VERSION ""

NS_ :

BS_:

BU_: Tester RTM MP5 PEPS BCM IC ACM1 GW

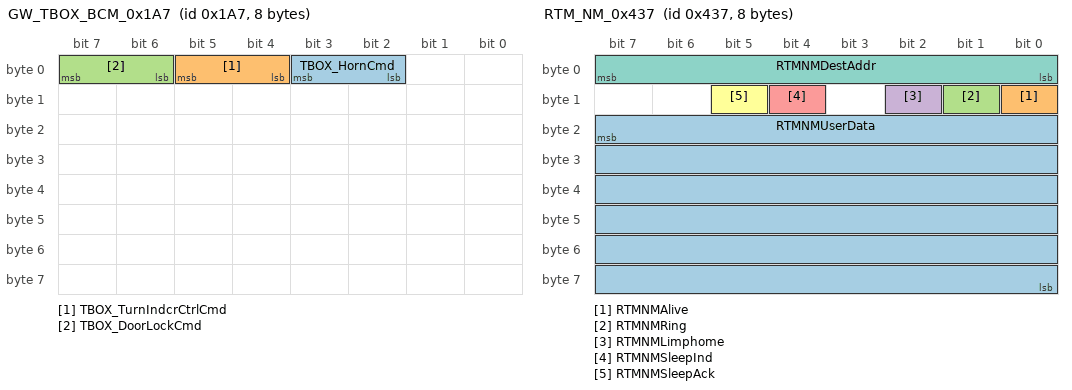
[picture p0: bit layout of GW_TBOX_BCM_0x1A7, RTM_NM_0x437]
BO_ 423 GW_TBOX_BCM_0x1A7: 8 GW
 SG_ TBOX_HornCmd : 3|2@0+ (1,0) [0|3] ""  BCM
 SG_ TBOX_TurnIndcrCtrlCmd : 5|2@0+ (1,0) [0|3] ""  BCM
 SG_ TBOX_DoorLockCmd : 7|2@0+ (1,0) [0|3] ""  BCM

BO_ 1899 GW_TBOXDiagResp: 8 GW
 SG_ DiagRespFromTBOX : 7|64@0+ (1,0) [0|1.844674407371E+019] ""  Tester

BO_ 1891 Tester_DiagReqToTBOX: 8 Tester
 SG_ DiagPhysReqToTBOX : 7|64@0+ (1,0) [0|1.844674407371E+019] ""  GW

BO_ 1851 RTM_DiagResp: 8 RTM
 SG_ DiagRespFromRTM : 7|64@0+ (1,0) [0|1.844674407371E+019] ""  Tester

BO_ 1843 Tester_DiagReqToRTM: 8 Tester
 SG_ DiagPhysReqToRTM : 7|64@0+ (1,0) [0|1.844674407371E+019] ""  RTM

BO_ 1839 MP5_DiagResp: 8 MP5
 SG_ DiagRespFromMP5 : 7|64@0+ (1,0) [0|1.844674407371E+019] ""  Tester

BO_ 1831 Tester_DiagReqToMP5: 8 Tester
 SG_ DiagPhysReqToMP5 : 7|64@0+ (1,0) [0|1.844674407371E+019] ""  MP5

BO_ 1850 PEPS_DiagResp: 8 PEPS
 SG_ DiagRespFromPEPS : 7|64@0+ (1,0) [0|1.844674407371E+019] ""  Tester

BO_ 1842 Tester_DiagReqToPEPS: 8 Tester
 SG_ DiagPhysReqToPEPS : 7|64@0+ (1,0) [0|1.844674407371E+019] ""  PEPS

BO_ 1848 IC_DiagResp: 8 IC
 SG_ DiagRespFromIC : 7|64@0+ (1,0) [0|1.844674407371E+019] ""  Tester

BO_ 1840 Tester_DiagReqToIC: 8 Tester
 SG_ DiagPhysReqToIC : 7|64@0+ (1,0) [0|1.844674407371E+019] ""  IC

BO_ 1865 AC_DiagResp: 8 ACM1
 SG_ DiagRespFromAC : 7|64@0+ (1,0) [0|1.844674407371E+019] ""  Tester

BO_ 1857 Tester_DiagReqToAC: 8 Tester
 SG_ DiagPhysReqToAC : 7|64@0+ (1,0) [0|1.844674407371E+019] ""  ACM1

BO_ 1849 BCM_DiagResp: 8 BCM
 SG_ DiagRespFromBCM : 7|64@0+ (1,0) [0|1.844674407371E+019] ""  Tester

BO_ 1841 Tester_DiagReqToBCM: 8 Tester
 SG_ DiagPhysReqToBCM : 7|64@0+ (1,0) [0|1.844674407371E+019] ""  BCM

BO_ 2015 Tester_DiagFuncReq: 8 Tester
 SG_ DiagFuncReq : 7|64@0+ (1,0) [0|1.844674407371E+019] ""  RTM,MP5,PEPS,BCM,IC,ACM1,GW

BO_ 1079 RTM_NM_0x437: 8 RTM
 SG_ RTMNMUserData : 23|48@0+ (1,0) [0|2.8147E+014] ""  MP5,PEPS,BCM,IC,GW
 SG_ RTMNMAlive : 8|1@0+ (1,0) [0|1] ""  MP5,PEPS,BCM,IC,GW
 SG_ RTMNMRing : 9|1@0+ (1,0) [0|1] ""  MP5,PEPS,BCM,IC,GW
 SG_ RTMNMLimphome : 10|1@0+ (1,0) [0|1] ""  MP5,PEPS,BCM,IC,GW
 SG_ RTMNMSleepInd : 12|1@0+ (1,0) [0|1] ""  MP5,PEPS,BCM,IC,GW
 SG_ RTMNMSleepAck : 13|1@0+ (1,0) [0|1] ""  MP5,PEPS,BCM,IC,GW
 SG_ RTMNMDestAddr : 7|8@0+ (1,0) [0|255] ""  MP5,PEPS,BCM,IC,GW

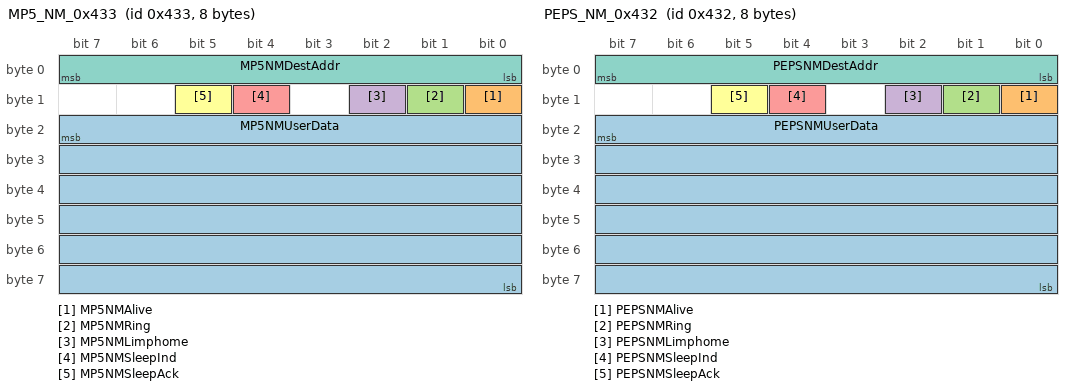
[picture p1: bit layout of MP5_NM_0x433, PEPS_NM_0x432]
BO_ 1075 MP5_NM_0x433: 8 MP5
 SG_ MP5NMUserData : 23|48@0+ (1,0) [0|2.8147E+014] ""  RTM,PEPS,BCM,IC,GW
 SG_ MP5NMAlive : 8|1@0+ (1,0) [0|1] ""  RTM,PEPS,BCM,IC,GW
 SG_ MP5NMRing : 9|1@0+ (1,0) [0|1] ""  RTM,PEPS,BCM,IC,GW
 SG_ MP5NMLimphome : 10|1@0+ (1,0) [0|1] ""  RTM,PEPS,BCM,IC,GW
 SG_ MP5NMSleepInd : 12|1@0+ (1,0) [0|1] ""  RTM,PEPS,BCM,IC,GW
 SG_ MP5NMSleepAck : 13|1@0+ (1,0) [0|1] ""  RTM,PEPS,BCM,IC,GW
 SG_ MP5NMDestAddr : 7|8@0+ (1,0) [0|255] ""  RTM,PEPS,BCM,IC,GW

BO_ 1074 PEPS_NM_0x432: 8 PEPS
 SG_ PEPSNMUserData : 23|48@0+ (1,0) [0|2.8147E+014] ""  RTM,MP5,BCM,IC,GW
 SG_ PEPSNMAlive : 8|1@0+ (1,0) [0|1] ""  RTM,MP5,BCM,IC,GW
 SG_ PEPSNMRing : 9|1@0+ (1,0) [0|1] ""  RTM,MP5,BCM,IC,GW
 SG_ PEPSNMLimphome : 10|1@0+ (1,0) [0|1] ""  RTM,MP5,BCM,IC,GW
 SG_ PEPSNMSleepInd : 12|1@0+ (1,0) [0|1] ""  RTM,MP5,BCM,IC,GW
 SG_ PEPSNMSleepAck : 13|1@0+ (1,0) [0|1] ""  RTM,MP5,BCM,IC,GW
 SG_ PEPSNMDestAddr : 7|8@0+ (1,0) [0|255] ""  RTM,MP5,BCM,IC,GW

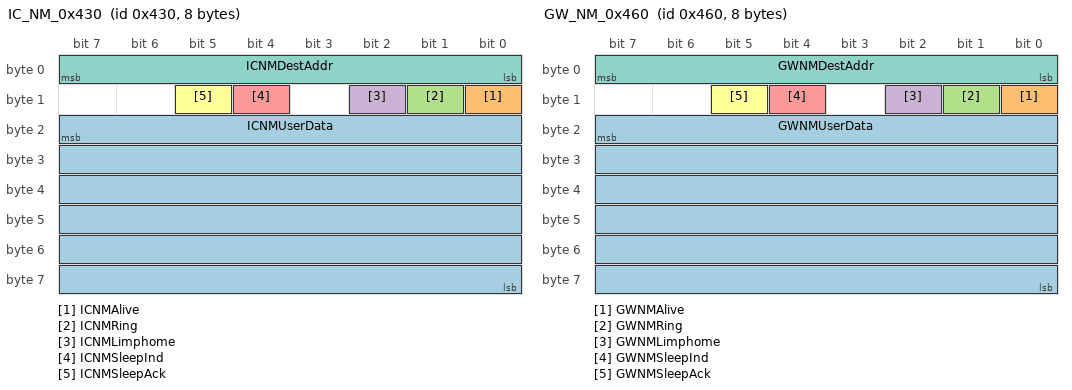
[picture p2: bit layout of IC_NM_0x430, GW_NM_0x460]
BO_ 1072 IC_NM_0x430: 8 IC
 SG_ ICNMUserData : 23|48@0+ (1,0) [0|2.8147E+014] ""  RTM,MP5,PEPS,BCM,GW
 SG_ ICNMAlive : 8|1@0+ (1,0) [0|1] ""  RTM,MP5,PEPS,BCM,GW
 SG_ ICNMRing : 9|1@0+ (1,0) [0|1] ""  RTM,MP5,PEPS,BCM,GW
 SG_ ICNMLimphome : 10|1@0+ (1,0) [0|1] ""  RTM,MP5,PEPS,BCM,GW
 SG_ ICNMSleepInd : 12|1@0+ (1,0) [0|1] ""  RTM,MP5,PEPS,BCM,GW
 SG_ ICNMSleepAck : 13|1@0+ (1,0) [0|1] ""  RTM,MP5,PEPS,BCM,GW
 SG_ ICNMDestAddr : 7|8@0+ (1,0) [0|255] ""  RTM,MP5,PEPS,BCM,GW

BO_ 1120 GW_NM_0x460: 8 GW
 SG_ GWNMUserData : 23|48@0+ (1,0) [0|2.8147E+014] ""  RTM,MP5,PEPS,BCM,IC
 SG_ GWNMAlive : 8|1@0+ (1,0) [0|1] ""  RTM,MP5,PEPS,BCM,IC
 SG_ GWNMRing : 9|1@0+ (1,0) [0|1] ""  RTM,MP5,PEPS,BCM,IC
 SG_ GWNMLimphome : 10|1@0+ (1,0) [0|1] ""  RTM,MP5,PEPS,BCM,IC
 SG_ GWNMSleepInd : 12|1@0+ (1,0) [0|1] ""  RTM,MP5,PEPS,BCM,IC
 SG_ GWNMSleepAck : 13|1@0+ (1,0) [0|1] ""  RTM,MP5,PEPS,BCM,IC
 SG_ GWNMDestAddr : 7|8@0+ (1,0) [0|255] ""  RTM,MP5,PEPS,BCM,IC

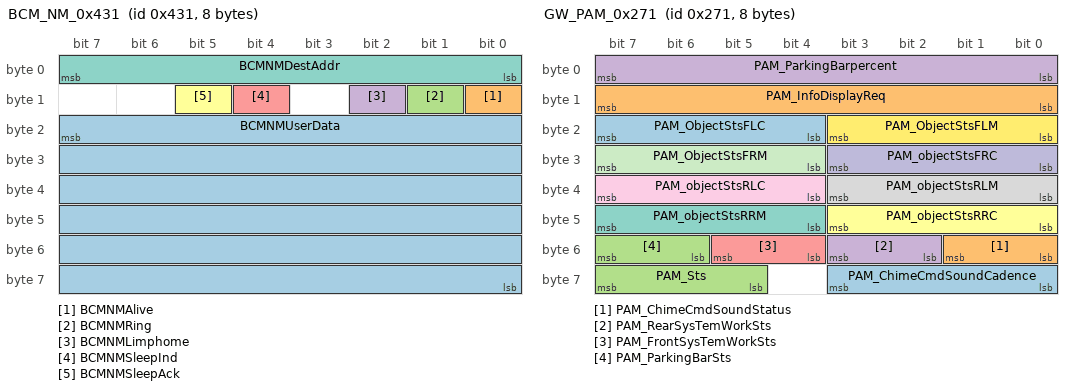
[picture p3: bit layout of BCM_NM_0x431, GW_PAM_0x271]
BO_ 1073 BCM_NM_0x431: 8 BCM
 SG_ BCMNMUserData : 23|48@0+ (1,0) [0|2.8147E+014] ""  RTM,MP5,PEPS,IC,GW
 SG_ BCMNMAlive : 8|1@0+ (1,0) [0|1] ""  RTM,MP5,PEPS,IC,GW
 SG_ BCMNMRing : 9|1@0+ (1,0) [0|1] ""  RTM,MP5,PEPS,IC,GW
 SG_ BCMNMLimphome : 10|1@0+ (1,0) [0|1] ""  RTM,MP5,PEPS,IC,GW
 SG_ BCMNMSleepInd : 12|1@0+ (1,0) [0|1] ""  RTM,MP5,PEPS,IC,GW
 SG_ BCMNMSleepAck : 13|1@0+ (1,0) [0|1] ""  RTM,MP5,PEPS,IC,GW
 SG_ BCMNMDestAddr : 7|8@0+ (1,0) [0|255] ""  RTM,MP5,PEPS,IC,GW

BO_ 96 GW_EMS_Power_0x60: 8 GW
 SG_ EMS_EngAuthentResult : 6|2@0+ (1,0) [0|2] ""  PEPS

BO_ 581 GW_IPM_0x245: 8 GW
 SG_ Checksum_0x245 : 63|8@0+ (1,0) [0|255] ""  MP5,BCM,IC
 SG_ Rolling_counter_0x245 : 51|4@0+ (1,0) [0|15] ""  MP5,BCM,IC
 SG_ IPM_LDWWarningType : 53|2@0+ (1,0) [0|3] ""  MP5
 SG_ IPM_HMA_HighbeamReq : 55|1@0+ (1,0) [0|1] ""  BCM
 SG_ IPM_HMA_Status : 42|3@0+ (1,0) [0|7] ""  MP5,BCM,IC
 SG_ IPM_LaneAssit_TorqueReqStatus : 11|2@0+ (1,0) [0|3] "" Vector__XXX
 SG_ IPM_LaneAssit_TorqueValidity : 12|1@0+ (1,0) [0|1] "" Vector__XXX
 SG_ IPM_LaneAssit_TorqueReq : 7|11@0+ (0.01,-10.24) [-10.24|10.23] "Nm" Vector__XXX
 SG_ IPM_DDD_IndexStatus : 44|2@0+ (1,0) [0|3] ""  MP5,IC
 SG_ IPM_DDD_WarningLevel : 47|3@0+ (1,0) [0|6] ""  MP5,IC
 SG_ IPM_SLASpdlimitUnits : 25|2@0+ (1,0) [0|3] ""  MP5,IC
 SG_ IPM_SLASpdlimit : 39|8@0+ (1,0) [0|255] ""  MP5,IC
 SG_ IPM_SLAState : 28|3@0+ (1,0) [0|7] ""  MP5,IC
 SG_ IPM_LaneAssit_WarningVibration : 9|1@0+ (1,0) [0|1] "" Vector__XXX
 SG_ IPM_LaneAssit_WarningAudio : 17|1@0+ (1,0) [0|1] ""  IC
 SG_ IPM_LaneAssit_Status : 31|3@0+ (1,0) [0|7] ""  BCM,IC
 SG_ IPM_LaneAssit_HandsonReq : 54|1@0+ (1,0) [0|1] ""  IC
 SG_ IPM_LaneAssit_Sensitivity : 16|1@0+ (1,0) [0|1] ""  MP5
 SG_ IPM_LaneAssitType : 8|3@0+ (1,0) [0|7] ""  MP5,IC
 SG_ IPM_LaneAssit_RightVisualization : 21|2@0+ (1,0) [0|3] ""  IC
 SG_ IPM_LaneAssit_LeftVisualization : 19|2@0+ (1,0) [0|3] ""  IC

BO_ 629 GW_SOD_0x275: 8 GW
 SG_ Checksum_0x275 : 63|8@0+ (1,0) [0|255] ""  MP5,IC
 SG_ Rolling_counter_0x275 : 51|4@0+ (1,0) [0|15] ""  MP5,IC
 SG_ DOA_OFFTelltale : 29|1@0+ (1,0) [0|1] ""  IC
 SG_ CTA_OFFTelltale : 30|1@0+ (1,0) [0|1] ""  IC
 SG_ SODLCA_OFFTelltale : 31|1@0+ (1,0) [0|1] ""  IC
 SG_ SOD_LCA_warningReqLeft : 17|2@0+ (1,0) [0|3] ""  IC
 SG_ SOD_DOA_warningReqLeftRear : 19|2@0+ (1,0) [0|3] ""  IC
 SG_ SOD_DOA_warningReqLeftFront : 21|2@0+ (1,0) [0|3] ""  IC
 SG_ SOD_CTA_warningReqLeft : 23|2@0+ (1,0) [0|3] ""  IC
 SG_ SOD_AutoAlignmentFlag : 9|2@0+ (1,0) [0|3] "" Vector__XXX
 SG_ SOD_BLIS_Active : 11|2@0+ (1,0) [0|3] "" Vector__XXX
 SG_ SOD_BLIS_display : 15|4@0+ (1,0) [0|15] ""  IC
 SG_ SOD_LCA_warningReqRight : 1|2@0+ (1,0) [0|3] ""  IC
 SG_ SOD_DOA_State : 26|1@0+ (1,0) [0|1] ""  MP5
 SG_ SOD_CTA_State : 27|1@0+ (1,0) [0|1] ""  MP5
 SG_ SOD_SODLCA_State : 28|1@0+ (1,0) [0|1] ""  MP5
 SG_ SOD_DOA_warningReqRightRear : 3|2@0+ (1,0) [0|3] ""  IC
 SG_ SOD_DOA_warningReqRightFront : 5|2@0+ (1,0) [0|3] ""  IC
 SG_ SOD_CTA_warningReqRight : 7|2@0+ (1,0) [0|3] ""  IC

BO_ 625 GW_PAM_0x271: 8 GW
 SG_ PAM_ChimeCmdSoundCadence : 59|4@0+ (1,0) [0|14] ""  MP5,IC
 SG_ PAM_ChimeCmdSoundStatus : 49|2@0+ (1,0) [0|3] ""  MP5,IC
 SG_ PAM_Sts : 63|3@0+ (1,0) [0|7] "" Vector__XXX
 SG_ PAM_RearSysTemWorkSts : 51|2@0+ (1,0) [0|3] ""  MP5,IC
 SG_ PAM_FrontSysTemWorkSts : 53|2@0+ (1,0) [0|3] "" Vector__XXX
 SG_ PAM_objectStsRRC : 43|4@0+ (1,0) [0|15] ""  MP5
 SG_ PAM_objectStsRRM : 47|4@0+ (1,0) [0|15] ""  MP5
 SG_ PAM_objectStsRLM : 35|4@0+ (1,0) [0|15] ""  MP5
 SG_ PAM_objectStsRLC : 39|4@0+ (1,0) [0|15] ""  MP5
 SG_ PAM_objectStsFRC : 27|4@0+ (1,0) [0|15] "" Vector__XXX
 SG_ PAM_ObjectStsFRM : 31|4@0+ (1,0) [0|15] "" Vector__XXX
 SG_ PAM_ObjectStsFLM : 19|4@0+ (1,0) [0|15] "" Vector__XXX
 SG_ PAM_ObjectStsFLC : 23|4@0+ (1,0) [0|15] "" Vector__XXX
 SG_ PAM_InfoDisplayReq : 15|8@0+ (1,0) [0|255] "" Vector__XXX
 SG_ PAM_ParkingBarSts : 55|2@0+ (1,0) [0|2] "" Vector__XXX
 SG_ PAM_ParkingBarpercent : 7|8@0+ (1,0) [0|100] "%" Vector__XXX

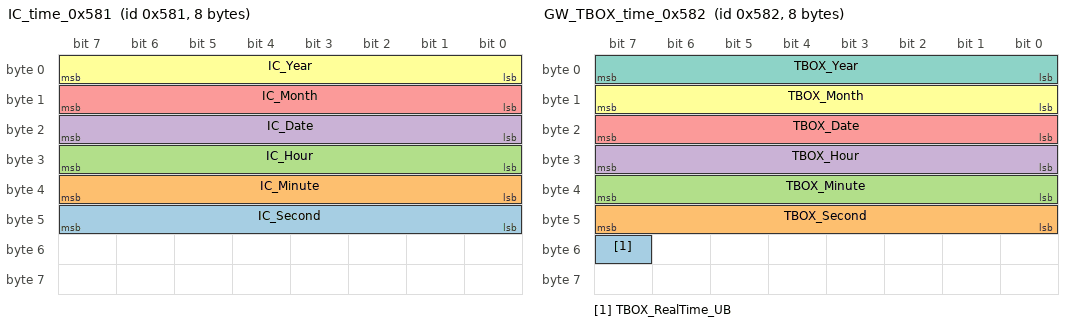
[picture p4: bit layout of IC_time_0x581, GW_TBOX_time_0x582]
BO_ 1409 IC_time_0x581: 8 IC
 SG_ IC_Second : 47|8@0+ (1,0) [0|59] ""  MP5,GW
 SG_ IC_Minute : 39|8@0+ (1,0) [0|59] ""  MP5,GW
 SG_ IC_Hour : 31|8@0+ (1,0) [0|23] ""  MP5,GW
 SG_ IC_Date : 23|8@0+ (1,1) [1|31] ""  MP5,GW
 SG_ IC_Month : 15|8@0+ (1,1) [1|12] ""  MP5,GW
 SG_ IC_Year : 7|8@0+ (1,2017) [2017|2272] ""  MP5,GW

BO_ 1410 GW_TBOX_time_0x582: 8 GW
 SG_ TBOX_RealTime_UB : 55|1@0+ (1,0) [0|1] ""  IC
 SG_ TBOX_Second : 47|8@0+ (1,0) [0|59] ""  IC
 SG_ TBOX_Minute : 39|8@0+ (1,0) [0|59] ""  IC
 SG_ TBOX_Hour : 31|8@0+ (1,0) [0|23] ""  IC
 SG_ TBOX_Date : 23|8@0+ (1,1) [1|31] ""  IC
 SG_ TBOX_Month : 15|8@0+ (1,1) [1|12] ""  IC
 SG_ TBOX_Year : 7|8@0+ (1,2017) [2017|2272] ""  IC

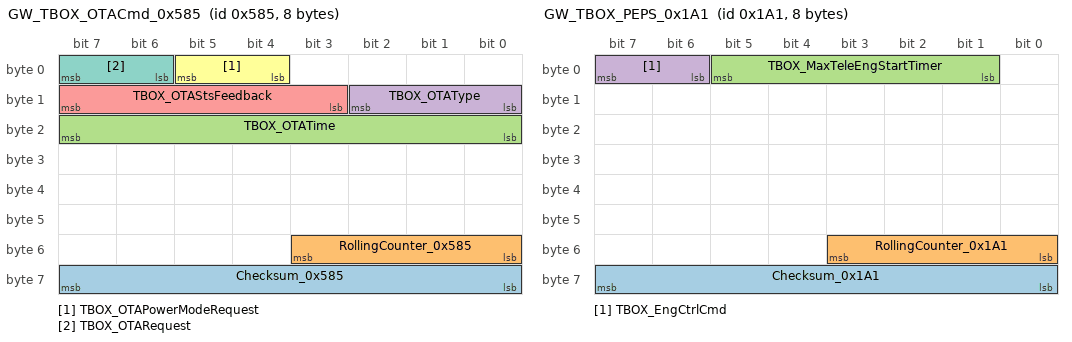
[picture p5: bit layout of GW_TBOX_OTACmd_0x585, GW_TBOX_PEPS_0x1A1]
BO_ 1413 GW_TBOX_OTACmd_0x585: 8 GW
 SG_ Checksum_0x585 : 63|8@0+ (1,0) [0|255] ""  PEPS,BCM
 SG_ RollingCounter_0x585 : 51|4@0+ (1,0) [0|15] ""  PEPS,BCM
 SG_ TBOX_OTATime : 23|8@0+ (1,0) [0|255] "min"  BCM
 SG_ TBOX_OTAType : 10|3@0+ (1,0) [0|7] ""  PEPS,BCM
 SG_ TBOX_OTAStsFeedback : 15|5@0+ (1,0) [0|31] "" Vector__XXX
 SG_ TBOX_OTAPowerModeRequest : 5|2@0+ (1,0) [0|3] ""  PEPS,BCM
 SG_ TBOX_OTARequest : 7|2@0+ (1,0) [0|3] ""  PEPS,BCM

BO_ 419 GW_TBOX_0x1A3: 8 GW
 SG_ TBOX_PEPSAuth : 7|64@0+ (1,0) [0|1.8447E+019] ""  PEPS

BO_ 418 GW_TBOX_AC_0x1A2: 8 GW
 SG_ TBOX_AcWorkCmd : 7|3@0+ (1,0) [0|7] ""  MP5,ACM1

BO_ 417 GW_TBOX_PEPS_0x1A1: 8 GW
 SG_ Checksum_0x1A1 : 63|8@0+ (1,0) [0|255] ""  PEPS
 SG_ RollingCounter_0x1A1 : 51|4@0+ (1,0) [0|15] ""  PEPS
 SG_ TBOX_MaxTeleEngStartTimer : 5|5@0+ (1,0) [0|31] "min"  PEPS
 SG_ TBOX_EngCtrlCmd : 7|2@0+ (1,0) [0|3] ""  PEPS,BCM

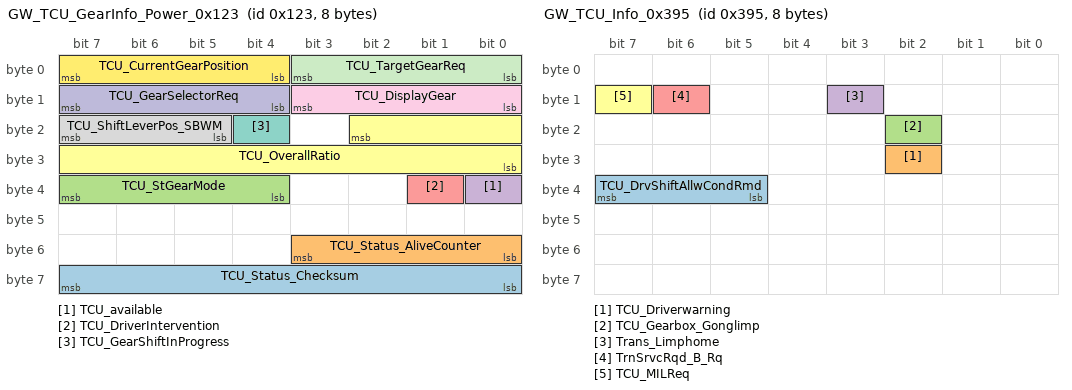
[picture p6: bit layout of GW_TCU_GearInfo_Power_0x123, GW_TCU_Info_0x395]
BO_ 291 GW_TCU_GearInfo_Power_0x123: 8 GW
 SG_ TCU_Status_Checksum : 63|8@0+ (1,0) [0|255] ""  PEPS,BCM,IC
 SG_ TCU_Status_AliveCounter : 51|4@0+ (1,0) [0|15] ""  PEPS,BCM,IC
 SG_ TCU_StGearMode : 39|4@0+ (1,0) [0|15] ""  IC
 SG_ TCU_available : 32|1@0+ (1,0) [0|1] "" Vector__XXX
 SG_ TCU_DriverIntervention : 33|1@0+ (1,0) [0|1] "" Vector__XXX
 SG_ TCU_OverallRatio : 18|11@0+ (0.01,0) [0|20] "" Vector__XXX
 SG_ TCU_GearShiftInProgress : 20|1@0+ (1,0) [0|1] "" Vector__XXX
 SG_ TCU_ShiftLeverPos_SBWM : 23|3@0+ (1,0) [0|7] "/" Vector__XXX
 SG_ TCU_DisplayGear : 11|4@0+ (1,0) [0|15] ""  IC
 SG_ TCU_GearSelectorReq : 15|4@0+ (1,0) [0|15] ""  PEPS,BCM
 SG_ TCU_TargetGearReq : 3|4@0+ (1,0) [0|15] "" Vector__XXX
 SG_ TCU_CurrentGearPosition : 7|4@0+ (1,0) [0|15] "" Vector__XXX

BO_ 917 GW_TCU_Info_0x395: 8 GW
 SG_ TCU_DrvShiftAllwCondRmd : 39|3@0+ (1,0) [0|7] ""  IC
 SG_ TCU_Driverwarning : 26|1@0+ (1,0) [0|1] ""  IC
 SG_ TCU_Gearbox_Gonglimp : 18|1@0+ (1,0) [0|1] ""  IC
 SG_ Trans_Limphome : 11|1@0+ (1,0) [0|1] ""  IC
 SG_ TrnSrvcRqd_B_Rq : 14|1@0+ (1,0) [0|1] "SED"  IC
 SG_ TCU_MILReq : 15|1@0+ (1,0) [0|1] ""  IC

BO_ 1590 GW_EMS_0x636: 8 GW
 SG_ EMS_BackupOdometer : 7|32@0+ (0.1,0) [0|999999] "km"  IC

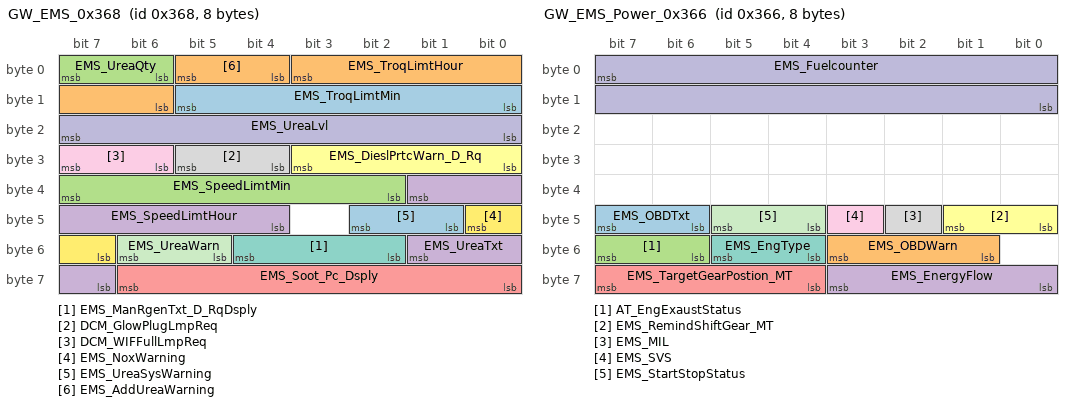
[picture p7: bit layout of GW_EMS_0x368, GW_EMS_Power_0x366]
BO_ 872 GW_EMS_0x368: 8 GW
 SG_ EMS_TroqLimtMin : 13|6@0+ (1,0) [0|62] "min"  IC
 SG_ EMS_TroqLimtHour : 3|6@0+ (1,0) [0|62] "h"  IC
 SG_ EMS_SpeedLimtMin : 39|6@0+ (1,0) [0|62] "min"  IC
 SG_ EMS_SpeedLimtHour : 33|6@0+ (1,0) [0|62] "h"  IC
 SG_ EMS_Soot_Pc_Dsply : 62|7@0+ (1,0) [0|126] ""  IC
 SG_ EMS_DieslPrtcWarn_D_Rq : 27|4@0+ (1,0) [0|15] ""  IC
 SG_ EMS_ManRgenTxt_D_RqDsply : 52|3@0+ (1,0) [0|7] ""  IC
 SG_ DCM_GlowPlugLmpReq : 29|2@0+ (1,0) [0|3] ""  IC
 SG_ DCM_WIFFullLmpReq : 31|2@0+ (1,0) [0|3] ""  IC
 SG_ EMS_UreaLvl : 23|8@0+ (0.4,0) [0|100] "%"  IC
 SG_ EMS_UreaWarn : 54|2@0+ (1,0) [0|3] "" Vector__XXX
 SG_ EMS_NoxWarning : 40|2@0+ (1,0) [0|3] "" Vector__XXX
 SG_ EMS_UreaSysWarning : 42|2@0+ (1,0) [0|3] ""  IC
 SG_ EMS_AddUreaWarning : 5|2@0+ (1,0) [0|3] "" Vector__XXX
 SG_ EMS_UreaQty : 7|2@0+ (1,0) [0|3] ""  IC
 SG_ EMS_UreaTxt : 49|3@0+ (1,0) [0|7] ""  IC

BO_ 870 GW_EMS_Power_0x366: 8 GW
 SG_ EMS_OBDTxt : 47|2@0+ (1,0) [0|3] ""  IC
 SG_ EMS_OBDWarn : 51|3@0+ (1,0) [0|7] "" Vector__XXX
 SG_ AT_EngExaustStatus : 55|2@0+ (1,0) [0|3] "" Vector__XXX
 SG_ EMS_EnergyFlow : 59|4@0+ (1,0) [0|15] "" Vector__XXX
 SG_ EMS_TargetGearPostion_MT : 63|4@0+ (1,0) [0|15] "" Vector__XXX
 SG_ EMS_RemindShiftGear_MT : 41|2@0+ (1,0) [0|3] ""  IC
 SG_ EMS_EngType : 53|2@0+ (1,0) [0|3] "" Vector__XXX
 SG_ EMS_MIL : 42|1@0+ (1,0) [0|1] ""  IC
 SG_ EMS_SVS : 43|1@0+ (1,0) [0|1] ""  IC
 SG_ EMS_Fuelcounter : 7|16@0+ (2,0) [0|131070] "uL"  IC
 SG_ EMS_StartStopStatus : 45|2@0+ (1,0) [0|3] "" Vector__XXX

BO_ 99 GW_EMS_Power_0x63_valeo: 8 GW
 SG_ EMS_SentSK64 : 7|64@0+ (1,0) [0|1.844674407371E+019] ""  PEPS,BCM

BO_ 98 GW_EMS_Power_0x62_valeo: 8 GW
 SG_ EMS_Eng_PEPSAuth : 7|64@0+ (1,0) [0|1.844674407371E+019] ""  PEPS,BCM

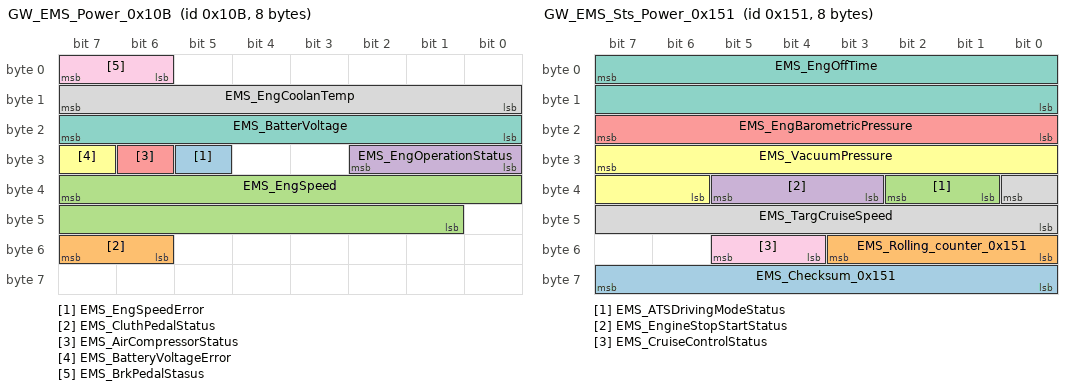
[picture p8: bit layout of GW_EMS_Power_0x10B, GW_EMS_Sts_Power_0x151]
BO_ 267 GW_EMS_Power_0x10B: 8 GW
 SG_ EMS_EngSpeedError : 29|1@0+ (1,0) [0|1] ""  PEPS,IC
 SG_ EMS_CluthPedalStatus : 55|2@0+ (1,0) [0|3] ""  IC
 SG_ EMS_EngSpeed : 39|15@0+ (0.5,0) [0|16383] "rpm"  PEPS,BCM,IC,ACM1
 SG_ EMS_EngOperationStatus : 26|3@0+ (1,0) [0|5] ""  PEPS,BCM,ACM1
 SG_ EMS_AirCompressorStatus : 30|1@0+ (1,0) [0|1] "" Vector__XXX
 SG_ EMS_BatteryVoltageError : 31|1@0+ (1,0) [0|1] ""  IC
 SG_ EMS_BatterVoltage : 23|8@0+ (0.07,0) [0|17.85] "V" Vector__XXX
 SG_ EMS_EngCoolanTemp : 15|8@0+ (0.75,-48) [-48|142.5] "deg C"  IC,ACM1
 SG_ EMS_BrkPedalStasus : 7|2@0+ (1,0) [0|3] ""  PEPS,BCM,IC

BO_ 337 GW_EMS_Sts_Power_0x151: 8 GW
 SG_ EMS_Checksum_0x151 : 63|8@0+ (1,0) [0|255] ""  IC
 SG_ EMS_Rolling_counter_0x151 : 51|4@0+ (1,0) [0|15] ""  IC
 SG_ EMS_ATSDrivingModeStatus : 34|2@0+ (1,0) [0|3] "" Vector__XXX
 SG_ EMS_EngineStopStartStatus : 37|3@0+ (1,0) [0|7] "" Vector__XXX
 SG_ EMS_EngBarometricPressure : 23|8@0+ (1,0) [0|254] "Kpa" Vector__XXX
 SG_ EMS_VacuumPressure : 31|10@0+ (0.1,-97.2) [-97.2|5] "Kpa" Vector__XXX
 SG_ EMS_EngOffTime : 7|16@0+ (1,0) [0|65534] "s" Vector__XXX
 SG_ EMS_TargCruiseSpeed : 32|9@0+ (0.5,0) [0|255] "Km/h"  IC
 SG_ EMS_CruiseControlStatus : 53|2@0+ (1,0) [0|3] ""  IC

BO_ 582 GW_MRR_Chassis_0x246: 8 GW
 SG_ MRR_Checksum_0x246 : 63|8@0+ (1,0) [0|255] ""  IC
 SG_ MRR_Rolling_counter_0x246 : 51|4@0+ (1,0) [0|15] ""  IC
 SG_ FCW_preWarning : 35|1@0+ (1,0) [0|1] ""  IC
 SG_ FCW_latentWarning : 36|1@0+ (1,0) [0|1] ""  IC
 SG_ MRR_Obj_Speed : 47|8@0+ (1,0) [0|255] "" Vector__XXX
 SG_ MRR_PCW_STATE : 39|3@0+ (1,0) [0|7] ""  MP5,IC
 SG_ MRR_AEB_STATE : 27|3@0+ (1,0) [0|7] ""  MP5,IC
 SG_ MRR_ACC_Startstop_infor : 29|2@0+ (1,0) [0|3] "" Vector__XXX
 SG_ MRR_PCW_preWarning : 30|1@0+ (1,0) [0|1] ""  IC
 SG_ MRR_PCW_latentWarning : 31|1@0+ (1,0) [0|1] ""  IC
 SG_ ACCHMI_Mode : 18|3@0+ (1,0) [0|7] ""  IC
 SG_ MRR_FCW_Sensitive : 23|2@0+ (1,0) [0|3] ""  MP5
 SG_ MRR_ACCFailInfo : 19|1@0+ (1,0) [0|1] "" Vector__XXX
 SG_ MRR_TakeOverReq : 20|1@0+ (1,0) [0|1] ""  IC
 SG_ Textinfo : 55|4@0+ (1,0) [0|15] ""  IC
 SG_ MRR_ObjValid : 8|1@0+ (1,0) [0|1] ""  IC
 SG_ MRR_TauGapSet : 11|3@0+ (1,0) [0|7] ""  IC
 SG_ MRR_dxTarObj : 14|3@0+ (1,0) [0|7] ""  IC
 SG_ MRR_vSetDis : 7|9@0+ (0.5,0) [0|255.5] "kph"  IC

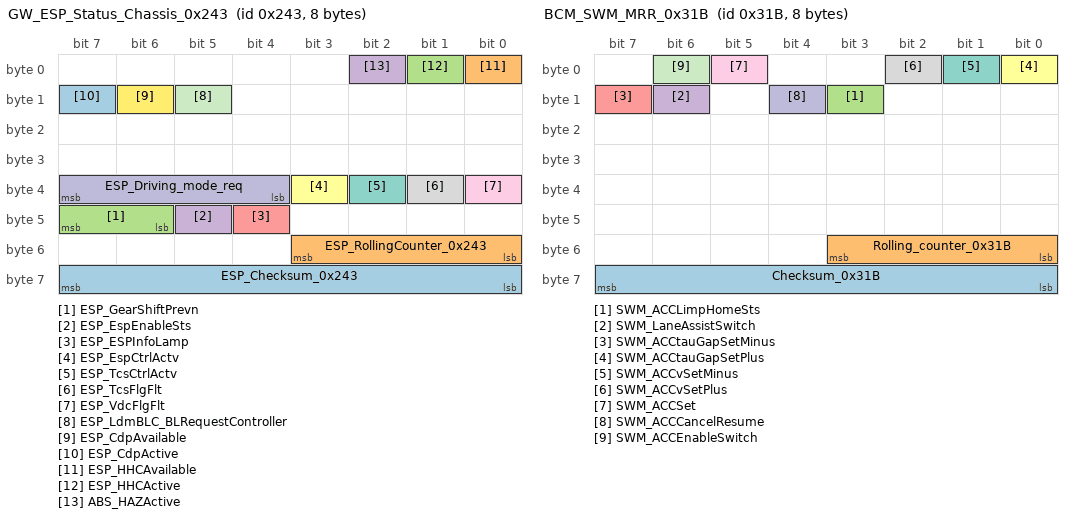
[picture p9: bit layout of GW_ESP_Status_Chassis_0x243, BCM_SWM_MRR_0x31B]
BO_ 579 GW_ESP_Status_Chassis_0x243: 8 GW
 SG_ ESP_Checksum_0x243 : 63|8@0+ (1,0) [0|255] ""  BCM,IC
 SG_ ESP_RollingCounter_0x243 : 51|4@0+ (1,0) [0|15] ""  BCM,IC
 SG_ ESP_GearShiftPrevn : 47|2@0+ (1,0) [0|3] "" Vector__XXX
 SG_ ESP_EspEnableSts : 45|1@0+ (1,0) [0|1] ""  IC
 SG_ ESP_ESPInfoLamp : 44|1@0+ (1,0) [0|1] ""  IC
 SG_ ESP_EspCtrlActv : 35|1@0+ (1,0) [0|1] "" Vector__XXX
 SG_ ESP_TcsCtrlActv : 34|1@0+ (1,0) [0|1] "" Vector__XXX
 SG_ ESP_TcsFlgFlt : 33|1@0+ (1,0) [0|1] ""  IC
 SG_ ESP_VdcFlgFlt : 32|1@0+ (1,0) [0|1] ""  IC
 SG_ ESP_Driving_mode_req : 39|4@0+ (1,0) [0|15] "" Vector__XXX
 SG_ ESP_LdmBLC_BLRequestController : 13|1@0+ (1,0) [0|1] ""  BCM
 SG_ ESP_CdpAvailable : 14|1@0+ (1,0) [0|1] "" Vector__XXX
 SG_ ESP_CdpActive : 15|1@0+ (1,0) [0|1] "" Vector__XXX
 SG_ ESP_HHCAvailable : 0|1@0+ (1,0) [0|1] "" Vector__XXX
 SG_ ESP_HHCActive : 1|1@0+ (1,0) [0|1] "" Vector__XXX
 SG_ ABS_HAZActive : 2|1@0+ (1,0) [0|1] ""  BCM

BO_ 795 BCM_SWM_MRR_0x31B: 8 BCM
 SG_ Checksum_0x31B : 63|8@0+ (1,0) [0|255] ""  GW
 SG_ Rolling_counter_0x31B : 51|4@0+ (1,0) [0|15] ""  GW
 SG_ SWM_ACCLimpHomeSts : 11|1@0+ (1,0) [0|1] ""  GW
 SG_ SWM_LaneAssistSwitch : 14|1@0+ (1,0) [0|1] ""  GW
 SG_ SWM_ACCtauGapSetMinus : 15|1@0+ (1,0) [0|1] ""  GW
 SG_ SWM_ACCtauGapSetPlus : 0|1@0+ (1,0) [0|1] ""  GW
 SG_ SWM_ACCvSetMinus : 1|1@0+ (1,0) [0|1] ""  GW
 SG_ SWM_ACCvSetPlus : 2|1@0+ (1,0) [0|1] ""  GW
 SG_ SWM_ACCSet : 5|1@0+ (1,0) [0|1] ""  GW
 SG_ SWM_ACCCancelResume : 12|1@0+ (1,0) [0|1] ""  GW
 SG_ SWM_ACCEnableSwitch : 6|1@0+ (1,0) [0|1] ""  GW

BO_ 794 BCM_SWM_Body_0x31A: 8 BCM
 SG_ SWM_Checksum_0x31A : 63|8@0+ (1,0) [0|255] ""  MP5,IC,GW
 SG_ SWM_Rolling_counter_0x31A : 51|4@0+ (1,0) [0|15] ""  MP5,IC,GW
 SG_ SWM_Menu_Confirm : 55|2@0+ (1,0) [0|3] ""  IC,GW
 SG_ SWM_Menu_Right : 41|2@0+ (1,0) [0|3] ""  IC,GW
 SG_ SWM_Menu_Left : 43|2@0+ (1,0) [0|3] ""  IC,GW
 SG_ SWM_Menu_Down : 45|2@0+ (1,0) [0|3] ""  IC,GW
 SG_ SWM_Menu_Up : 47|2@0+ (1,0) [0|3] ""  IC,GW
 SG_ SWM_VOICE : 52|1@0+ (1,0) [0|1] ""  MP5,GW
 SG_ SWM_MODE : 53|1@0+ (1,0) [0|1] ""  MP5,GW
 SG_ SWM_Next_Song : 33|2@0+ (1,0) [0|3] ""  MP5,GW
 SG_ SWM_Previous_Song : 35|2@0+ (1,0) [0|3] ""  MP5,GW
 SG_ SWM_VOL_Plus : 25|2@0+ (1,0) [0|3] ""  MP5,GW
 SG_ SWM_VOL_Minus : 27|2@0+ (1,0) [0|3] ""  MP5,GW
 SG_ SWM_RearFogLight : 17|2@0+ (1,0) [0|3] ""  GW
 SG_ SWM_FrontFogLight : 19|2@0+ (1,0) [0|3] ""  GW
 SG_ SWM_HeadLamp : 31|3@0+ (1,0) [0|7] ""  GW
 SG_ SWM_FlashLightSts : 9|2@0+ (1,0) [0|3] ""  GW
 SG_ SWM_FrontWipingMode : 12|3@0+ (1,0) [0|7] ""  GW
 SG_ SWM_TurnIndicationAct : 23|2@0+ (1,0) [0|3] ""  GW
 SG_ SWM_WipingInterval_Sensitvity : 15|3@0+ (1,0) [0|7] ""  GW
 SG_ SWM_HighBeam : 1|2@0+ (1,0) [0|3] ""  GW
 SG_ SWM_WasherLimpHomeSts : 2|1@0+ (1,0) [0|1] ""  GW
 SG_ SWM_FWasherSts : 5|2@0+ (1,0) [0|3] ""  GW

BO_ 608 GW_EPS_Chassis_0x260: 8 GW
 SG_ EPS_Checksum_0x260 : 63|8@0+ (1,0) [0|255] ""  IC
 SG_ EPS_Rolling_counter_0x260 : 51|4@0+ (1,0) [0|15] ""  IC
 SG_ EPS_N_PerformanceRedu : 47|8@0+ (0.5,0) [0|100] "%" Vector__XXX
 SG_ EPS_SASIndexSts : 54|1@0+ (1,0) [0|1] "" Vector__XXX
 SG_ EPS_N_ECUTemp : 39|8@0+ (1,-70) [-70|185] "Degree" Vector__XXX
 SG_ EPS_F_ECUTempValid : 26|1@0+ (1,0) [0|1] "" Vector__XXX
 SG_ EPS_St_EmergencyPowerLimit : 16|1@0+ (1,0) [0|1] "" Vector__XXX
 SG_ EPS_St_EmergencyMotor : 17|1@0+ (1,0) [0|1] "" Vector__XXX
 SG_ EPS_St_EmergencyECU : 18|1@0+ (1,0) [0|1] "" Vector__XXX
 SG_ EPS_St_EmergencyCANInterface : 19|1@0+ (1,0) [0|1] "" Vector__XXX
 SG_ EPS_St_EmergencySensor : 20|1@0+ (1,0) [0|1] "" Vector__XXX
 SG_ EPS_St_EmergencyOverTemp : 21|1@0+ (1,0) [0|1] "" Vector__XXX
 SG_ EPS_St_EmergencyOverVoltage : 22|1@0+ (1,0) [0|1] "" Vector__XXX
 SG_ EPS_St_EmergencyUnderVoltage : 23|1@0+ (1,0) [0|1] "" Vector__XXX
 SG_ EPS_F_LoadInfo : 8|1@0+ (1,0) [0|1] "" Vector__XXX
 SG_ EPS_N_LoadInfo : 15|7@0+ (1,0) [0|127] "A" Vector__XXX
 SG_ EPS_SASSoftLimitRightFlg : 1|2@0+ (1,0) [0|3] "" Vector__XXX
 SG_ EPS_SASSoftLimitLeftFlg : 3|2@0+ (1,0) [0|3] "" Vector__XXX
 SG_ EPS_St_DTCFlag : 5|1@0+ (1,0) [0|1] "" Vector__XXX
 SG_ EPS_S_WarningLampYellow : 6|1@0+ (1,0) [0|1] ""  IC
 SG_ EPS_S_SafeLampRed : 7|1@0+ (1,0) [0|1] ""  IC

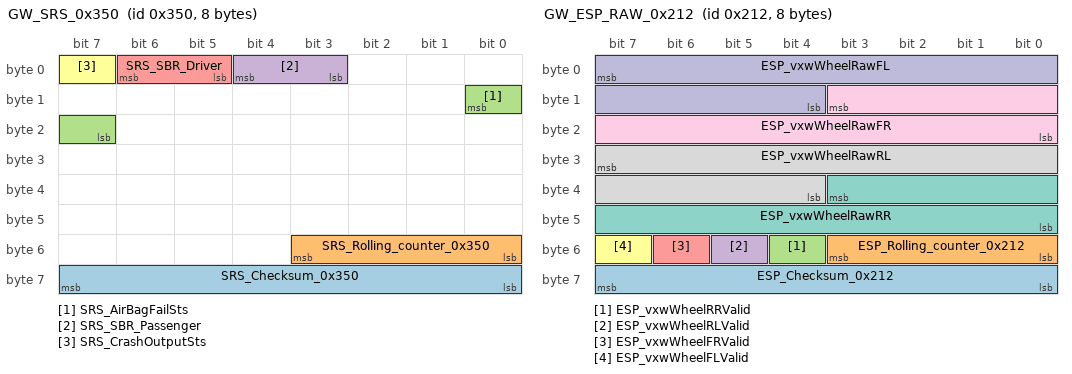
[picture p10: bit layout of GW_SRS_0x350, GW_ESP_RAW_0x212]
BO_ 848 GW_SRS_0x350: 8 GW
 SG_ SRS_Checksum_0x350 : 63|8@0+ (1,0) [0|255] ""  BCM,IC
 SG_ SRS_Rolling_counter_0x350 : 51|4@0+ (1,0) [0|15] ""  BCM,IC
 SG_ SRS_AirBagFailSts : 8|2@0+ (1,0) [0|3] ""  IC
 SG_ SRS_SBR_Passenger : 4|2@0+ (1,0) [0|3] "" Vector__XXX
 SG_ SRS_SBR_Driver : 6|2@0+ (1,0) [0|3] ""  IC
 SG_ SRS_CrashOutputSts : 7|1@0+ (1,0) [0|1] ""  BCM

BO_ 530 GW_ESP_RAW_0x212: 8 GW
 SG_ ESP_Checksum_0x212 : 63|8@0+ (1,0) [0|255] ""  PEPS
 SG_ ESP_Rolling_counter_0x212 : 51|4@0+ (1,0) [0|15] ""  PEPS
 SG_ ESP_vxwWheelRRValid : 52|1@0+ (1,0) [0|1] ""  PEPS
 SG_ ESP_vxwWheelRLValid : 53|1@0+ (1,0) [0|1] ""  PEPS
 SG_ ESP_vxwWheelFRValid : 54|1@0+ (1,0) [0|1] ""  PEPS
 SG_ ESP_vxwWheelFLValid : 55|1@0+ (1,0) [0|1] ""  PEPS
 SG_ ESP_vxwWheelRawRR : 35|12@0+ (0.05625,0) [0|230.2875] "kph"  PEPS
 SG_ ESP_vxwWheelRawRL : 31|12@0+ (0.05625,0) [0|230.2875] "kph"  PEPS
 SG_ ESP_vxwWheelRawFR : 11|12@0+ (0.05625,0) [0|230.2875] "kph"  PEPS
 SG_ ESP_vxwWheelRawFL : 7|12@0+ (0.05625,0) [0|230.2875] "kph"  PEPS

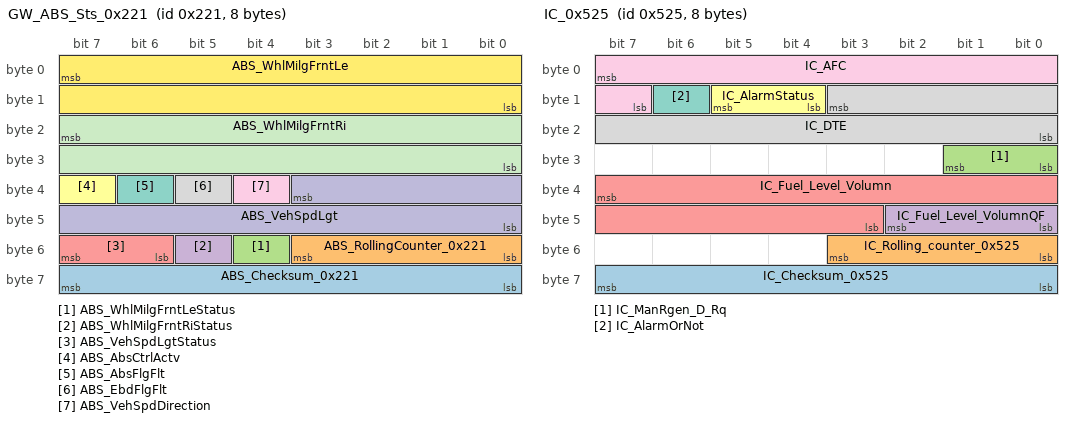
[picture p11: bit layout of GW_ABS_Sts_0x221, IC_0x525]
BO_ 545 GW_ABS_Sts_0x221: 8 GW
 SG_ ABS_Checksum_0x221 : 63|8@0+ (1,0) [0|255] ""  RTM,MP5,PEPS,BCM,IC,ACM1
 SG_ ABS_RollingCounter_0x221 : 51|4@0+ (1,0) [0|15] ""  RTM,MP5,PEPS,BCM,IC,ACM1
 SG_ ABS_WhlMilgFrntLeStatus : 52|1@0+ (1,0) [0|1] ""  IC
 SG_ ABS_WhlMilgFrntRiStatus : 53|1@0+ (1,0) [0|1] ""  IC
 SG_ ABS_VehSpdLgtStatus : 55|2@0+ (1,0) [0|2] ""  MP5,PEPS,ACM1
 SG_ ABS_AbsCtrlActv : 39|1@0+ (1,0) [0|1] "" Vector__XXX
 SG_ ABS_AbsFlgFlt : 38|1@0+ (1,0) [0|1] ""  IC
 SG_ ABS_EbdFlgFlt : 37|1@0+ (1,0) [0|1] ""  IC
 SG_ ABS_VehSpdDirection : 36|1@0+ (1,0) [0|1] "" Vector__XXX
 SG_ ABS_VehSpdLgt : 35|12@0+ (0.05625,0) [0|230.2875] "kph"  RTM,MP5,PEPS,BCM,IC,ACM1
 SG_ ABS_WhlMilgFrntRi : 23|16@0+ (1,0) [0|65535] ""  IC
 SG_ ABS_WhlMilgFrntLe : 7|16@0+ (1,0) [0|65535] ""  IC

BO_ 1317 IC_0x525: 8 IC
 SG_ IC_Checksum_0x525 : 63|8@0+ (1,0) [0|255] ""  MP5,GW
 SG_ IC_Rolling_counter_0x525 : 51|4@0+ (1,0) [0|15] ""  MP5,GW
 SG_ IC_ManRgen_D_Rq : 25|2@0+ (1,0) [0|3] ""  GW
 SG_ IC_Fuel_Level_VolumnQF : 42|3@0+ (1,0) [0|8] ""  GW
 SG_ IC_Fuel_Level_Volumn : 39|13@0+ (0.01,0) [0|81.9] "L"  GW
 SG_ IC_AlarmStatus : 13|2@0+ (1,0) [0|3] ""  MP5
 SG_ IC_AlarmOrNot : 14|1@0+ (1,0) [0|1] ""  MP5
 SG_ IC_DTE : 11|12@0+ (1,0) [0|4094] ""  MP5,GW
 SG_ IC_AFC : 7|9@0+ (0.1,0) [0|51] ""  MP5,GW

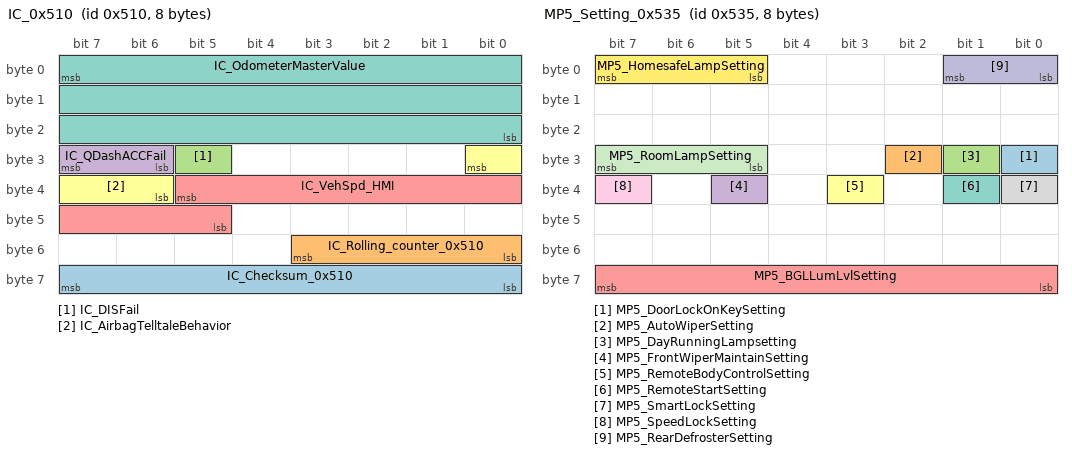
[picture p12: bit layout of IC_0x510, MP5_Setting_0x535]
BO_ 1296 IC_0x510: 8 IC
 SG_ IC_Checksum_0x510 : 63|8@0+ (1,0) [0|255] ""  GW
 SG_ IC_Rolling_counter_0x510 : 51|4@0+ (1,0) [0|15] ""  GW
 SG_ IC_DISFail : 29|1@0+ (1,0) [0|1] ""  GW
 SG_ IC_QDashACCFail : 31|2@0+ (1,0) [0|3] ""  GW
 SG_ IC_VehSpd_HMI : 37|9@0+ (1,0) [0|500] "kph"  GW
 SG_ IC_AirbagTelltaleBehavior : 24|3@0+ (1,0) [0|7] ""  GW
 SG_ IC_OdometerMasterValue : 7|24@0+ (0.1,0) [0|999999] "km"  GW

BO_ 1333 MP5_Setting_0x535: 8 MP5
 SG_ MP5_DoorLockOnKeySetting : 24|1@0+ (1,0) [0|1] ""  BCM
 SG_ MP5_AutoWiperSetting : 26|1@0+ (1,0) [0|1] ""  BCM
 SG_ MP5_DayRunningLampsetting : 25|1@0+ (1,0) [0|1] ""  BCM
 SG_ MP5_FrontWiperMaintainSetting : 37|1@0+ (1,0) [0|1] ""  BCM
 SG_ MP5_BGLLumLvlSetting : 63|8@0+ (1,0) [0|255] "%"  BCM
 SG_ MP5_RemoteBodyControlSetting : 35|1@0+ (1,0) [0|1] ""  BCM
 SG_ MP5_RemoteStartSetting : 33|1@0+ (1,0) [0|1] ""  PEPS
 SG_ MP5_SmartLockSetting : 32|1@0+ (1,0) [0|1] ""  PEPS
 SG_ MP5_SpeedLockSetting : 39|1@0+ (1,0) [0|1] "" Vector__XXX
 SG_ MP5_RearDefrosterSetting : 1|2@0+ (1,0) [0|3] "min"  BCM
 SG_ MP5_RoomLampSetting : 31|3@0+ (1,0) [0|7] "min"  BCM
 SG_ MP5_HomesafeLampSetting : 7|3@0+ (1,0) [0|7] "second"  BCM

BO_ 1415 GW_VIN_0x587: 8 GW
 SG_ VinfoFromGW : 7|64@0+ (1,0) [0|1.844674407371E+019] ""  BCM

BO_ 1330 MP5_Windows_0x532: 8 MP5
 SG_ MP5_DoorLock_Cmd : 3|2@0+ (1,0) [0|3] ""  BCM

BO_ 1328 MP5_0x530: 8 MP5
 SG_ MP5_PrdeProt_ON_OFF : 54|1@0+ (1,0) [0|1] ""  GW
 SG_ MP5_DOA_Active : 55|1@0+ (1,0) [0|1] ""  GW
 SG_ MP5_CTA_Active : 40|1@0+ (1,0) [0|1] ""  GW
 SG_ MP5_BSDLCA_Active : 41|1@0+ (1,0) [0|1] ""  GW
 SG_ MP5_DDDMenuReq : 42|1@0+ (1,0) [0|1] ""  GW
 SG_ MP5_TSRMenuReq : 43|1@0+ (1,0) [0|1] ""  GW
 SG_ MP5_IHCMenuReq : 53|1@0+ (1,0) [0|1] ""  GW
 SG_ MP5_LDWWarning : 45|2@0+ (1,0) [0|3] ""  GW
 SG_ MP5_LDWSensitvity : 47|2@0+ (1,0) [0|3] ""  GW
 SG_ MP5_LaneAssitTypeReq : 18|2@0+ (1,0) [0|7] ""  GW
 SG_ MP5_LDWLKASwitchSts : 8|1@0+ (1,0) [0|1] ""  GW
 SG_ MP5_AlarmStatus : 22|2@0+ (1,0) [0|3] ""  IC,GW
 SG_ MP5_AlarmOrNot : 23|1@0+ (1,0) [0|1] ""  IC,GW
 SG_ MP5_AEB_ON_OFF : 12|1@0+ (1,0) [0|1] ""  GW
 SG_ MP5_FCW_ON_OFF : 13|1@0+ (1,0) [0|1] ""  GW
 SG_ MP5_BSDSwitchSts : 15|1@0+ (1,0) [0|1] ""  GW
 SG_ MP5_FCW_Sensitive : 1|2@0+ (1,0) [0|3] ""  GW

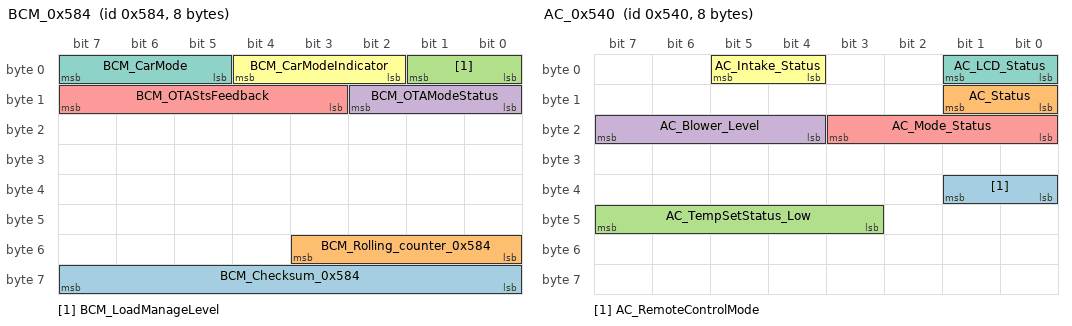
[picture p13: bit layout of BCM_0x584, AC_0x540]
BO_ 1412 BCM_0x584: 8 BCM
 SG_ BCM_Checksum_0x584 : 63|8@0+ (1,0) [0|255] ""  Tester,RTM,MP5,PEPS,IC,ACM1,GW
 SG_ BCM_Rolling_counter_0x584 : 51|4@0+ (1,0) [0|15] ""  Tester,RTM,MP5,PEPS,IC,ACM1,GW
 SG_ BCM_LoadManageLevel : 1|2@0+ (1,0) [0|3] ""  Tester,RTM,MP5,PEPS,IC,GW
 SG_ BCM_OTAModeStatus : 10|3@0+ (1,0) [0|7] ""  GW
 SG_ BCM_OTAStsFeedback : 15|5@0+ (1,0) [0|31] ""  RTM,PEPS,GW
 SG_ BCM_CarModeIndicator : 4|3@0+ (1,0) [0|7] ""  Tester,IC,GW
 SG_ BCM_CarMode : 7|3@0+ (1,0) [0|7] ""  Tester,RTM,MP5,PEPS,IC,ACM1,GW

BO_ 1344 AC_0x540: 8 ACM1
 SG_ AC_RemoteControlMode : 33|2@0+ (1,0) [0|3] ""  GW
 SG_ AC_Status : 9|2@0+ (1,0) [0|3] ""  MP5,GW
 SG_ AC_TempSetStatus_Low : 47|5@0+ (1,0) [0|31] ""  MP5,GW
 SG_ AC_Blower_Level : 23|4@0+ (1,0) [0|15] ""  MP5,GW
 SG_ AC_Mode_Status : 19|4@0+ (1,0) [0|15] ""  MP5,GW
 SG_ AC_Intake_Status : 5|2@0+ (1,0) [0|3] ""  MP5,GW
 SG_ AC_LCD_Status : 1|2@0+ (1,0) [0|3] ""  MP5,GW

BO_ 773 ACM_0x305: 8 ACM1
 SG_ AC_MaxVoltageRq : 4|1@0+ (1,0) [0|1] ""  BCM,GW

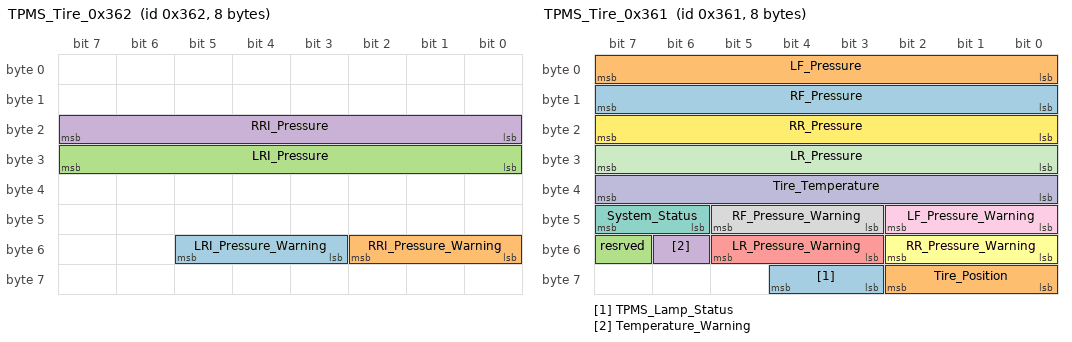
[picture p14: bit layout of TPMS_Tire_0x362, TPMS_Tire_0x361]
BO_ 866 TPMS_Tire_0x362: 8 RTM
 SG_ LRI_Pressure_Warning : 53|3@0+ (1,0) [0|7] ""  IC,GW
 SG_ RRI_Pressure_Warning : 50|3@0+ (1,0) [0|7] ""  IC,GW
 SG_ LRI_Pressure : 31|8@0+ (2.75,0) [0|699] "kPa"  IC,GW
 SG_ RRI_Pressure : 23|8@0+ (2.75,0) [0|699] "kPa"  IC,GW

BO_ 865 TPMS_Tire_0x361: 8 RTM
 SG_ TPMS_Lamp_Status : 60|2@0+ (1,0) [0|3] ""  IC,GW
 SG_ Tire_Position : 58|3@0+ (1,0) [0|7] ""  MP5,IC,GW
 SG_ resrved : 55|1@0+ (1,0) [0|1] ""  IC,GW
 SG_ Temperature_Warning : 54|1@0+ (1,0) [0|1] ""  MP5,IC,GW
 SG_ LR_Pressure_Warning : 53|3@0+ (1,0) [0|7] ""  MP5,IC,GW
 SG_ RR_Pressure_Warning : 50|3@0+ (1,0) [0|7] ""  MP5,IC,GW
 SG_ System_Status : 47|2@0+ (1,0) [0|3] ""  MP5,IC,GW
 SG_ RF_Pressure_Warning : 45|3@0+ (1,0) [0|7] ""  MP5,IC,GW
 SG_ LF_Pressure_Warning : 42|3@0+ (1,0) [0|7] ""  MP5,IC,GW
 SG_ Tire_Temperature : 39|8@0+ (1,-60) [-60|194] "deg.C"  MP5,IC,GW
 SG_ LR_Pressure : 31|8@0+ (2.75,0) [0|698.5] "kPa"  MP5,IC,GW
 SG_ RR_Pressure : 23|8@0+ (2.75,0) [0|698.5] "kPa"  MP5,IC,GW
 SG_ RF_Pressure : 15|8@0+ (2.75,0) [0|698.5] "kPa"  MP5,IC,GW
 SG_ LF_Pressure : 7|8@0+ (2.75,0) [0|698.5] "kPa"  MP5,IC,GW

BO_ 82 PEPS_0x52_valeo: 8 PEPS
 SG_ PEPS_LearningSK64 : 7|64@0+ (1,0) [0|1.844674407371E+019] ""  GW

BO_ 80 PEPS_EmsAuth_0x50: 8 PEPS
 SG_ PEPS_EmsAuth : 7|64@0+ (1,0) [0|1.844674407371E+019] ""  GW

BO_ 420 PEPS_TBOXAuth_0x1A4: 8 PEPS
 SG_ PEPS_TBOXAuth : 7|64@0+ (1,0) [0|1.844674407371E+019] ""  GW

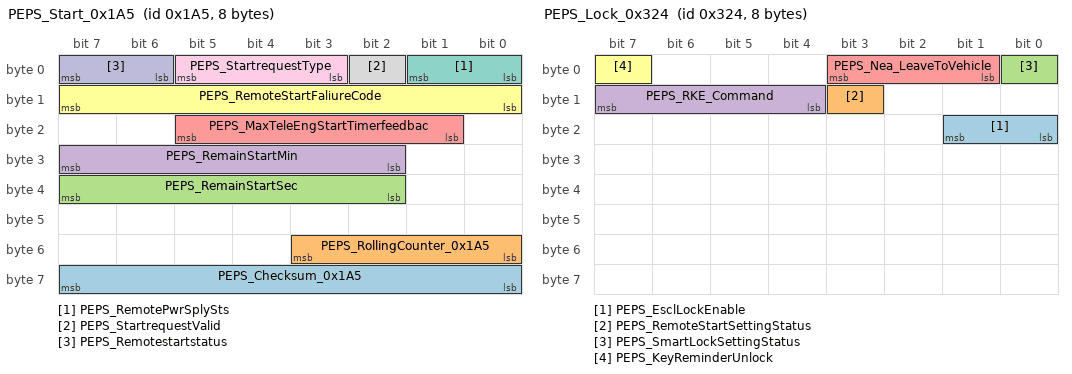
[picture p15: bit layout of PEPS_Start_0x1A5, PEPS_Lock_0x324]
BO_ 421 PEPS_Start_0x1A5: 8 PEPS
 SG_ PEPS_Checksum_0x1A5 : 63|8@0+ (1,0) [0|255] ""  IC,GW
 SG_ PEPS_RollingCounter_0x1A5 : 51|4@0+ (1,0) [0|15] ""  IC,GW
 SG_ PEPS_RemainStartSec : 39|6@0+ (1,0) [0|59] ""  GW
 SG_ PEPS_RemainStartMin : 31|6@0+ (1,0) [0|59] ""  GW
 SG_ PEPS_MaxTeleEngStartTimerfeedbac : 21|5@0+ (1,0) [0|31] ""  GW
 SG_ PEPS_RemoteStartFaliureCode : 15|8@0+ (1,0) [0|255] ""  GW
 SG_ PEPS_RemotePwrSplySts : 1|2@0+ (1,0) [0|3] ""  GW
 SG_ PEPS_StartrequestValid : 2|1@0+ (1,0) [0|1] ""  GW
 SG_ PEPS_StartrequestType : 5|3@0+ (1,0) [0|7] ""  GW
 SG_ PEPS_Remotestartstatus : 7|2@0+ (1,0) [0|3] ""  IC,ACM1,GW

BO_ 805 PEPS_0x325: 8 PEPS
 SG_ PEPS_Checksum_0x325 : 63|8@0+ (1,0) [0|255] ""  BCM,IC,GW
 SG_ PEPS_RollingCounter_0x325 : 51|4@0+ (1,0) [0|15] ""  BCM,IC,GW
 SG_ PEPS_OTAModeStatus : 55|3@0+ (1,0) [0|7] ""  BCM,GW
 SG_ PEPS_OTAStatus : 11|2@0+ (1,0) [0|3] ""  GW
 SG_ PEPS_KeyBatteryWarning : 44|1@0+ (1,0) [0|1] ""  IC,GW
 SG_ PEPS_KeyOutWarning1 : 45|1@0+ (1,0) [0|1] ""  IC,GW
 SG_ PEPS_NoKeyFoundWarning : 46|1@0+ (1,0) [0|1] ""  IC,GW
 SG_ PEPS_KeyReminderWarning : 47|1@0+ (1,0) [0|1] ""  GW
 SG_ PEPS_ClutchIndicationWarning : 32|1@0+ (1,0) [0|1] ""  IC,GW
 SG_ PEPS_BrakeIndicationWarning : 33|1@0+ (1,0) [0|1] ""  IC,GW
 SG_ PEPS_ESCL_NotLockWarn : 24|1@0+ (1,0) [0|1] ""  GW
 SG_ PEPS_ESCL_NotUnlockWarning : 25|1@0+ (1,0) [0|1] ""  GW
 SG_ PEPS_Forbidden_FOB : 39|3@0+ (1,0) [0|4] ""  GW
 SG_ PEPS_CurrentValid_FOB : 28|3@0+ (1,0) [0|4] ""  GW
 SG_ PEPS_SystemFailStatus : 29|1@0+ (1,0) [0|1] ""  MP5,GW
 SG_ PEPS_ESCL_FailStatus : 30|1@0+ (1,0) [0|1] ""  IC,GW
 SG_ PEPS_SSB_FailStatus : 31|1@0+ (1,0) [0|1] ""  IC,GW
 SG_ PEPS_NotNWarning : 35|1@0+ (1,0) [0|1] ""  IC,GW
 SG_ PEPS_StartRequest : 17|2@0+ (1,0) [0|3] ""  GW
 SG_ PEPS_IMMO_MatchStatus : 19|2@0+ (1,0) [0|3] ""  IC,GW
 SG_ PEPS_ClutchPedalStatus_MT : 21|2@0+ (1,0) [0|3] ""  GW
 SG_ PEPS_BrakePedalStatus : 23|2@0+ (1,0) [0|3] ""  GW
 SG_ PEPS_ESCL_LearningStatus : 13|2@0+ (1,0) [0|3] ""  GW
 SG_ PEPS_ESCL_LockStatus : 15|2@0+ (1,0) [0|3] ""  GW
 SG_ PEPS_IGN2RelayStsStatus : 0|1@0+ (1,0) [0|1] ""  GW
 SG_ PEPS_IGN1RelayStsStatus : 1|1@0+ (1,0) [0|1] ""  GW
 SG_ PEPS_PowerModeInvalid : 5|1@0+ (1,0) [0|1] ""  GW
 SG_ PEPS_PowerMode : 7|2@0+ (1,0) [0|3] ""  BCM,GW

BO_ 804 PEPS_Lock_0x324: 8 PEPS
 SG_ PEPS_EsclLockEnable : 17|2@0+ (1,0) [0|3] ""  BCM
 SG_ PEPS_RemoteStartSettingStatus : 11|1@0+ (1,0) [0|1] ""  MP5
 SG_ PEPS_SmartLockSettingStatus : 0|1@0+ (1,0) [0|1] ""  MP5
 SG_ PEPS_RKE_Command : 15|4@0+ (1,0) [0|15] ""  BCM
 SG_ PEPS_Nea_LeaveToVehicle : 3|3@0+ (1,0) [0|7] ""  BCM
 SG_ PEPS_KeyReminderUnlock : 7|1@0+ (1,0) [0|1] ""  BCM

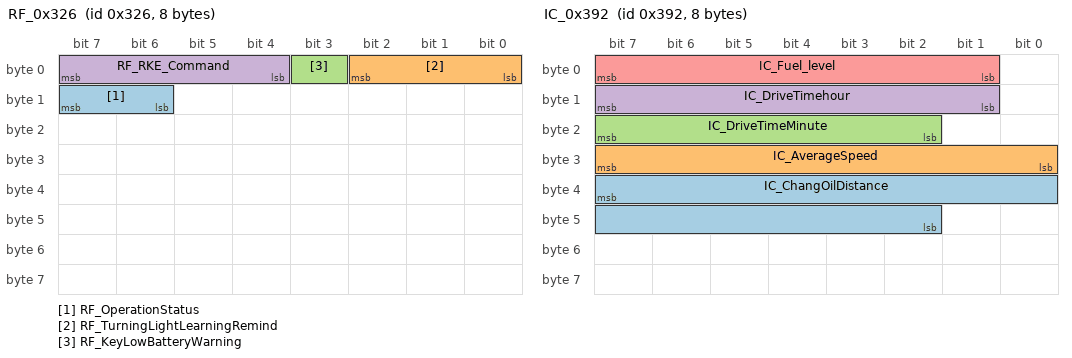
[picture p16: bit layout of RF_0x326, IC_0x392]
BO_ 806 RF_0x326: 8 RTM
 SG_ RF_OperationStatus : 15|2@0+ (1,0) [0|3] ""  BCM
 SG_ RF_TurningLightLearningRemind : 2|3@0+ (1,0) [0|7] ""  BCM
 SG_ RF_KeyLowBatteryWarning : 3|1@0+ (1,0) [0|1] ""  BCM
 SG_ RF_RKE_Command : 7|4@0+ (1,0) [0|15] ""  BCM

BO_ 902 IC_0x386: 8 IC
 SG_ IC_BSDSoundSts : 7|1@0+ (1,0) [0|1] ""  MP5

BO_ 898 MP5_0x382: 8 MP5
 SG_ MP5_BSDSoundSwitchSts : 6|1@0+ (1,0) [0|1] ""  IC

BO_ 914 IC_0x392: 8 IC
 SG_ IC_ChangOilDistance : 39|14@0+ (1,0) [0|9999] "km"  MP5,GW
 SG_ IC_AverageSpeed : 31|8@0+ (1,0) [0|255] "kph"  MP5,GW
 SG_ IC_DriveTimeMinute : 23|6@0+ (1,0) [0|59] "minute"  MP5,GW
 SG_ IC_DriveTimehour : 15|7@0+ (1,0) [0|127] "Hour"  MP5,GW
 SG_ IC_Fuel_level : 7|7@0+ (1,0) [0|100] "%"  MP5,GW

BO_ 1347 BCM_EBS3_0x543: 8 BCM
 SG_ EBS_Q_Discharge : 23|16@0+ (0.125,0) [0|8191.75] "Ah"  GW
 SG_ EBS_Q_Charge : 7|16@0+ (0.125,0) [0|8191.75] "Ah"  GW

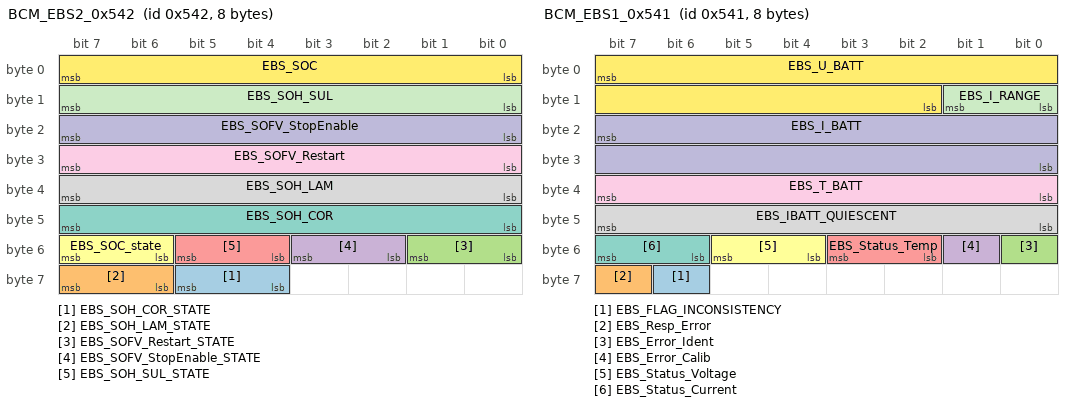
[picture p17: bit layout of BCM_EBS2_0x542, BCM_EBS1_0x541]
BO_ 1346 BCM_EBS2_0x542: 8 BCM
 SG_ EBS_SOH_COR_STATE : 61|2@0+ (1,0) [0|3] ""  GW
 SG_ EBS_SOH_LAM_STATE : 63|2@0+ (1,0) [0|3] ""  GW
 SG_ EBS_SOFV_Restart_STATE : 49|2@0+ (1,0) [0|3] ""  GW
 SG_ EBS_SOFV_StopEnable_STATE : 51|2@0+ (1,0) [0|3] ""  GW
 SG_ EBS_SOH_SUL_STATE : 53|2@0+ (1,0) [0|3] ""  GW
 SG_ EBS_SOC_state : 55|2@0+ (1,0) [0|3] ""  GW
 SG_ EBS_SOH_COR : 47|8@0+ (0.0625,0) [0|15.875] "V"  GW
 SG_ EBS_SOH_LAM : 39|8@0+ (0.5,0) [0|127] "Ah"  GW
 SG_ EBS_SOFV_Restart : 31|8@0+ (0.0625,0) [0|15.875] "V"  GW
 SG_ EBS_SOFV_StopEnable : 23|8@0+ (0.0625,0) [0|15.875] "V"  GW
 SG_ EBS_SOH_SUL : 15|8@0+ (1,0) [0|100] "%"  GW
 SG_ EBS_SOC : 7|8@0+ (1,0) [0|100] "%"  GW

BO_ 1345 BCM_EBS1_0x541: 8 BCM
 SG_ EBS_FLAG_INCONSISTENCY : 62|1@0+ (1,0) [0|1] ""  GW
 SG_ EBS_Resp_Error : 63|1@0+ (1,0) [0|1] ""  GW
 SG_ EBS_Error_Ident : 48|1@0+ (1,0) [0|1] ""  GW
 SG_ EBS_Error_Calib : 49|1@0+ (1,0) [0|1] ""  GW
 SG_ EBS_Status_Temp : 51|2@0+ (1,0) [0|3] ""  GW
 SG_ EBS_Status_Voltage : 53|2@0+ (1,0) [0|3] ""  GW
 SG_ EBS_Status_Current : 55|2@0+ (1,0) [0|3] ""  GW
 SG_ EBS_IBATT_QUIESCENT : 47|8@0+ (0.00390625,0) [0|0.984375] "A"  GW
 SG_ EBS_T_BATT : 39|8@0+ (1,-40) [-40|105] "℃"  GW
 SG_ EBS_I_BATT : 23|16@0+ (0.00097656,-1500) [-1500|1500] "A"  GW
 SG_ EBS_I_RANGE : 9|2@0+ (1,0) [0|3] ""  GW
 SG_ EBS_U_BATT : 7|14@0+ (0.00097656,3) [3|18] "V"  GW

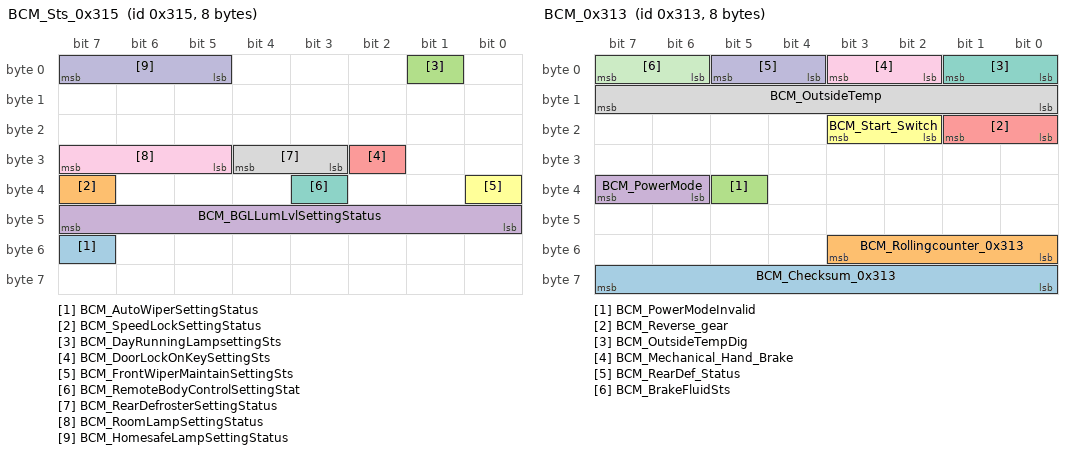
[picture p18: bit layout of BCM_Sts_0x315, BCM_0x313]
BO_ 789 BCM_Sts_0x315: 8 BCM
 SG_ BCM_AutoWiperSettingStatus : 55|1@0+ (1,0) [0|1] ""  MP5,GW
 SG_ BCM_SpeedLockSettingStatus : 39|1@0+ (1,0) [0|1] ""  MP5,GW
 SG_ BCM_DayRunningLampsettingSts : 1|1@0+ (1,0) [0|1] ""  MP5,GW
 SG_ BCM_BGLLumLvlSettingStatus : 47|8@0+ (1,0) [0|255] "%"  MP5,IC,GW
 SG_ BCM_DoorLockOnKeySettingSts : 26|1@0+ (1,0) [0|1] ""  MP5,GW
 SG_ BCM_FrontWiperMaintainSettingSts : 32|1@0+ (1,0) [0|1] ""  MP5,GW
 SG_ BCM_RemoteBodyControlSettingStat : 35|1@0+ (1,0) [0|1] ""  MP5,GW
 SG_ BCM_RearDefrosterSettingStatus : 28|2@0+ (1,0) [0|3] ""  MP5,GW
 SG_ BCM_RoomLampSettingStatus : 31|3@0+ (1,0) [0|7] ""  MP5,GW
 SG_ BCM_HomesafeLampSettingStatus : 7|3@0+ (1,0) [0|7] ""  MP5,GW

BO_ 787 BCM_0x313: 8 BCM
 SG_ BCM_Checksum_0x313 : 63|8@0+ (1,0) [0|255] ""  MP5,IC,ACM1,GW
 SG_ BCM_Rollingcounter_0x313 : 51|4@0+ (1,0) [0|15] ""  MP5,IC,ACM1,GW
 SG_ BCM_PowerModeInvalid : 37|1@0+ (1,0) [0|1] ""  MP5,GW
 SG_ BCM_PowerMode : 39|2@0+ (1,0) [0|3] ""  MP5,IC,GW
 SG_ BCM_Reverse_gear : 17|2@0+ (1,0) [0|3] ""  MP5,GW
 SG_ BCM_Start_Switch : 19|2@0+ (1,0) [0|3] ""  IC,GW
 SG_ BCM_OutsideTempDig : 1|2@0+ (1,0) [0|3] ""  MP5,IC,ACM1,GW
 SG_ BCM_OutsideTemp : 15|8@0+ (0.75,-48) [-48|142.5] "degC"  MP5,IC,ACM1,GW
 SG_ BCM_Mechanical_Hand_Brake : 3|2@0+ (1,0) [0|3] ""  IC,GW
 SG_ BCM_RearDef_Status : 5|2@0+ (1,0) [0|3] ""  GW
 SG_ BCM_BrakeFluidSts : 7|2@0+ (1,0) [0|3] ""  IC,GW

BO_ 792 BCM_Lamp_0x318: 8 BCM
 SG_ BCM_Checksum_0x318 : 63|8@0+ (1,0) [0|255] ""  IC,ACM1,GW
 SG_ BCM_Rollingcounter_0x318 : 51|4@0+ (1,0) [0|15] ""  IC,ACM1,GW
 SG_ BCM_ImmoSts : 55|2@0+ (1,0) [0|3] ""  IC,GW
 SG_ BCM_DayRunningLampDig : 32|1@0+ (1,0) [0|1] ""  IC,GW
 SG_ BCM_BrakelightDig : 33|1@0+ (1,0) [0|1] ""  IC,GW
 SG_ BCM_reversinglightDig : 34|1@0+ (1,0) [0|1] ""  IC,GW
 SG_ BCM_TurnIndicatorDig : 35|1@0+ (1,0) [0|1] ""  IC,GW
 SG_ BCM_RearFogLmpDig : 36|1@0+ (1,0) [0|1] ""  IC,GW
 SG_ BCM_PosLmpDig : 38|1@0+ (1,0) [0|1] ""  IC,GW
 SG_ BCM_BackHomeSts : 27|2@0+ (1,0) [0|3] ""  IC,GW
 SG_ BCM_AutolampSts : 29|2@0+ (1,0) [0|3] ""  GW
 SG_ BCM_readinglampSts : 31|2@0+ (1,0) [0|3] ""  GW
 SG_ BCM_Highmountedstoplamp : 21|2@0+ (1,0) [0|3] ""  GW
 SG_ BCM_BrakelightSts : 23|2@0+ (1,0) [0|3] ""  GW
 SG_ BCM_reversinglightSts : 9|2@0+ (1,0) [0|3] ""  GW
 SG_ BCM_DayRunningLampSts : 11|2@0+ (1,0) [0|3] ""  GW
 SG_ BCM_TurnIndicatorSts : 13|2@0+ (1,0) [0|3] ""  IC,GW
 SG_ BCM_RearFogLmpSts : 15|2@0+ (1,0) [0|3] ""  IC,GW
 SG_ BCM_FrntFogLmpSts : 1|2@0+ (1,0) [0|3] ""  IC,GW
 SG_ BCM_PosLmpSts : 3|2@0+ (1,0) [0|3] ""  IC,ACM1,GW
 SG_ BCM_LowBeamSts : 5|2@0+ (1,0) [0|3] ""  IC,GW
 SG_ BCM_HighBeamSts : 7|2@0+ (1,0) [0|3] ""  IC,GW

BO_ 784 BCM_Door_0x310: 8 BCM
 SG_ BCM_Checksum_0x310 : 63|8@0+ (1,0) [0|255] ""  MP5,PEPS,IC,GW
 SG_ BCM_Rolling_counter_0x310 : 51|4@0+ (1,0) [0|15] ""  MP5,PEPS,IC,GW
 SG_ BCM_EsclLockGndSts : 41|2@0+ (1,0) [0|3] ""  PEPS,GW
 SG_ BCM_FrontWiperSts : 33|2@0+ (1,0) [0|3] ""  MP5,GW
 SG_ BCM_EnginehoodSts : 39|2@0+ (1,0) [0|3] ""  GW
 SG_ BCM_AntiTheftSts : 17|2@0+ (1,0) [0|3] ""  MP5,GW
 SG_ BCM_LoadSensitivity : 18|1@0+ (1,0) [0|1] ""  GW
 SG_ BCM_LockUnlockFeedback : 23|5@0+ (1,0) [0|31] ""  MP5,PEPS,GW
 SG_ BCM_DoorLockStsTrunk : 26|2@0+ (1,0) [0|3] ""  MP5,PEPS,GW
 SG_ BCM_DoorStsTrunk : 28|2@0+ (1,0) [0|3] ""  MP5,PEPS,IC,GW
 SG_ BCM_DoorLockStsRearRi : 9|2@0+ (1,0) [0|3] ""  MP5,PEPS,GW
 SG_ BCM_DoorLockStsRearLe : 11|2@0+ (1,0) [0|3] ""  MP5,PEPS,GW
 SG_ BCM_DoorLockStsFrntRi : 13|2@0+ (1,0) [0|3] ""  MP5,PEPS,GW
 SG_ BCM_DoorLockStsFrntLe : 15|2@0+ (1,0) [0|3] ""  MP5,PEPS,GW
 SG_ BCM_DoorStsRearRi : 1|2@0+ (1,0) [0|3] ""  MP5,PEPS,IC,GW
 SG_ BCM_DoorStsRearLe : 3|2@0+ (1,0) [0|3] ""  MP5,PEPS,IC,GW
 SG_ BCM_DoorStsFrntRi : 5|2@0+ (1,0) [0|3] ""  MP5,PEPS,IC,GW
 SG_ BCM_DoorStsFrntLe : 7|2@0+ (1,0) [0|3] ""  MP5,PEPS,IC,GW

CM_ SG_ 423 TBOX_HornCmd "远程鸣笛指令";
CM_ SG_ 423 TBOX_TurnIndcrCtrlCmd "远程闪灯指令";
CM_ SG_ 423 TBOX_DoorLockCmd "远程车门解闭锁指令";
CM_ SG_ 1899 DiagRespFromTBOX "Diagnostic Response from ECU";
CM_ SG_ 1891 DiagPhysReqToTBOX "Diagnostic Physical Request to ECU";
CM_ SG_ 1851 DiagRespFromRTM "Diagnostic Response from ECU";
CM_ SG_ 1843 DiagPhysReqToRTM "Diagnostic Physical Request to ECU";
CM_ SG_ 1839 DiagRespFromMP5 "Diagnostic Response from ECU";
CM_ SG_ 1831 DiagPhysReqToMP5 "Diagnostic Physical Request to ECU";
CM_ SG_ 1850 DiagRespFromPEPS "Diagnostic Response from ECU";
CM_ SG_ 1842 DiagPhysReqToPEPS "Diagnostic Physical Request to ECU";
CM_ SG_ 1848 DiagRespFromIC "Diagnostic Response from ECU";
CM_ SG_ 1840 DiagPhysReqToIC "Diagnostic Physical Request to ECU";
CM_ SG_ 1865 DiagRespFromAC "Diagnostic Response from ECU";
CM_ SG_ 1857 DiagPhysReqToAC "Diagnostic Physical Request to ECU";
CM_ SG_ 1849 DiagRespFromBCM "Diagnostic Response from ECU";
CM_ SG_ 1841 DiagPhysReqToBCM "Diagnostic Physical Request to ECU";
CM_ SG_ 2015 DiagFuncReq "Diagnostic Functional Request from Tester";
CM_ SG_ 1079 RTMNMUserData "OSEK NM user data";
CM_ SG_ 1079 RTMNMAlive "OSEK NM Alive";
CM_ SG_ 1079 RTMNMRing "OSEK NM Ring";
CM_ SG_ 1079 RTMNMLimphome "OSEK NM Limphome";
CM_ SG_ 1079 RTMNMSleepInd "OSEK NM Sleep Indication";
CM_ SG_ 1079 RTMNMSleepAck "OSEK NM Sleep Acknowledge";
CM_ SG_ 1079 RTMNMDestAddr "OSEK NM destination address";
CM_ SG_ 1075 MP5NMUserData "OSEK NM user data";
CM_ SG_ 1075 MP5NMAlive "OSEK NM Alive";
CM_ SG_ 1075 MP5NMRing "OSEK NM Ring";
CM_ SG_ 1075 MP5NMLimphome "OSEK NM Limphome";
CM_ SG_ 1075 MP5NMSleepInd "OSEK NM Sleep Indication";
CM_ SG_ 1075 MP5NMSleepAck "OSEK NM Sleep Acknowledge";
CM_ SG_ 1075 MP5NMDestAddr "OSEK NM destination address";
CM_ SG_ 1074 PEPSNMUserData "OSEK NM user data";
CM_ SG_ 1074 PEPSNMAlive "OSEK NM Alive";
CM_ SG_ 1074 PEPSNMRing "OSEK NM Ring";
CM_ SG_ 1074 PEPSNMLimphome "OSEK NM Limphome";
CM_ SG_ 1074 PEPSNMSleepInd "OSEK NM Sleep Indication";
CM_ SG_ 1074 PEPSNMSleepAck "OSEK NM Sleep Acknowledge";
CM_ SG_ 1074 PEPSNMDestAddr "OSEK NM destination address";
CM_ SG_ 1072 ICNMUserData "OSEK NM user data";
CM_ SG_ 1072 ICNMAlive "OSEK NM Alive";
CM_ SG_ 1072 ICNMRing "OSEK NM Ring";
CM_ SG_ 1072 ICNMLimphome "OSEK NM Limphome";
CM_ SG_ 1072 ICNMSleepInd "OSEK NM Sleep Indication";
CM_ SG_ 1072 ICNMSleepAck "OSEK NM Sleep Acknowledge";
CM_ SG_ 1072 ICNMDestAddr "OSEK NM destination address";
CM_ SG_ 1120 GWNMUserData "OSEK NM user data";
CM_ SG_ 1120 GWNMAlive "OSEK NM Alive";
CM_ SG_ 1120 GWNMRing "OSEK NM Ring";
CM_ SG_ 1120 GWNMLimphome "OSEK NM Limphome";
CM_ SG_ 1120 GWNMSleepInd "OSEK NM Sleep Indication";
CM_ SG_ 1120 GWNMSleepAck "OSEK NM Sleep Acknowledge";
CM_ SG_ 1120 GWNMDestAddr "OSEK NM destination address";
CM_ SG_ 1073 BCMNMUserData "OSEK NM user data";
CM_ SG_ 1073 BCMNMAlive "OSEK NM Alive";
CM_ SG_ 1073 BCMNMRing "OSEK NM Ring";
CM_ SG_ 1073 BCMNMLimphome "OSEK NM Limphome";
CM_ SG_ 1073 BCMNMSleepInd "OSEK NM Sleep Indication";
CM_ SG_ 1073 BCMNMSleepAck "OSEK NM Sleep Acknowledge";
CM_ SG_ 1073 BCMNMDestAddr "OSEK NM destination address";
CM_ SG_ 96 EMS_EngAuthentResult "The signal is sent to PEPS to  indicate the authentification result.
Please refer to function specification to find the timing performance requirement of sending this signal.
";
CM_ SG_ 581 Checksum_0x245 "checksum  is Byte XOR except checksum byte. 

Checksum: Byte0 XOR Byte1 XOR Byte2 XOR Byte3 XOR Byte4 XOR Byte5 XOR Byte6";
CM_ SG_ 581 Rolling_counter_0x245 "we used 4bit length signal and the arithmetic is increased from 0 to 15 by every message.";
CM_ SG_ 581 IPM_LDWWarningType "LDWWarningType Status";
CM_ SG_ 581 IPM_HMA_HighbeamReq "HMA high beam request";
CM_ SG_ 581 IPM_HMA_Status "HMA status";
CM_ SG_ 581 IPM_LaneAssit_TorqueReqStatus "LKS torque request staus";
CM_ SG_ 581 IPM_LaneAssit_TorqueReq "Output LKS torque request";
CM_ SG_ 581 IPM_SLASpdlimitUnits "RSF output speed limit unit";
CM_ SG_ 581 IPM_SLASpdlimit "RSF output speed limit";
CM_ SG_ 581 IPM_SLAState "RSF function status";
CM_ SG_ 581 IPM_LaneAssit_WarningVibration "Vibration warning request";
CM_ SG_ 581 IPM_LaneAssit_WarningAudio "Audio warning request";
CM_ SG_ 581 IPM_LaneAssit_Status "LDW/LKA status";
CM_ SG_ 581 IPM_LaneAssit_HandsonReq "Hands on request to driver";
CM_ SG_ 581 IPM_LaneAssit_Sensitivity "LKS sensitivity";
CM_ SG_ 581 IPM_LaneAssitType "Operation mode of LKS";
CM_ SG_ 581 IPM_LaneAssit_RightVisualization "Right line tracking status";
CM_ SG_ 581 IPM_LaneAssit_LeftVisualization "Left line tracking status";
CM_ SG_ 629 Checksum_0x275 "checksum  is Byte XOR except checksum byte. 

Checksum: Byte0 XOR Byte1 XOR Byte2 XOR Byte3 XOR Byte4 XOR Byte5 XOR Byte6";
CM_ SG_ 629 Rolling_counter_0x275 "we used 4bit length signal and the arithmetic is increased from 0 to 15 by every message.";
CM_ SG_ 629 DOA_OFFTelltale "DOA_OFFTelltale Request";
CM_ SG_ 629 CTA_OFFTelltale "CTA_OFFTelltale Request";
CM_ SG_ 629 SODLCA_OFFTelltale "SODLCA_OFFTelltale Request";
CM_ SG_ 629 SOD_LCA_warningReqLeft "request SOD/LCA Left side warning element";
CM_ SG_ 629 SOD_DOA_warningReqLeftRear "request DOA left rear side warning element左后门开门预警";
CM_ SG_ 629 SOD_DOA_warningReqLeftFront "request DOA Left front side warning element左前门开门预警";
CM_ SG_ 629 SOD_CTA_warningReqLeft "request CTA Left side warning element";
CM_ SG_ 629 SOD_AutoAlignmentFlag "Indicate if the Radar alignment succeful ";
CM_ SG_ 629 SOD_BLIS_Active "Indicate the status of SOD";
CM_ SG_ 629 SOD_BLIS_display "盲区探测显示";
CM_ SG_ 629 SOD_LCA_warningReqRight "并线辅助";
CM_ SG_ 629 SOD_DOA_State "To show function are forbidden or not";
CM_ SG_ 629 SOD_CTA_State "To show function are forbidden or not";
CM_ SG_ 629 SOD_SODLCA_State "To show function are forbidden or not";
CM_ SG_ 629 SOD_DOA_warningReqRightRear "request DOA right rear side warning element右后门开门预警";
CM_ SG_ 629 SOD_DOA_warningReqRightFront "request DOA right front side warning element右前门开门预警";
CM_ SG_ 629 SOD_CTA_warningReqRight "request CTA right side warning element倒车侧方来车预警";
CM_ SG_ 625 PAM_ChimeCmdSoundCadence "Park Assistant Chime Command:Sound Cadence
报警声音音调";
CM_ SG_ 625 PAM_ChimeCmdSoundStatus "Park Assistant Chime Command:Sound Frequence
报警声音频率";
CM_ SG_ 625 PAM_Sts "Advanced Parking Assist Status";
CM_ SG_ 625 PAM_RearSysTemWorkSts "Park Assistant Rear Status:Parking Assistance Front system status";
CM_ SG_ 625 PAM_FrontSysTemWorkSts "Park Assistant Front Status:Parking Assistance Front system status";
CM_ SG_ 625 PAM_objectStsRRC "Park Assistant Rear Status:Parking Assistance Rear Region 4 Object Status
倒车雷达区域4障碍物状态（障碍物在哪个Zone）";
CM_ SG_ 625 PAM_objectStsRRM "Park Assistant Rear Status:Parking Assistance Rear Region 3 Object Status
倒车雷达区域3障碍物状态（障碍物在哪个Zone）（三雷达时，此信号发送0x0）";
CM_ SG_ 625 PAM_objectStsRLM "Park Assistant Rear Status:Parking Assistance Rear Region 2 Object Status
倒车雷达区域2障碍物状态（障碍物在哪个Zone）";
CM_ SG_ 625 PAM_objectStsRLC "Park Assistant Rear Status:Parking Assistance Rear Region 1 ObjectStatus
倒车雷达区域1障碍物状态（障碍物在哪个Zone）";
CM_ SG_ 625 PAM_objectStsFRC "Park Assistant Front Status:Parking Assistace Front Region 4object status前进雷达区域4障碍物状态";
CM_ SG_ 625 PAM_ObjectStsFRM "Park Assistant Front Status:Parking Assistace Front Region 3 object status前进雷达区域3障碍物状态(三雷达时，此信号发送0x0)";
CM_ SG_ 625 PAM_ObjectStsFLM "Park Assistant Front Status:Parking Assistace Front Region 2 object status前进雷达区域2障碍物状态";
CM_ SG_ 625 PAM_ObjectStsFLC "Park Assistant Front Status:Parking Assistace Front Region 1 object status前进雷达区域1障碍物状态";
CM_ SG_ 625 PAM_InfoDisplayReq "PAM Information Display Request";
CM_ SG_ 625 PAM_ParkingBarSts "PAM(Advanced Parking Assist)Parking progress bar status";
CM_ SG_ 625 PAM_ParkingBarpercent "Advanced Parking ASSIST:Parking progress";
CM_ SG_ 1409 IC_Second "Second";
CM_ SG_ 1409 IC_Minute "Minute";
CM_ SG_ 1409 IC_Hour "Hour";
CM_ SG_ 1409 IC_Date "Date";
CM_ SG_ 1409 IC_Month "Month";
CM_ SG_ 1409 IC_Year "Year";
CM_ SG_ 1410 TBOX_RealTime_UB "网络时间更新";
CM_ SG_ 1410 TBOX_Second "Second";
CM_ SG_ 1410 TBOX_Minute "Minute";
CM_ SG_ 1410 TBOX_Hour "Hour";
CM_ SG_ 1410 TBOX_Date "Date";
CM_ SG_ 1410 TBOX_Month "Month";
CM_ SG_ 1410 TBOX_Year "Year";
CM_ SG_ 1413 Checksum_0x585 "Byte XOR except checksum byte. 
For example: Message 0x585 , have 8 byte : byte 1，byte2，byte3，byte4，byte5，byte6，byte7，byte8, We define byte8 to Checksum.
So Checksum arithmetic is  byte8 = byte 1 XOR byte2 XOR byte3 XOR byte4 XOR byte5 XOR byte6 XOR byte7";
CM_ SG_ 1413 RollingCounter_0x585 "we used 4bit length signal and the arithmetic is increased from 0 to 15 by every message.
         For example: Message 0x585,the first message sent RollingCounter signal value:0x0,then second message sent 0x1…";
CM_ SG_ 1413 TBOX_OTATime "Total OTA Time";
CM_ SG_ 1413 TBOX_OTAType "OTAType";
CM_ SG_ 1413 TBOX_OTAStsFeedback "TBOX OTA Status Feedback";
CM_ SG_ 1413 TBOX_OTAPowerModeRequest "TBOX OTA Power Mode Request";
CM_ SG_ 1413 TBOX_OTARequest "TBOX OTA Request";
CM_ SG_ 419 TBOX_PEPSAuth "T-BOX和PEPS认证信号";
CM_ SG_ 418 TBOX_AcWorkCmd "空调工作指令";
CM_ SG_ 417 Checksum_0x1A1 "Byte XOR except checksum byte. 
For example: Message 0x1A1 , have 8 byte : byte 1，byte2，byte3，byte4，byte5，byte6，byte7，byte8, We define byte8 to Checksum.
So Checksum arithmetic is  byte8 = byte 1 XOR byte2 XOR byte3 XOR byte4 XOR byte5 XOR byte6 XOR byte7";
CM_ SG_ 417 RollingCounter_0x1A1 "we used 4bit length signal and the arithmetic is increased from 0 to 15 by every message.
         For example: Message 0x1A1,the first message sent RollingCounter signal value:0x0,then second message sent 0x1…";
CM_ SG_ 417 TBOX_MaxTeleEngStartTimer "PEPS的最大启动时间feedback,4-30分钟有效";
CM_ SG_ 417 TBOX_EngCtrlCmd "远程启动熄火指令";
CM_ SG_ 291 TCU_Status_Checksum "checksum  is Byte XOR except checksum byte. 

Checksum: Byte0 XOR Byte1 XOR Byte2 XOR Byte3 XOR Byte4 XOR Byte5 XOR Byte6";
CM_ SG_ 291 TCU_Status_AliveCounter "we used 4bit length signal and the arithmetic is increased from 0 to 15 by every message.";
CM_ SG_ 291 TCU_StGearMode "indicates selected modes";
CM_ SG_ 291 TCU_available "Whether TCU is available for PAM function. (PAM function will be abort when TCU is not available)";
CM_ SG_ 291 TCU_DriverIntervention "Driver manual manipulate gear shift during PAM active.";
CM_ SG_ 291 TCU_OverallRatio "Overall ratio from engine to wheels(Only For CVT&AT)";
CM_ SG_ 291 TCU_GearShiftInProgress "Indicates that a gear shift is in progress, i.e. transient torque transfer
指示是否在换挡过程中";
CM_ SG_ 291 TCU_ShiftLeverPos_SBWM "Actuation of display: Transmission position, Driver information, Transmission data, etc.
发给换挡杆SBWM以供显示用";
CM_ SG_ 291 TCU_DisplayGear "Actuation of display: Transmission position, Driver information, Transmission data, etc.";
CM_ SG_ 291 TCU_GearSelectorReq "Actual transmission Gear lever position based on the Transmission range selected by driver.
换挡杆的输入";
CM_ SG_ 291 TCU_TargetGearReq "During the shifting process this value informs about the gear which is expected to be engaged in the gear box after the shifting process. Therefore it switches to the expected gear state with the beginning of the shifting process(Applied For AT&DCT)
换挡过程中的目标档位（适用于AT&DCT)";
CM_ SG_ 291 TCU_CurrentGearPosition "Shows the transmission gear being currently engaged in the gear box.(Applied For AT&DCT)
当前实际档位（适用于AT&DCT)";
CM_ SG_ 917 TCU_DrvShiftAllwCondRmd "Driver Shift Allow Condition Reminder from TCU
TCU发送的换档允许条件提醒";
CM_ SG_ 917 TCU_Driverwarning "Bit15：Driver warning signal invalid";
CM_ SG_ 917 TCU_Gearbox_Gonglimp "Bit7: (Gong in mechanical limphome )(Acoustic warning Shifting in mechanical limphome) - optional
跛行模式下，发出声音警示
0x0：no active
0x1：active";
CM_ SG_ 917 Trans_Limphome "Limp Status：提示limp，取消定速巡航。";
CM_ SG_ 917 TrnSrvcRqd_B_Rq "Request to indicate Transmission Service Required to driver (wrench light for US, text message for VCC).
Transmission warning light";
CM_ SG_ 917 TCU_MILReq "MIL lamp request from TCU
TCU发送的点亮MIL灯的请求";
CM_ SG_ 1590 EMS_BackupOdometer "Totalo dometerBackUp总里程备份信号";
CM_ SG_ 872 EMS_TroqLimtMin "尿素续航分钟（重型）";
CM_ SG_ 872 EMS_TroqLimtHour "尿素续航小时（重型）";
CM_ SG_ 872 EMS_SpeedLimtMin "尿素续航分钟（重型）";
CM_ SG_ 872 EMS_SpeedLimtHour "尿素续航小时（重型）";
CM_ SG_ 872 EMS_Soot_Pc_Dsply "DPF堵塞%";
CM_ SG_ 872 EMS_DieslPrtcWarn_D_Rq "DPF报警状态";
CM_ SG_ 872 EMS_ManRgenTxt_D_RqDsply "手动再生状态";
CM_ SG_ 872 DCM_GlowPlugLmpReq "Working status of the glow plug. Request to turn on/off the lamp.

This signal only exist when the ECU is DCM";
CM_ SG_ 872 DCM_WIFFullLmpReq "The present status of the fuel water box, request to turn on/off the lamp.

This signal only exist when the ECU is DCM
指示油水分离显示";
CM_ SG_ 872 EMS_UreaLvl "尿素量";
CM_ SG_ 872 EMS_UreaWarn "尿素灯和蜂鸣器";
CM_ SG_ 872 EMS_NoxWarning "排放系统故障（含反应剂消耗检测和NOx排放量检测）文字提醒";
CM_ SG_ 872 EMS_UreaSysWarning "尿素系统故障文字提醒";
CM_ SG_ 872 EMS_AddUreaWarning "尿素添加故障文字提醒";
CM_ SG_ 872 EMS_UreaQty "加注尿素不合格文字提醒";
CM_ SG_ 872 EMS_UreaTxt "尿素少仪表文字提示";
CM_ SG_ 870 EMS_OBDTxt "尿素不合格文字提醒";
CM_ SG_ 870 EMS_OBDWarn "排放可视报警";
CM_ SG_ 870 AT_EngExaustStatus "Exaust system mode status

When this signal is active,TCU will stop self-learning and apply a specific shift-map for higher engine speed
当发动机处于后处理，特殊功能时，TCU不能激活自学习
此信号ZF使用";
CM_ SG_ 870 EMS_EnergyFlow "EnergyFlow
指示当前处于发电、充电、助力、刹车能量回收等";
CM_ SG_ 870 EMS_TargetGearPostion_MT "Target Gear Postion for MT vehicle
MT车型使用此信号";
CM_ SG_ 870 EMS_RemindShiftGear_MT "换挡提醒
MT车型使用此信号";
CM_ SG_ 870 EMS_EngType "发动机类型（预留）";
CM_ SG_ 870 EMS_MIL "IndicateMILwarning
MIL指示灯";
CM_ SG_ 870 EMS_SVS "IndicateSVSwarning
指示灯";
CM_ SG_ 870 EMS_Fuelcounter "Accumulated Fuel quantity injected since IGN ON ( update period: 20ms).  Fuel quantity counter overflow is allowed.
油耗计算使用";
CM_ SG_ 870 EMS_StartStopStatus "It is for the Start&Stop management status display
用于仪表显示启停状态

";
CM_ SG_ 99 EMS_SentSK64 "sent SK to PEPS when PEPS relearning";
CM_ SG_ 98 EMS_Eng_PEPSAuth "Authentication between EMS and PEPS、ESM send to PEPS";
CM_ SG_ 267 EMS_EngSpeedError "EngSpeedError
发动机转速故障";
CM_ SG_ 267 EMS_CluthPedalStatus "CluthPedalStatus
离合器踏板状态
MT车型发送此信号";
CM_ SG_ 267 EMS_EngSpeed "发动机转速";
CM_ SG_ 267 EMS_EngOperationStatus "Actual engine state
Caution:If the ECU is EMS , this signal only contain the states : stopped、running、cranking
发动机运行状态";
CM_ SG_ 267 EMS_AirCompressorStatus "AirCompressorStatus 
压缩机ON状态";
CM_ SG_ 267 EMS_BatteryVoltageError "Indicate the generator is warning when Mechanical flag or Electrical flag is active
蓄电池故障检测";
CM_ SG_ 267 EMS_BatterVoltage "BetteryVoltage(12v电池电压)";
CM_ SG_ 267 EMS_EngCoolanTemp "Engine coolant temperature (sometimes estimated from cylinder head temperature).
发动机冷却温度/发动机水温";
CM_ SG_ 267 EMS_BrkPedalStasus "Information that driver presses the brake pedal. 
Brake main sw hardwired to DCM/EMS and ABS (ABS call this signal as brake lamp switch). Brake redundant Switch only connected to ECU.     
制动踏板状态：表示驾驶员踩下制动踏板的真实状态";
CM_ SG_ 337 EMS_Checksum_0x151 "checksum  is Byte XOR except checksum byte. 

Checksum: Byte0 XOR Byte1 XOR Byte2 XOR Byte3 XOR Byte4 XOR Byte5 XOR Byte6";
CM_ SG_ 337 EMS_Rolling_counter_0x151 "we used 4bit length signal and the arithmetic is increased from 0 to 15 by every message.";
CM_ SG_ 337 EMS_ATSDrivingModeStatus "ATS_Driving_mode_status_EMS
ATS：全地形模式";
CM_ SG_ 337 EMS_EngineStopStartStatus "Indicate the engine S/S status.
指示发动机启停工作状态";
CM_ SG_ 337 EMS_EngBarometricPressure "Engine Ambient Air Pressure,can be use for Altitude compensation
大气压力（环境压力）";
CM_ SG_ 337 EMS_VacuumPressure "This signal indicates the relative pressure of the brake booster vacuum referenced to ambient pressure.
真空度压力
";
CM_ SG_ 337 EMS_EngOffTime "this signal identifies the amount of time from Engine Off to the next ignitin cycle 
发动机停机时间（ESP使用此信号判断制动盘温度/TCU使用此信号判断冷却油温）";
CM_ SG_ 337 EMS_TargCruiseSpeed "巡航目标车速";
CM_ SG_ 337 EMS_CruiseControlStatus "CruiseControlStatus
巡航控制状态";
CM_ SG_ 582 MRR_Checksum_0x246 "checksum  is Byte XOR except checksum byte. 

Checksum: Byte0 XOR Byte1 XOR Byte2 XOR Byte3 XOR Byte4 XOR Byte5 XOR Byte6";
CM_ SG_ 582 MRR_Rolling_counter_0x246 "we used 4bit length signal and the arithmetic is increased from 0 to 15 by every message.";
CM_ SG_ 582 FCW_preWarning "acoustic听觉 pre warning.Used with FCW_Enable signal.";
CM_ SG_ 582 FCW_latentWarning "visual视觉 warning. Used with FCW_Enable signal.";
CM_ SG_ 582 MRR_Obj_Speed "Object speed";
CM_ SG_ 582 MRR_PCW_STATE "PCW（pedestrian collision warning） Status";
CM_ SG_ 582 MRR_AEB_STATE "AEB/AEB-VRU status";
CM_ SG_ 582 MRR_ACC_Startstop_infor "the status of the ACC_startstop";
CM_ SG_ 582 MRR_PCW_preWarning "acoustic听觉 pre warning.Used with PCW_Enable signal.";
CM_ SG_ 582 MRR_PCW_latentWarning "visual视觉 warning. Used with PCW_Enable signal.";
CM_ SG_ 582 ACCHMI_Mode "The status of the ACC control unit.
The ACC mode should be contained in every message sent by ACC.";
CM_ SG_ 582 MRR_FCW_Sensitive "FCW Sensitive Status ";
CM_ SG_ 582 MRR_ACCFailInfo "ACC error in internal system.";
CM_ SG_ 582 MRR_TakeOverReq "the limits of the ACC control reaches, driver should take over.";
CM_ SG_ 582 Textinfo "Textinfo for Driver which is displayed in Dashboard";
CM_ SG_ 582 MRR_ObjValid "an ahead target object detected by ACC, to inform the driver.";
CM_ SG_ 582 MRR_TauGapSet "the set timeGap from driver, should be displayed to driver and if the set value changes.";
CM_ SG_ 582 MRR_dxTarObj "distance to the ahead target object in case of \"mid-end\" HMI.";
CM_ SG_ 582 MRR_vSetDis "the set speed from driver, should be available as long as ACC is active.";
CM_ SG_ 579 ESP_Checksum_0x243 "checksum  is Byte XOR except checksum byte. 

Checksum: Byte0 XOR Byte1 XOR Byte2 XOR Byte3 XOR Byte4 XOR Byte5 XOR Byte6";
CM_ SG_ 579 ESP_RollingCounter_0x243 "we used 4bit length signal and the arithmetic is increased from 0 to 15 by every message.";
CM_ SG_ 579 ESP_GearShiftPrevn "Gear shift prevention

(Inhibit Auto transmission system from gear shifting)";
CM_ SG_ 579 ESP_EspEnableSts "ESP function enabled/disabled status";
CM_ SG_ 579 ESP_ESPInfoLamp "Indication cluster that ESP system currently performs a intervention. ";
CM_ SG_ 579 ESP_EspCtrlActv "Indication that ESP system currently performs a intervention. Set also when TCS active.";
CM_ SG_ 579 ESP_TcsCtrlActv "TCS/ASR (Anti-slip) status flag";
CM_ SG_ 579 ESP_TcsFlgFlt "ESP system has detected a failure which does no allow a reliable ESP regulation and is therefore switched off. Set when TCS switched off due to detected failure.";
CM_ SG_ 579 ESP_VdcFlgFlt "VDC is swithed off due to detected failure";
CM_ SG_ 579 ESP_Driving_mode_req "Vehicle driving mode，";
CM_ SG_ 579 ESP_LdmBLC_BLRequestController "Indicate the request to light up brake light during emergent brake via EPB.
The request to illuminater brake light is needed by HHC,AVH,HDC,VLC,CDD also. This signal will be used not only for EPB emergency braking but also for all the above mentioned functions.";
CM_ SG_ 579 ESP_CdpAvailable "sTatus of CDP system
";
CM_ SG_ 579 ESP_CdpActive "indicates CDP control active
";
CM_ SG_ 579 ESP_HHCAvailable "HMI Responsible,CAN get degrate HHC statement from DSW and send out";
CM_ SG_ 579 ESP_HHCActive "indicate HHC active signal";
CM_ SG_ 579 ABS_HAZActive "Hazard Warning active information to flash brake light.";
CM_ SG_ 795 Checksum_0x31B "checksum  is Byte XOR except checksum byte. 

Checksum: Byte0 XOR Byte1 XOR Byte2 XOR Byte3 XOR Byte4 XOR Byte5 XOR Byte6";
CM_ SG_ 795 Rolling_counter_0x31B "we used 4bit length signal and the arithmetic is increased from 0 to 15 by every message.";
CM_ SG_ 795 SWM_ACCLimpHomeSts "ACC&CCLimpHome标志位";
CM_ SG_ 795 SWM_LaneAssistSwitch "Signal from SWM to Indicate LDW switch  status (Tip SW)SWM";
CM_ SG_ 795 SWM_ACCtauGapSetMinus "to decrease the timeGapSet.";
CM_ SG_ 795 SWM_ACCtauGapSetPlus "to increase the timeGapSet.";
CM_ SG_ 795 SWM_ACCvSetMinus "to decrease the vSet.
Used by CC set- & set。";
CM_ SG_ 795 SWM_ACCvSetPlus "to increase the vSet.
Used by CC set+ & resume。";
CM_ SG_ 795 SWM_ACCSet "activate the ACC control, take the current vehiche speed as vSet.
if constraints exist, no activation.";
CM_ SG_ 795 SWM_ACCCancelResume "to resume or deactive  the ACC control";
CM_ SG_ 795 SWM_ACCEnableSwitch "enables or prevents the ACC control.
Used by CC enable。";
CM_ SG_ 794 SWM_Checksum_0x31A "checksum  is Byte XOR except checksum byte. 

Checksum: Byte0 XOR Byte1 XOR Byte2 XOR Byte3 XOR Byte4 XOR Byte5 XOR Byte6";
CM_ SG_ 794 SWM_Rolling_counter_0x31A "we used 4bit length signal and the arithmetic is increased from 0 to 15 by every message.";
CM_ SG_ 794 SWM_Menu_Confirm "Signal from SWM to Indicate  Meter Menu Confirm   switch  status (Tip SW)提示仪表确认按钮的状态(点触开关) ";
CM_ SG_ 794 SWM_Menu_Right "Signal from SWM to Indicate  Meter Menu toward right turn a page  switch  status (Tip SW)提示仪表向右翻一页按钮的状态(点触开关) ";
CM_ SG_ 794 SWM_Menu_Left "Signal from SWM to Indicate  Meter Menu toward Left turn a page  switch status (Tip SW)提示仪表向左翻一页按钮的状态(点触开关) ";
CM_ SG_ 794 SWM_Menu_Down "Signal from SWM to Indicate Meter Menu toward Down turn a page  switch  status (Tip SW)提示仪表向下翻一页按钮的状态(点触开关) ";
CM_ SG_ 794 SWM_Menu_Up "Signal from SWM to Indicate Meter Menu toward Up turn a page  switch  status (Tip SW)提示仪表向上翻一页按钮的状态(点触开关) ";
CM_ SG_ 794 SWM_VOICE "Signal from SWM to Indicate VOICE switch? status (Tip SW)语音识别按钮的状态(点触开关) ";
CM_ SG_ 794 SWM_MODE "Signal from SWM to Indicate MODE switch? status (Tip SW)模式按钮的状态(点触开关) ";
CM_ SG_ 794 SWM_Next_Song "Signal from SWM to Indicate start next a song switch  status (Tip SW)提示开始下一曲歌按钮的状态(点触开关) ";
CM_ SG_ 794 SWM_Previous_Song "Signal from SWM to Indicate start previous a song  switch  status (Tip SW)提示开始前一曲歌按钮的状态(点触开关) ";
CM_ SG_ 794 SWM_VOL_Plus "Signal from SWM to Indicate VOL + switch  status (Tip SW)提示音量增加按钮的状态(点触开关) ";
CM_ SG_ 794 SWM_VOL_Minus "Signal from SWM to Indicate VOL - switch  status (Tip SW)提示音量减小按钮的状态(点触开关) ";
CM_ SG_ 794 SWM_RearFogLight "Signal from SWM to Indicate rear fog light swith status (Tip SW)提示后雾灯开关状态(点触开关)";
CM_ SG_ 794 SWM_FrontFogLight "Signal from SWM to Indicate front fog light swith status (Block SW) 指示前雾灯开关状态(自锁开关)";
CM_ SG_ 794 SWM_HeadLamp "Signal from SWM to requset the HeadLamp
指示大灯开关状态";
CM_ SG_ 794 SWM_FlashLightSts "Signal from SWM to Indicate flash light switch  status (Tip SW)SWM提示超车灯开关状态(点触开关)";
CM_ SG_ 794 SWM_FrontWipingMode "Signal from SWM to request front wiping mode (Block SW)SWM提示前雨刮功能模式（自锁开关）";
CM_ SG_ 794 SWM_TurnIndicationAct "Signal from SWM to request the turn indication active (Block SW)SWM指示转向灯开关状态（自锁开关）";
CM_ SG_ 794 SWM_WipingInterval_Sensitvity "The signal indicates the stage preselection of the wiper interval function (Block SW)该信号提示雨刮间歇灵敏度（自锁开关）";
CM_ SG_ 794 SWM_HighBeam "Signal from SWM to Indicate high beam switch  status (Tip SW)SWM指示远光灯开关状态(点触开关)";
CM_ SG_ 794 SWM_WasherLimpHomeSts "所有雨刮LimpHome标志位";
CM_ SG_ 794 SWM_FWasherSts "Signal from SWM to indicate the front window washer switch status (Tip SW)SWM指示前洗涤器开关状态 (点触开关)";
CM_ SG_ 608 EPS_Checksum_0x260 "checksum  is Byte XOR except checksum byte. 

Checksum: Byte0 XOR Byte1 XOR Byte2 XOR Byte3 XOR Byte4 XOR Byte5 XOR Byte6";
CM_ SG_ 608 EPS_Rolling_counter_0x260 "we used 4bit length signal and the arithmetic is increased from 0 to 15 by every message.";
CM_ SG_ 608 EPS_N_PerformanceRedu "The support service is the percentage of the relationship between the actual power delivered to the nominal power is available";
CM_ SG_ 608 EPS_SASIndexSts "SAS index status(Only for CEPS)";
CM_ SG_ 608 EPS_N_ECUTemp "The ECU temperature";
CM_ SG_ 608 EPS_F_ECUTempValid "The ECU temperature is valid or not ";
CM_ SG_ 608 EPS_St_EmergencyPowerLimit "The EPS in emergency because of power density limit";
CM_ SG_ 608 EPS_St_EmergencyMotor "The EPS in emergency because of servo motor fault";
CM_ SG_ 608 EPS_St_EmergencyECU "The EPS in emergency because of ECU inner fault";
CM_ SG_ 608 EPS_St_EmergencyCANInterface "The EPS in emergency because of CAN interface";
CM_ SG_ 608 EPS_St_EmergencySensor "The EPS in emergency because of sensor";
CM_ SG_ 608 EPS_St_EmergencyOverTemp "The EPS in emergency because of over temperature";
CM_ SG_ 608 EPS_St_EmergencyOverVoltage "The EPS in emergency because of over voltage";
CM_ SG_ 608 EPS_St_EmergencyUnderVoltage "The EPS in emergency because of under voltage";
CM_ SG_ 608 EPS_F_LoadInfo "The fault status of the load information";
CM_ SG_ 608 EPS_N_LoadInfo "Estimated battery current";
CM_ SG_ 608 EPS_SASSoftLimitRightFlg "SAS Soft-Limit Right Flg";
CM_ SG_ 608 EPS_SASSoftLimitLeftFlg "SAS Soft-Limit Left Flg";
CM_ SG_ 608 EPS_St_DTCFlag " DTC Flag";
CM_ SG_ 608 EPS_S_WarningLampYellow "The warning lamp (yellow)";
CM_ SG_ 608 EPS_S_SafeLampRed "The safe lamp (red)";
CM_ SG_ 848 SRS_Checksum_0x350 "checksum  is Byte XOR except checksum byte. 

Checksum: Byte0 XOR Byte1 XOR Byte2 XOR Byte3 XOR Byte4 XOR Byte5 XOR Byte6";
CM_ SG_ 848 SRS_Rolling_counter_0x350 "we used 4bit length signal and the arithmetic is increased from 0 to 15 by every message.";
CM_ SG_ 848 SRS_AirBagFailSts "Indicate airbag ECU failure status";
CM_ SG_ 848 SRS_SBR_Passenger "The signal value shall be updated based on the status of passenegr seat belt switch and PDM(Passenger Detect Mat), which is connected in serier with Passenger Belt.";
CM_ SG_ 848 SRS_SBR_Driver "The signal  Front Driver Seat Belt Status value shall be updated based on the logical status of driver seat belt switch.";
CM_ SG_ 848 SRS_CrashOutputSts "The signal is used to indicate whether deployment crash is detected.
";
CM_ SG_ 530 ESP_Checksum_0x212 "checksum  is Byte XOR except checksum byte. 

Checksum: Byte0 XOR Byte1 XOR Byte2 XOR Byte3 XOR Byte4 XOR Byte5 XOR Byte6";
CM_ SG_ 530 ESP_Rolling_counter_0x212 "we used 4bit length signal and the arithmetic is increased from 0 to 15 by every message.";
CM_ SG_ 530 ESP_vxwWheelRRValid "indicating rear right wheel speed signal valid or not.";
CM_ SG_ 530 ESP_vxwWheelRLValid "indicating rear left wheel speed signal valid or not.";
CM_ SG_ 530 ESP_vxwWheelFRValid "indicating front right wheel speed signal valid or not.";
CM_ SG_ 530 ESP_vxwWheelFLValid "indicating front left wheel speed signal valid or not.";
CM_ SG_ 530 ESP_vxwWheelRawRR "raw single wheel speed - rear right.Rotation direction included.";
CM_ SG_ 530 ESP_vxwWheelRawRL "raw single wheel speed - rear left.Rotation direction included.";
CM_ SG_ 530 ESP_vxwWheelRawFR "raw single wheel speed - front right.Rotation direction included.";
CM_ SG_ 530 ESP_vxwWheelRawFL "raw single wheel speed - front left. Rotation direction included.";
CM_ SG_ 545 ABS_Checksum_0x221 "checksum  is Byte XOR except checksum byte. 

Checksum: Byte0 XOR Byte1 XOR Byte2 XOR Byte3 XOR Byte4 XOR Byte5 XOR Byte6";
CM_ SG_ 545 ABS_RollingCounter_0x221 "we used 4bit length signal and the arithmetic is increased from 0 to 15 by every message.";
CM_ SG_ 545 ABS_WhlMilgFrntLeStatus "Wheel OdoInfo status for FL";
CM_ SG_ 545 ABS_WhlMilgFrntRiStatus "Wheel OdoInfo status for FR";
CM_ SG_ 545 ABS_VehSpdLgtStatus "Vehicle speed value valid";
CM_ SG_ 545 ABS_AbsCtrlActv "Indication that ESP system(especially ABS Module) currently performs a brake intervention. ";
CM_ SG_ 545 ABS_AbsFlgFlt "ABS system has detected a failure which does no allow a reliable ABS regulation and is therefore switched off";
CM_ SG_ 545 ABS_EbdFlgFlt "ABS system has detected a heavy fault, which does not even allow a reliable electronic brake distribution and is therefore completely shut down";
CM_ SG_ 545 ABS_VehSpdDirection "Vehicle speed direction ";
CM_ SG_ 545 ABS_VehSpdLgt "Current Longitudinal Vehicle Speed

 refer to 'Veh speed cal' tab for detail.";
CM_ SG_ 545 ABS_WhlMilgFrntRi "Mileage Information provided by wheel speed sensor.

(This signal provide accumulated sum of rising edges and falling edges of Front Right wheel speed sensor output since IGN ON. eg. the wheel plate have 54 teeth/cycle, then the edges are 108 per cycle, please contact OEM for the wheel speed sensor information.) ";
CM_ SG_ 545 ABS_WhlMilgFrntLe "Mileage Information provided by wheel speed sensor.

(This signal provide accumulated sum of rising edges and falling edges of Front Left wheel speed sensor output since IGN ON. eg. the wheel plate have 54 teeth/cycle, then the edges are 108 per cycle, please contact OEM for the wheel speed sensor information. )";
CM_ SG_ 1317 IC_Checksum_0x525 "checksum  is Byte XOR except checksum byte. 

Checksum: Byte0 XOR Byte1 XOR Byte2 XOR Byte3 XOR Byte4 XOR Byte5 XOR Byte6";
CM_ SG_ 1317 IC_Rolling_counter_0x525 "we used 4bit length signal and the arithmetic is increased from 0 to 15 by every message.";
CM_ SG_ 1317 IC_ManRgen_D_Rq "手动再生请求";
CM_ SG_ 1317 IC_Fuel_Level_VolumnQF "燃油液位可靠信号";
CM_ SG_ 1317 IC_Fuel_Level_Volumn "燃油液位信号";
CM_ SG_ 1317 IC_AlarmStatus "IC报警状态";
CM_ SG_ 1317 IC_AlarmOrNot "IC有无报警";
CM_ SG_ 1317 IC_DTE "仪表显示续航里程";
CM_ SG_ 1317 IC_AFC "仪表显示平均油耗";
CM_ SG_ 1296 IC_Checksum_0x510 "checksum  is Byte XOR except checksum byte. 

Checksum: Byte0 XOR Byte1 XOR Byte2 XOR Byte3 XOR Byte4 XOR Byte5 XOR Byte6";
CM_ SG_ 1296 IC_Rolling_counter_0x510 "we used 4bit length signal and the arithmetic is increased from 0 to 15 by every message.";
CM_ SG_ 1296 IC_DISFail "Error in the display or display control unit.";
CM_ SG_ 1296 IC_QDashACCFail "Error in the ACC message detected by the HMI, like timeout or alivecounter error.
The error should distinguish reversible and irreversible errors.";
CM_ SG_ 1296 IC_VehSpd_HMI "dashbroad calculate the Vehicle speed ";
CM_ SG_ 1296 IC_AirbagTelltaleBehavior "indicate cluster behavior for airbag telltale";
CM_ SG_ 1296 IC_OdometerMasterValue "Odometer Record from the IPC (Instrument Panel Cluster).
0xF4240~0xFFFFFF: Invalid";
CM_ SG_ 1333 MP5_DoorLockOnKeySetting "设置DoubleUnLock";
CM_ SG_ 1333 MP5_AutoWiperSetting "自动雨刮设置";
CM_ SG_ 1333 MP5_DayRunningLampsetting "日间行车灯使能设置";
CM_ SG_ 1333 MP5_FrontWiperMaintainSetting "前雨刮维修模式使能设置";
CM_ SG_ 1333 MP5_BGLLumLvlSetting "设置背景光亮度（BGL=background light）";
CM_ SG_ 1333 MP5_RemoteBodyControlSetting "菜单设置远程车身控制";
CM_ SG_ 1333 MP5_RemoteStartSetting "菜单设置远程启动";
CM_ SG_ 1333 MP5_SmartLockSetting "菜单设置自动解锁及离车落锁
WAL_UIR";
CM_ SG_ 1333 MP5_SpeedLockSetting "设置车速上锁";
CM_ SG_ 1333 MP5_RearDefrosterSetting "设置后除霜输出时间";
CM_ SG_ 1333 MP5_RoomLampSetting "设置室内灯节能时间";
CM_ SG_ 1333 MP5_HomesafeLampSetting "设置伴我回家大灯延时时间";
CM_ SG_ 1415 VinfoFromGW "VinfoFromGW";
CM_ SG_ 1330 MP5_DoorLock_Cmd "车门解闭锁指令";
CM_ SG_ 1328 MP5_PrdeProt_ON_OFF "行人保护开启关闭状态";
CM_ SG_ 1328 MP5_DOA_Active "DOA 开门预警使能开关信号";
CM_ SG_ 1328 MP5_CTA_Active "CTA 后方车辆穿行预警使能开关信号";
CM_ SG_ 1328 MP5_BSDLCA_Active "BSDLCA使能开关信号";
CM_ SG_ 1328 MP5_DDDMenuReq "DDD 疲劳预警使能开关信号";
CM_ SG_ 1328 MP5_TSRMenuReq "TSR 限速使能开关信号";
CM_ SG_ 1328 MP5_IHCMenuReq "IHC 自动大灯使能开关信号";
CM_ SG_ 1328 MP5_LDWWarning "车道偏离报警方式设置";
CM_ SG_ 1328 MP5_LDWSensitvity "LDW灵敏度";
CM_ SG_ 1328 MP5_LaneAssitTypeReq "Request operation mode of LKS";
CM_ SG_ 1328 MP5_LDWLKASwitchSts "LKALDW使能开启状态LaneAssitstsenable";
CM_ SG_ 1328 MP5_AlarmStatus "MP5报警状态";
CM_ SG_ 1328 MP5_AlarmOrNot "MP5有无报警";
CM_ SG_ 1328 MP5_AEB_ON_OFF "AEB制动功能开启状态";
CM_ SG_ 1328 MP5_FCW_ON_OFF "AEB报警开启状态";
CM_ SG_ 1328 MP5_BSDSwitchSts "BSD盲点监测使能开关信号";
CM_ SG_ 1328 MP5_FCW_Sensitive "FCW_Sensitive switch";
CM_ SG_ 1412 BCM_Checksum_0x584 "checksum  is Byte XOR except checksum byte. 

Checksum: Byte0 XOR Byte1 XOR Byte2 XOR Byte3 XOR Byte4 XOR Byte5 XOR Byte6";
CM_ SG_ 1412 BCM_Rolling_counter_0x584 "we used 4bit length signal and the arithmetic is increased from 0 to 15 by every message.";
CM_ SG_ 1412 BCM_LoadManageLevel "能量管理等级";
CM_ SG_ 1412 BCM_OTAModeStatus "BCM OTA Mode Status";
CM_ SG_ 1412 BCM_OTAStsFeedback "BCM OTA status feed back";
CM_ SG_ 1412 BCM_CarModeIndicator "Car Mode signal for HMI";
CM_ SG_ 1412 BCM_CarMode "Car Mode signal";
CM_ SG_ 1344 AC_RemoteControlMode "远控空调状态";
CM_ SG_ 1344 AC_Status "IVI上显示压缩机状态信号";
CM_ SG_ 1344 AC_TempSetStatus_Low "低配车型空调温度状态";
CM_ SG_ 1344 AC_Blower_Level "鼓风机风量档位";
CM_ SG_ 1344 AC_Mode_Status "AC模式状态";
CM_ SG_ 1344 AC_Intake_Status "AC进气循环状态";
CM_ SG_ 1344 AC_LCD_Status "显示屏是否显示状态";
CM_ SG_ 773 AC_MaxVoltageRq "AC请求最大电压";
CM_ SG_ 866 LRI_Pressure_Warning "LRI  tire pressure warning status";
CM_ SG_ 866 RRI_Pressure_Warning "RRI tire pressure warning status";
CM_ SG_ 866 LRI_Pressure "LRI   tire pressure";
CM_ SG_ 866 RRI_Pressure "RRI   tire pressure";
CM_ SG_ 865 TPMS_Lamp_Status "indicate LampStatus(this signal is reserved)";
CM_ SG_ 865 Tire_Position "TirePosition";
CM_ SG_ 865 resrved "resrved";
CM_ SG_ 865 Temperature_Warning "TemperatureWarning";
CM_ SG_ 865 LR_Pressure_Warning "左后外胎压报警";
CM_ SG_ 865 RR_Pressure_Warning "右后外胎压报警";
CM_ SG_ 865 System_Status "SystemStatus";
CM_ SG_ 865 RF_Pressure_Warning "RF tire pressure warning status";
CM_ SG_ 865 LF_Pressure_Warning "LF tire pressure warning status";
CM_ SG_ 865 Tire_Temperature "Tire temperature";
CM_ SG_ 865 LR_Pressure "左后外轮胎压力值";
CM_ SG_ 865 RR_Pressure "右后外轮胎压力值";
CM_ SG_ 865 RF_Pressure "Right front tire pressure";
CM_ SG_ 865 LF_Pressure "Left front tire pressure";
CM_ SG_ 82 PEPS_LearningSK64 "sent SK when learning at EOL";
CM_ SG_ 80 PEPS_EmsAuth "PEPS和EMS认证值";
CM_ SG_ 420 PEPS_TBOXAuth "PEPS和T-BOX认证值";
CM_ SG_ 421 PEPS_Checksum_0x1A5 "For safety-related signals，We recommend checksum  is Byte XOR except checksum byte. 
Checksum: Byte0 XOR Byte1 XOR Byte2 XOR Byte3 XOR Byte4 XOR Byte5 XOR Byte6";
CM_ SG_ 421 PEPS_RollingCounter_0x1A5 "we used 4bit length signal and the arithmetic is increased from 0 to 15 by every message.
         ";
CM_ SG_ 421 PEPS_RemainStartSec "剩余启动时间(秒）";
CM_ SG_ 421 PEPS_RemainStartMin "剩余启动时间(分）";
CM_ SG_ 421 PEPS_MaxTeleEngStartTimerfeedbac "PEPS的最大启动时间feedback,4-30分钟有效";
CM_ SG_ 421 PEPS_RemoteStartFaliureCode "远程启动失败原因";
CM_ SG_ 421 PEPS_RemotePwrSplySts "远程控制模式下电源档位";
CM_ SG_ 421 PEPS_StartrequestValid "启动请求有效";
CM_ SG_ 421 PEPS_StartrequestType "启动请求";
CM_ SG_ 421 PEPS_Remotestartstatus "远程启动状态";
CM_ SG_ 805 PEPS_Checksum_0x325 "For safety-related signals，We recommend checksum  is Byte XOR except checksum byte. 
For example: Message 0x123 , have 8 byte : byte 1，byte2，byte3，byte4，byte5，byte6，byte7，byte8, We define byte8 to Checksum.
So Checksum arithmetic is  byte8 = byte 1 XOR byte2 XOR byte3 XOR byte4 XOR byte5 XOR byte6 XOR byte7.
Please comfirm this, and feedback which signal or message need checksum arithmetic.";
CM_ SG_ 805 PEPS_RollingCounter_0x325 "we used 4bit length signal and the arithmetic is increased from 0 to 15 by every message.
         For example: Message 0x123,the first message sent RollingCounter signal value:0x0,then second message sent 0x1……
";
CM_ SG_ 805 PEPS_OTAModeStatus "OTA状态切换";
CM_ SG_ 805 PEPS_OTAStatus "OTA状态";
CM_ SG_ 805 PEPS_KeyBatteryWarning "PEPS_FOBLowBATWarning
遥控器电池低电压提醒";
CM_ SG_ 805 PEPS_KeyOutWarning1 "KeyOutWarning#1
遥控器在车外";
CM_ SG_ 805 PEPS_NoKeyFoundWarning "no key found after press SSB
按下SSB后未找到钥匙（或钥匙不合法）";
CM_ SG_ 805 PEPS_KeyReminderWarning "Key Reminder Warning#1
钥匙提醒";
CM_ SG_ 805 PEPS_ClutchIndicationWarning "The driver shall be informed, if he has to press clutch
踩下离合踏板";
CM_ SG_ 805 PEPS_BrakeIndicationWarning "The driver shall be informed, if he has to press brake pedal
踩下刹车踏板";
CM_ SG_ 805 PEPS_ESCL_NotLockWarn " ESCL Not Lock WarningESCL未上锁";
CM_ SG_ 805 PEPS_ESCL_NotUnlockWarning "ESCL Not Unlock WarningESCL未解锁";
CM_ SG_ 805 PEPS_Forbidden_FOB "Forbidden of FOB钥匙禁用";
CM_ SG_ 805 PEPS_CurrentValid_FOB "current valid of FOB ID当前激活钥匙编号";
CM_ SG_ 805 PEPS_SystemFailStatus "PEPS fail statusPEPS故障信号";
CM_ SG_ 805 PEPS_ESCL_FailStatus "ESCL Fail WarningESCL失效";
CM_ SG_ 805 PEPS_SSB_FailStatus "SSB fail status一键启动开关失效";
CM_ SG_ 805 PEPS_NotNWarning " Shift N Warning （只适用于MT和AMT车型）
不在N档";
CM_ SG_ 805 PEPS_StartRequest "PEPS start requestPEPS启动请求（for EMS）";
CM_ SG_ 805 PEPS_IMMO_MatchStatus "PEPS of IMMO match status(with EMS)
IMMO 匹配状态(与EMS)";
CM_ SG_ 805 PEPS_ClutchPedalStatus_MT "Clutch Pedal Status 离合踏板状态（MT车型）";
CM_ SG_ 805 PEPS_BrakePedalStatus "PEPS_Brake pedal status制动踏板状态";
CM_ SG_ 805 PEPS_ESCL_LearningStatus "ESCL learning statusESCL学习（匹配）状态";
CM_ SG_ 805 PEPS_ESCL_LockStatus "ESCL Lock/Unlock statusESCL上锁/解锁状态";
CM_ SG_ 805 PEPS_IGN2RelayStsStatus "IG2 RelaysStatusIG2继电器状态，启动断电";
CM_ SG_ 805 PEPS_IGN1RelayStsStatus "IG1 RelaysStatusIG1继电器状态";
CM_ SG_ 805 PEPS_PowerModeInvalid "PEPS Power Status value valid,PEPS永远发送0x0 valid";
CM_ SG_ 805 PEPS_PowerMode "PEPS Power Distribution Status";
CM_ SG_ 804 PEPS_EsclLockEnable "ESCL上锁使能";
CM_ SG_ 804 PEPS_RemoteStartSettingStatus "远程启动设置状态";
CM_ SG_ 804 PEPS_SmartLockSettingStatus "自动解锁及离车落锁设置状态";
CM_ SG_ 804 PEPS_RKE_Command "遥控指令";
CM_ SG_ 804 PEPS_Nea_LeaveToVehicle "智能钥匙靠近车辆状态";
CM_ SG_ 804 PEPS_KeyReminderUnlock "钥匙遗留车内解锁";
CM_ SG_ 806 RF_OperationStatus "RF工作模式";
CM_ SG_ 806 RF_TurningLightLearningRemind "转向灯手动学习闪烁提示";
CM_ SG_ 806 RF_KeyLowBatteryWarning "钥匙低压报警信号";
CM_ SG_ 806 RF_RKE_Command "遥控指令";
CM_ SG_ 902 IC_BSDSoundSts "BSD声音报警状态信号";
CM_ SG_ 898 MP5_BSDSoundSwitchSts "BSD声音设置信号";
CM_ SG_ 914 IC_ChangOilDistance "保养里程";
CM_ SG_ 914 IC_AverageSpeed "平均车速";
CM_ SG_ 914 IC_DriveTimeMinute "行驶时间分钟";
CM_ SG_ 914 IC_DriveTimehour "行驶时间小时";
CM_ SG_ 914 IC_Fuel_level "剩余燃油百分比";
CM_ SG_ 1347 EBS_Q_Discharge "accunmulated battery discharge";
CM_ SG_ 1347 EBS_Q_Charge "accunmulated battery charge";
CM_ SG_ 1346 EBS_SOH_COR_STATE "SOH_COR Status";
CM_ SG_ 1346 EBS_SOH_LAM_STATE "SOH_LAM Status";
CM_ SG_ 1346 EBS_SOFV_Restart_STATE "SOFV_Restart Status";
CM_ SG_ 1346 EBS_SOFV_StopEnable_STATE "SOFV_StopEnable Status";
CM_ SG_ 1346 EBS_SOH_SUL_STATE "SOH_SUL_STATE";
CM_ SG_ 1346 EBS_SOC_state "SOC status";
CM_ SG_ 1346 EBS_SOH_COR "State of health(corrosion)";
CM_ SG_ 1346 EBS_SOH_LAM "State of health(Loss of Active Mass)";
CM_ SG_ 1346 EBS_SOFV_Restart "Battery voltage at cranking peak without pre-discharge";
CM_ SG_ 1346 EBS_SOFV_StopEnable "Battery voltage at cranking peak with pre-discharge";
CM_ SG_ 1346 EBS_SOH_SUL "max. possible SOC,reduced by sulphation";
CM_ SG_ 1346 EBS_SOC "State of Charge";
CM_ SG_ 1345 EBS_FLAG_INCONSISTENCY "Battery inconsistency flag";
CM_ SG_ 1345 EBS_Resp_Error "Response Error(LIN specific)";
CM_ SG_ 1345 EBS_Error_Ident "error in ECU identification";
CM_ SG_ 1345 EBS_Error_Calib "error in calibration data";
CM_ SG_ 1345 EBS_Status_Temp "Temperature status";
CM_ SG_ 1345 EBS_Status_Voltage "voltage status";
CM_ SG_ 1345 EBS_Status_Current "current status";
CM_ SG_ 1345 EBS_IBATT_QUIESCENT "quiescent current";
CM_ SG_ 1345 EBS_T_BATT "Battery temperature";
CM_ SG_ 1345 EBS_I_BATT "Battery current ";
CM_ SG_ 1345 EBS_I_RANGE "Battery current range";
CM_ SG_ 1345 EBS_U_BATT "Battery voltage";
CM_ SG_ 789 BCM_AutoWiperSettingStatus "自动雨刮设置状态";
CM_ SG_ 789 BCM_SpeedLockSettingStatus "车速上锁设置状态";
CM_ SG_ 789 BCM_DayRunningLampsettingSts "日间行车灯使能设置状态";
CM_ SG_ 789 BCM_BGLLumLvlSettingStatus "背景光亮度状态（BGL=background light）";
CM_ SG_ 789 BCM_DoorLockOnKeySettingSts "设置DoubleUnLock状态";
CM_ SG_ 789 BCM_FrontWiperMaintainSettingSts "前雨刮维修模式使能设置";
CM_ SG_ 789 BCM_RemoteBodyControlSettingStat "远程车身控制";
CM_ SG_ 789 BCM_RearDefrosterSettingStatus "后除霜输出时间设置状态";
CM_ SG_ 789 BCM_RoomLampSettingStatus "室内灯节能时间设置状态";
CM_ SG_ 789 BCM_HomesafeLampSettingStatus "伴我回家大灯延时时间设置状态";
CM_ SG_ 787 BCM_Checksum_0x313 "checksum  is Byte XOR except checksum byte. 

Checksum: Byte0 XOR Byte1 XOR Byte2 XOR Byte3 XOR Byte4 XOR Byte5 XOR Byte6";
CM_ SG_ 787 BCM_Rollingcounter_0x313 "we used 4bit length signal and the arithmetic is increased from 0 to 15 by every message.";
CM_ SG_ 787 BCM_PowerModeInvalid "BCM Power Status value valid";
CM_ SG_ 787 BCM_PowerMode "BCM电源信号";
CM_ SG_ 787 BCM_Reverse_gear "Gear in Reverse，both in MT and AT。倒档信号";
CM_ SG_ 787 BCM_Start_Switch "点火开关Start信号";
CM_ SG_ 787 BCM_OutsideTempDig "室外温度诊断信号";
CM_ SG_ 787 BCM_OutsideTemp "Ambient Air Temperature室外温度信号";
CM_ SG_ 787 BCM_Mechanical_Hand_Brake "Binary information whether the handbrake is applied  or not. Measured signal from the handbrake switch.机械手刹信号";
CM_ SG_ 787 BCM_RearDef_Status "后除霜状态";
CM_ SG_ 787 BCM_BrakeFluidSts "制动液位报警";
CM_ SG_ 792 BCM_Checksum_0x318 "checksum  is Byte XOR except checksum byte. 

Checksum: Byte0 XOR Byte1 XOR Byte2 XOR Byte3 XOR Byte4 XOR Byte5 XOR Byte6";
CM_ SG_ 792 BCM_Rollingcounter_0x318 "we used 4bit length signal and the arithmetic is increased from 0 to 15 by every message.";
CM_ SG_ 792 BCM_ImmoSts "IMMO认证状态";
CM_ SG_ 792 BCM_DayRunningLampDig "日间行车灯诊断信号";
CM_ SG_ 792 BCM_BrakelightDig "制动灯诊断信号";
CM_ SG_ 792 BCM_reversinglightDig "倒车灯诊断信号";
CM_ SG_ 792 BCM_TurnIndicatorDig "转向灯诊断信号";
CM_ SG_ 792 BCM_RearFogLmpDig "后雾灯诊断信号";
CM_ SG_ 792 BCM_PosLmpDig "位置灯诊断信号";
CM_ SG_ 792 BCM_BackHomeSts "伴我回家功能状态";
CM_ SG_ 792 BCM_AutolampSts "自动大灯状态";
CM_ SG_ 792 BCM_readinglampSts "室内灯状态";
CM_ SG_ 792 BCM_Highmountedstoplamp "高位刹车灯状态";
CM_ SG_ 792 BCM_BrakelightSts "制动灯状态";
CM_ SG_ 792 BCM_reversinglightSts "倒车灯状态";
CM_ SG_ 792 BCM_DayRunningLampSts "日间行车灯状态";
CM_ SG_ 792 BCM_TurnIndicatorSts "转向灯状态";
CM_ SG_ 792 BCM_RearFogLmpSts "后雾灯状态";
CM_ SG_ 792 BCM_FrntFogLmpSts "前雾灯状态";
CM_ SG_ 792 BCM_PosLmpSts "位置灯状态";
CM_ SG_ 792 BCM_LowBeamSts "近光灯状态";
CM_ SG_ 792 BCM_HighBeamSts "远光灯状态";
CM_ SG_ 784 BCM_Checksum_0x310 "checksum  is Byte XOR except checksum byte. 

Checksum: Byte0 XOR Byte1 XOR Byte2 XOR Byte3 XOR Byte4 XOR Byte5 XOR Byte6";
CM_ SG_ 784 BCM_Rolling_counter_0x310 "we used 4bit length signal and the arithmetic is increased from 0 to 15 by every message.";
CM_ SG_ 784 BCM_EsclLockGndSts "ESCL上锁地输出状态";
CM_ SG_ 784 BCM_FrontWiperSts "前雨刮状态";
CM_ SG_ 784 BCM_EnginehoodSts "引擎盖状态";
CM_ SG_ 784 BCM_AntiTheftSts "BCM设防状态信号";
CM_ SG_ 784 BCM_LoadSensitivity "BCM LoadSensitivity";
CM_ SG_ 784 BCM_LockUnlockFeedback "上锁解锁方式信号";
CM_ SG_ 784 BCM_DoorLockStsTrunk "行李箱门锁状态";
CM_ SG_ 784 BCM_DoorStsTrunk "行李箱门状态";
CM_ SG_ 784 BCM_DoorLockStsRearRi "右后门锁状态";
CM_ SG_ 784 BCM_DoorLockStsRearLe "左后门锁状态";
CM_ SG_ 784 BCM_DoorLockStsFrntRi "右前门锁状态";
CM_ SG_ 784 BCM_DoorLockStsFrntLe "左前门锁状态";
CM_ SG_ 784 BCM_DoorStsRearRi "右后门状态";
CM_ SG_ 784 BCM_DoorStsRearLe "左后门状态";
CM_ SG_ 784 BCM_DoorStsFrntRi "右前门状态";
CM_ SG_ 784 BCM_DoorStsFrntLe "左前门状态";
BA_DEF_ SG_  "GenSigStartValue" INT 0 0;
BA_DEF_ SG_  "GenSigInvalidValue" INT 0 0;
BA_DEF_ SG_  "GenSigInactiveValue" INT 0 0;
BA_DEF_ BO_  "DiagMessage" ENUM  "No","Yes";
BA_DEF_ BO_  "NmMessage" ENUM  "No","Yes";
BA_DEF_ BO_  "GenMsgCycleTimeFast" INT 0 0;
BA_DEF_ BO_  "GenMsgNrOfRepetition" INT 0 0;
BA_DEF_ BO_  "GenMsgCycleTime" INT 0 0;
BA_DEF_ BO_  "GenMsgDelayTime" INT 0 0;
BA_DEF_ SG_  "GenSigSendType" ENUM  "Cyclic","OnWrite","OnWriteWithRepetition","OnChange","OnChangeWithRepetition","IfActive","IfActiveWithRepetition";
BA_DEF_ BO_  "GenMsgSendType" ENUM  "Cyclic","Event","IfActive","CE","CA";
BA_DEF_ BO_  "GenMsgILSupport" ENUM  "No","Yes";
BA_DEF_ BU_  "ILUsed" ENUM  "No","Yes";
BA_DEF_ SG_  "SystemSignalLongSymbol" STRING ;
BA_DEF_DEF_  "GenSigStartValue" 0;
BA_DEF_DEF_  "GenSigInvalidValue" 0;
BA_DEF_DEF_  "GenSigInactiveValue" 0;
BA_DEF_DEF_  "DiagMessage" "No";
BA_DEF_DEF_  "NmMessage" "No";
BA_DEF_DEF_  "GenMsgCycleTimeFast" 0;
BA_DEF_DEF_  "GenMsgNrOfRepetition" 0;
BA_DEF_DEF_  "GenMsgCycleTime" 0;
BA_DEF_DEF_  "GenMsgDelayTime" 0;
BA_DEF_DEF_  "GenSigSendType" "Cyclic";
BA_DEF_DEF_  "GenMsgSendType" "Cyclic";
BA_DEF_DEF_  "GenMsgILSupport" "Yes";
BA_DEF_DEF_  "ILUsed" "Yes";
BA_DEF_DEF_  "SystemSignalLongSymbol" "";
BA_ "GenMsgSendType" BO_ 423 3;
BA_ "GenMsgCycleTime" BO_ 423 1000;
BA_ "DiagMessage" BO_ 1899 1;
BA_ "GenMsgSendType" BO_ 1899 1;
BA_ "DiagMessage" BO_ 1891 1;
BA_ "GenMsgSendType" BO_ 1891 1;
BA_ "DiagMessage" BO_ 1851 1;
BA_ "GenMsgSendType" BO_ 1851 1;
BA_ "DiagMessage" BO_ 1843 1;
BA_ "GenMsgSendType" BO_ 1843 1;
BA_ "DiagMessage" BO_ 1839 1;
BA_ "GenMsgSendType" BO_ 1839 1;
BA_ "DiagMessage" BO_ 1831 1;
BA_ "GenMsgSendType" BO_ 1831 1;
BA_ "DiagMessage" BO_ 1850 1;
BA_ "GenMsgSendType" BO_ 1850 1;
BA_ "DiagMessage" BO_ 1842 1;
BA_ "GenMsgSendType" BO_ 1842 1;
BA_ "DiagMessage" BO_ 1848 1;
BA_ "GenMsgSendType" BO_ 1848 1;
BA_ "DiagMessage" BO_ 1840 1;
BA_ "GenMsgSendType" BO_ 1840 1;
BA_ "DiagMessage" BO_ 1865 1;
BA_ "GenMsgSendType" BO_ 1865 1;
BA_ "DiagMessage" BO_ 1857 1;
BA_ "GenMsgSendType" BO_ 1857 1;
BA_ "DiagMessage" BO_ 1849 1;
BA_ "GenMsgSendType" BO_ 1849 1;
BA_ "DiagMessage" BO_ 1841 1;
BA_ "GenMsgSendType" BO_ 1841 1;
BA_ "DiagMessage" BO_ 2015 1;
BA_ "GenMsgSendType" BO_ 2015 1;
BA_ "NmMessage" BO_ 1079 1;
BA_ "GenMsgSendType" BO_ 1079 1;
BA_ "NmMessage" BO_ 1075 1;
BA_ "GenMsgSendType" BO_ 1075 1;
BA_ "NmMessage" BO_ 1074 1;
BA_ "GenMsgSendType" BO_ 1074 1;
BA_ "NmMessage" BO_ 1072 1;
BA_ "GenMsgSendType" BO_ 1072 1;
BA_ "NmMessage" BO_ 1120 1;
BA_ "GenMsgSendType" BO_ 1120 1;
BA_ "NmMessage" BO_ 1073 1;
BA_ "GenMsgSendType" BO_ 1073 1;
BA_ "GenMsgSendType" BO_ 96 1;
BA_ "GenMsgCycleTime" BO_ 581 20;
BA_ "GenMsgCycleTime" BO_ 629 100;
BA_ "GenMsgCycleTime" BO_ 625 100;
BA_ "GenMsgCycleTime" BO_ 1409 500;
BA_ "GenMsgCycleTime" BO_ 1410 500;
BA_ "GenMsgCycleTime" BO_ 1413 200;
BA_ "GenMsgSendType" BO_ 419 1;
BA_ "GenMsgSendType" BO_ 418 3;
BA_ "GenMsgSendType" BO_ 417 3;
BA_ "GenMsgCycleTime" BO_ 291 20;
BA_ "GenMsgCycleTime" BO_ 917 100;
BA_ "GenMsgCycleTime" BO_ 1590 1000;
BA_ "GenMsgCycleTime" BO_ 872 100;
BA_ "GenMsgCycleTime" BO_ 870 100;
BA_ "GenMsgSendType" BO_ 99 1;
BA_ "GenMsgSendType" BO_ 98 1;
BA_ "GenMsgCycleTime" BO_ 267 10;
BA_ "GenMsgCycleTime" BO_ 337 20;
BA_ "GenMsgCycleTime" BO_ 582 20;
BA_ "GenMsgCycleTime" BO_ 579 20;
BA_ "GenMsgSendType" BO_ 795 3;
BA_ "GenMsgCycleTime" BO_ 795 100;
BA_ "GenMsgSendType" BO_ 794 3;
BA_ "GenMsgCycleTime" BO_ 794 100;
BA_ "GenMsgCycleTime" BO_ 608 20;
BA_ "GenMsgSendType" BO_ 848 3;
BA_ "GenMsgCycleTime" BO_ 848 100;
BA_ "GenMsgCycleTime" BO_ 530 20;
BA_ "GenMsgCycleTime" BO_ 545 20;
BA_ "GenMsgCycleTime" BO_ 1317 100;
BA_ "GenMsgCycleTime" BO_ 1296 100;
BA_ "GenMsgSendType" BO_ 1333 3;
BA_ "GenMsgCycleTime" BO_ 1333 200;
BA_ "GenMsgCycleTime" BO_ 1415 200;
BA_ "GenMsgSendType" BO_ 1330 3;
BA_ "GenMsgCycleTime" BO_ 1330 100;
BA_ "GenMsgSendType" BO_ 1328 3;
BA_ "GenMsgCycleTime" BO_ 1328 100;
BA_ "GenMsgCycleTime" BO_ 1412 200;
BA_ "GenMsgCycleTime" BO_ 1344 100;
BA_ "GenMsgCycleTime" BO_ 773 100;
BA_ "GenMsgCycleTime" BO_ 866 100;
BA_ "GenMsgCycleTime" BO_ 865 100;
BA_ "GenMsgSendType" BO_ 82 1;
BA_ "GenMsgSendType" BO_ 80 1;
BA_ "GenMsgSendType" BO_ 420 1;
BA_ "GenMsgCycleTime" BO_ 421 50;
BA_ "GenMsgCycleTime" BO_ 805 20;
BA_ "GenMsgSendType" BO_ 804 3;
BA_ "GenMsgCycleTime" BO_ 804 100;
BA_ "GenMsgSendType" BO_ 806 3;
BA_ "GenMsgCycleTime" BO_ 806 100;
BA_ "GenMsgCycleTime" BO_ 902 100;
BA_ "GenMsgSendType" BO_ 898 3;
BA_ "GenMsgCycleTime" BO_ 898 100;
BA_ "GenMsgCycleTime" BO_ 914 100;
BA_ "GenMsgCycleTime" BO_ 1347 100;
BA_ "GenMsgCycleTime" BO_ 1346 100;
BA_ "GenMsgCycleTime" BO_ 1345 100;
BA_ "GenMsgCycleTime" BO_ 789 200;
BA_ "GenMsgCycleTime" BO_ 787 20;
BA_ "GenMsgCycleTime" BO_ 792 100;
BA_ "GenMsgCycleTime" BO_ 784 20;
BA_ "GenSigSendType" SG_ 423 TBOX_HornCmd 3;
BA_ "GenSigSendType" SG_ 423 TBOX_TurnIndcrCtrlCmd 3;
BA_ "GenSigSendType" SG_ 423 TBOX_DoorLockCmd 3;
BA_ "GenSigInvalidValue" SG_ 423 TBOX_DoorLockCmd 3;
BA_ "GenSigSendType" SG_ 1899 DiagRespFromTBOX 3;
BA_ "GenSigSendType" SG_ 1891 DiagPhysReqToTBOX 3;
BA_ "GenSigSendType" SG_ 1851 DiagRespFromRTM 3;
BA_ "GenSigSendType" SG_ 1843 DiagPhysReqToRTM 3;
BA_ "GenSigSendType" SG_ 1839 DiagRespFromMP5 3;
BA_ "GenSigSendType" SG_ 1831 DiagPhysReqToMP5 3;
BA_ "GenSigSendType" SG_ 1850 DiagRespFromPEPS 3;
BA_ "GenSigSendType" SG_ 1842 DiagPhysReqToPEPS 3;
BA_ "GenSigSendType" SG_ 1848 DiagRespFromIC 3;
BA_ "GenSigSendType" SG_ 1840 DiagPhysReqToIC 3;
BA_ "GenSigSendType" SG_ 1865 DiagRespFromAC 3;
BA_ "GenSigSendType" SG_ 1857 DiagPhysReqToAC 3;
BA_ "GenSigSendType" SG_ 1849 DiagRespFromBCM 3;
BA_ "GenSigSendType" SG_ 1841 DiagPhysReqToBCM 3;
BA_ "GenSigSendType" SG_ 2015 DiagFuncReq 3;
BA_ "GenSigSendType" SG_ 1079 RTMNMUserData 3;
BA_ "GenSigSendType" SG_ 1079 RTMNMAlive 3;
BA_ "GenSigSendType" SG_ 1079 RTMNMRing 3;
BA_ "GenSigSendType" SG_ 1079 RTMNMLimphome 3;
BA_ "GenSigSendType" SG_ 1079 RTMNMSleepInd 3;
BA_ "GenSigSendType" SG_ 1079 RTMNMSleepAck 3;
BA_ "GenSigSendType" SG_ 1079 RTMNMDestAddr 3;
BA_ "GenSigSendType" SG_ 1075 MP5NMUserData 3;
BA_ "GenSigSendType" SG_ 1075 MP5NMAlive 3;
BA_ "GenSigSendType" SG_ 1075 MP5NMRing 3;
BA_ "GenSigSendType" SG_ 1075 MP5NMLimphome 3;
BA_ "GenSigSendType" SG_ 1075 MP5NMSleepInd 3;
BA_ "GenSigSendType" SG_ 1075 MP5NMSleepAck 3;
BA_ "GenSigSendType" SG_ 1075 MP5NMDestAddr 3;
BA_ "GenSigSendType" SG_ 1074 PEPSNMUserData 3;
BA_ "GenSigSendType" SG_ 1074 PEPSNMAlive 3;
BA_ "GenSigSendType" SG_ 1074 PEPSNMRing 3;
BA_ "GenSigSendType" SG_ 1074 PEPSNMLimphome 3;
BA_ "GenSigSendType" SG_ 1074 PEPSNMSleepInd 3;
BA_ "GenSigSendType" SG_ 1074 PEPSNMSleepAck 3;
BA_ "GenSigSendType" SG_ 1074 PEPSNMDestAddr 3;
BA_ "GenSigSendType" SG_ 1072 ICNMUserData 3;
BA_ "GenSigSendType" SG_ 1072 ICNMAlive 3;
BA_ "GenSigSendType" SG_ 1072 ICNMRing 3;
BA_ "GenSigSendType" SG_ 1072 ICNMLimphome 3;
BA_ "GenSigSendType" SG_ 1072 ICNMSleepInd 3;
BA_ "GenSigSendType" SG_ 1072 ICNMSleepAck 3;
BA_ "GenSigSendType" SG_ 1072 ICNMDestAddr 3;
BA_ "GenSigSendType" SG_ 1120 GWNMUserData 3;
BA_ "GenSigSendType" SG_ 1120 GWNMAlive 3;
BA_ "GenSigSendType" SG_ 1120 GWNMRing 3;
BA_ "GenSigSendType" SG_ 1120 GWNMLimphome 3;
BA_ "GenSigSendType" SG_ 1120 GWNMSleepInd 3;
BA_ "GenSigSendType" SG_ 1120 GWNMSleepAck 3;
BA_ "GenSigSendType" SG_ 1120 GWNMDestAddr 3;
BA_ "GenSigSendType" SG_ 1073 BCMNMUserData 3;
BA_ "GenSigSendType" SG_ 1073 BCMNMAlive 3;
BA_ "GenSigSendType" SG_ 1073 BCMNMRing 3;
BA_ "GenSigSendType" SG_ 1073 BCMNMLimphome 3;
BA_ "GenSigSendType" SG_ 1073 BCMNMSleepInd 3;
BA_ "GenSigSendType" SG_ 1073 BCMNMSleepAck 3;
BA_ "GenSigSendType" SG_ 1073 BCMNMDestAddr 3;
BA_ "GenSigSendType" SG_ 96 EMS_EngAuthentResult 3;
BA_ "GenSigInvalidValue" SG_ 581 IPM_LaneAssit_TorqueValidity 1;
BA_ "GenSigInvalidValue" SG_ 581 IPM_LaneAssit_TorqueReq 2047;
BA_ "GenSigStartValue" SG_ 581 IPM_LaneAssit_TorqueReq 1024;
BA_ "GenSigInvalidValue" SG_ 625 PAM_Sts 7;
BA_ "GenSigInvalidValue" SG_ 625 PAM_ParkingBarpercent 255;
BA_ "GenSigStartValue" SG_ 1409 IC_Date 1;
BA_ "GenSigStartValue" SG_ 1409 IC_Month 1;
BA_ "GenSigStartValue" SG_ 1410 TBOX_Date 1;
BA_ "GenSigStartValue" SG_ 1410 TBOX_Month 1;
BA_ "GenSigSendType" SG_ 419 TBOX_PEPSAuth 3;
BA_ "GenSigSendType" SG_ 418 TBOX_AcWorkCmd 3;
BA_ "GenSigSendType" SG_ 417 TBOX_MaxTeleEngStartTimer 3;
BA_ "GenSigInvalidValue" SG_ 417 TBOX_MaxTeleEngStartTimer 31;
BA_ "GenSigSendType" SG_ 417 TBOX_EngCtrlCmd 3;
BA_ "GenSigInvalidValue" SG_ 417 TBOX_EngCtrlCmd 3;
BA_ "GenSigInvalidValue" SG_ 291 TCU_StGearMode 15;
BA_ "GenSigInvalidValue" SG_ 291 TCU_OverallRatio 2047;
BA_ "GenSigInvalidValue" SG_ 291 TCU_ShiftLeverPos_SBWM 7;
BA_ "GenSigStartValue" SG_ 291 TCU_ShiftLeverPos_SBWM 7;
BA_ "GenSigInvalidValue" SG_ 291 TCU_DisplayGear 15;
BA_ "GenSigInvalidValue" SG_ 291 TCU_GearSelectorReq 15;
BA_ "GenSigInvalidValue" SG_ 291 TCU_TargetGearReq 15;
BA_ "GenSigInvalidValue" SG_ 291 TCU_CurrentGearPosition 15;
BA_ "GenSigInvalidValue" SG_ 1590 EMS_BackupOdometer 4294967295;
BA_ "GenSigInvalidValue" SG_ 872 EMS_TroqLimtMin 63;
BA_ "GenSigInvalidValue" SG_ 872 EMS_TroqLimtHour 63;
BA_ "GenSigInvalidValue" SG_ 872 EMS_SpeedLimtMin 63;
BA_ "GenSigInvalidValue" SG_ 872 EMS_SpeedLimtHour 63;
BA_ "GenSigInvalidValue" SG_ 872 EMS_Soot_Pc_Dsply 127;
BA_ "GenSigInvalidValue" SG_ 872 EMS_UreaLvl 255;
BA_ "GenSigInvalidValue" SG_ 870 EMS_TargetGearPostion_MT 15;
BA_ "GenSigSendType" SG_ 99 EMS_SentSK64 3;
BA_ "GenSigSendType" SG_ 98 EMS_Eng_PEPSAuth 3;
BA_ "GenSigInvalidValue" SG_ 267 EMS_EngSpeed 32767;
BA_ "GenSigInvalidValue" SG_ 267 EMS_BatterVoltage 255;
BA_ "GenSigStartValue" SG_ 267 EMS_BatterVoltage 171;
BA_ "GenSigInvalidValue" SG_ 267 EMS_EngCoolanTemp 255;
BA_ "GenSigInvalidValue" SG_ 337 EMS_EngBarometricPressure 255;
BA_ "GenSigInvalidValue" SG_ 337 EMS_VacuumPressure 1023;
BA_ "GenSigStartValue" SG_ 337 EMS_VacuumPressure 972;
BA_ "GenSigInvalidValue" SG_ 337 EMS_EngOffTime 65535;
BA_ "GenSigInvalidValue" SG_ 337 EMS_TargCruiseSpeed 511;
BA_ "GenSigInvalidValue" SG_ 582 MRR_vSetDis 511;
BA_ "GenSigStartValue" SG_ 579 ESP_TcsFlgFlt 1;
BA_ "GenSigStartValue" SG_ 579 ESP_VdcFlgFlt 1;
BA_ "GenSigInvalidValue" SG_ 579 ESP_Driving_mode_req 15;
BA_ "GenSigSendType" SG_ 795 Checksum_0x31B 3;
BA_ "GenSigSendType" SG_ 795 Rolling_counter_0x31B 3;
BA_ "GenSigSendType" SG_ 795 SWM_ACCLimpHomeSts 3;
BA_ "GenSigSendType" SG_ 795 SWM_LaneAssistSwitch 3;
BA_ "GenSigSendType" SG_ 795 SWM_ACCtauGapSetMinus 3;
BA_ "GenSigSendType" SG_ 795 SWM_ACCtauGapSetPlus 3;
BA_ "GenSigSendType" SG_ 795 SWM_ACCvSetMinus 3;
BA_ "GenSigSendType" SG_ 795 SWM_ACCvSetPlus 3;
BA_ "GenSigSendType" SG_ 795 SWM_ACCSet 3;
BA_ "GenSigSendType" SG_ 795 SWM_ACCCancelResume 3;
BA_ "GenSigSendType" SG_ 795 SWM_ACCEnableSwitch 3;
BA_ "GenSigSendType" SG_ 794 SWM_Checksum_0x31A 3;
BA_ "GenSigSendType" SG_ 794 SWM_Rolling_counter_0x31A 3;
BA_ "GenSigSendType" SG_ 794 SWM_Menu_Confirm 3;
BA_ "GenSigInvalidValue" SG_ 794 SWM_Menu_Confirm 3;
BA_ "GenSigSendType" SG_ 794 SWM_Menu_Right 3;
BA_ "GenSigInvalidValue" SG_ 794 SWM_Menu_Right 3;
BA_ "GenSigSendType" SG_ 794 SWM_Menu_Left 3;
BA_ "GenSigInvalidValue" SG_ 794 SWM_Menu_Left 3;
BA_ "GenSigSendType" SG_ 794 SWM_Menu_Down 3;
BA_ "GenSigInvalidValue" SG_ 794 SWM_Menu_Down 3;
BA_ "GenSigSendType" SG_ 794 SWM_Menu_Up 3;
BA_ "GenSigInvalidValue" SG_ 794 SWM_Menu_Up 3;
BA_ "GenSigSendType" SG_ 794 SWM_VOICE 3;
BA_ "GenSigSendType" SG_ 794 SWM_MODE 3;
BA_ "GenSigSendType" SG_ 794 SWM_Next_Song 3;
BA_ "GenSigInvalidValue" SG_ 794 SWM_Next_Song 3;
BA_ "GenSigSendType" SG_ 794 SWM_Previous_Song 3;
BA_ "GenSigInvalidValue" SG_ 794 SWM_Previous_Song 3;
BA_ "GenSigSendType" SG_ 794 SWM_VOL_Plus 3;
BA_ "GenSigInvalidValue" SG_ 794 SWM_VOL_Plus 3;
BA_ "GenSigSendType" SG_ 794 SWM_VOL_Minus 3;
BA_ "GenSigInvalidValue" SG_ 794 SWM_VOL_Minus 3;
BA_ "GenSigSendType" SG_ 794 SWM_RearFogLight 3;
BA_ "GenSigInvalidValue" SG_ 794 SWM_RearFogLight 3;
BA_ "GenSigInvalidValue" SG_ 794 SWM_FrontFogLight 3;
BA_ "GenSigInvalidValue" SG_ 794 SWM_HeadLamp 4;
BA_ "GenSigSendType" SG_ 794 SWM_FlashLightSts 3;
BA_ "GenSigInvalidValue" SG_ 794 SWM_FlashLightSts 3;
BA_ "GenSigInvalidValue" SG_ 794 SWM_FrontWipingMode 7;
BA_ "GenSigInvalidValue" SG_ 794 SWM_TurnIndicationAct 3;
BA_ "GenSigInvalidValue" SG_ 794 SWM_WipingInterval_Sensitvity 7;
BA_ "GenSigSendType" SG_ 794 SWM_HighBeam 3;
BA_ "GenSigInvalidValue" SG_ 794 SWM_HighBeam 3;
BA_ "GenSigSendType" SG_ 794 SWM_WasherLimpHomeSts 3;
BA_ "GenSigSendType" SG_ 794 SWM_FWasherSts 3;
BA_ "GenSigInvalidValue" SG_ 794 SWM_FWasherSts 3;
BA_ "GenSigStartValue" SG_ 608 EPS_S_SafeLampRed 1;
BA_ "GenSigStartValue" SG_ 848 SRS_SBR_Passenger 2;
BA_ "GenSigStartValue" SG_ 848 SRS_SBR_Driver 2;
BA_ "GenSigSendType" SG_ 848 SRS_CrashOutputSts 4;
BA_ "GenSigInvalidValue" SG_ 530 ESP_vxwWheelRRValid 1;
BA_ "GenSigInvalidValue" SG_ 530 ESP_vxwWheelRLValid 1;
BA_ "GenSigInvalidValue" SG_ 530 ESP_vxwWheelFRValid 1;
BA_ "GenSigInvalidValue" SG_ 530 ESP_vxwWheelFLValid 1;
BA_ "GenSigInvalidValue" SG_ 530 ESP_vxwWheelRawRR 4095;
BA_ "GenSigInvalidValue" SG_ 530 ESP_vxwWheelRawRL 4095;
BA_ "GenSigInvalidValue" SG_ 530 ESP_vxwWheelRawFR 4095;
BA_ "GenSigInvalidValue" SG_ 530 ESP_vxwWheelRawFL 4095;
BA_ "GenSigInvalidValue" SG_ 545 ABS_WhlMilgFrntLeStatus 1;
BA_ "GenSigStartValue" SG_ 545 ABS_WhlMilgFrntLeStatus 1;
BA_ "GenSigInvalidValue" SG_ 545 ABS_WhlMilgFrntRiStatus 1;
BA_ "GenSigStartValue" SG_ 545 ABS_WhlMilgFrntRiStatus 1;
BA_ "GenSigInvalidValue" SG_ 545 ABS_VehSpdLgtStatus 1;
BA_ "GenSigStartValue" SG_ 545 ABS_VehSpdLgtStatus 2;
BA_ "GenSigStartValue" SG_ 545 ABS_AbsFlgFlt 1;
BA_ "GenSigStartValue" SG_ 545 ABS_EbdFlgFlt 1;
BA_ "GenSigInvalidValue" SG_ 545 ABS_VehSpdLgt 4095;
BA_ "GenSigStartValue" SG_ 1317 IC_Fuel_Level_VolumnQF 1;
BA_ "GenSigInvalidValue" SG_ 1317 IC_Fuel_Level_Volumn 8191;
BA_ "GenSigInvalidValue" SG_ 1317 IC_DTE 4095;
BA_ "GenSigInvalidValue" SG_ 1317 IC_AFC 511;
BA_ "GenSigInvalidValue" SG_ 1296 IC_VehSpd_HMI 511;
BA_ "GenSigInvalidValue" SG_ 1296 IC_OdometerMasterValue 16777215;
BA_ "GenSigSendType" SG_ 1333 MP5_DoorLockOnKeySetting 3;
BA_ "GenSigStartValue" SG_ 1333 MP5_DoorLockOnKeySetting 1;
BA_ "GenSigSendType" SG_ 1333 MP5_AutoWiperSetting 3;
BA_ "GenSigStartValue" SG_ 1333 MP5_AutoWiperSetting 1;
BA_ "GenSigSendType" SG_ 1333 MP5_DayRunningLampsetting 3;
BA_ "GenSigStartValue" SG_ 1333 MP5_DayRunningLampsetting 1;
BA_ "GenSigSendType" SG_ 1333 MP5_FrontWiperMaintainSetting 3;
BA_ "GenSigSendType" SG_ 1333 MP5_BGLLumLvlSetting 3;
BA_ "GenSigStartValue" SG_ 1333 MP5_BGLLumLvlSetting 80;
BA_ "GenSigSendType" SG_ 1333 MP5_RemoteBodyControlSetting 3;
BA_ "GenSigSendType" SG_ 1333 MP5_RemoteStartSetting 3;
BA_ "GenSigSendType" SG_ 1333 MP5_SmartLockSetting 3;
BA_ "GenSigSendType" SG_ 1333 MP5_SpeedLockSetting 3;
BA_ "GenSigSendType" SG_ 1333 MP5_RearDefrosterSetting 3;
BA_ "GenSigStartValue" SG_ 1333 MP5_RearDefrosterSetting 1;
BA_ "GenSigSendType" SG_ 1333 MP5_RoomLampSetting 3;
BA_ "GenSigStartValue" SG_ 1333 MP5_RoomLampSetting 1;
BA_ "GenSigSendType" SG_ 1333 MP5_HomesafeLampSetting 3;
BA_ "GenSigStartValue" SG_ 1333 MP5_HomesafeLampSetting 2;
BA_ "GenSigSendType" SG_ 1330 MP5_DoorLock_Cmd 4;
BA_ "GenSigStartValue" SG_ 1328 MP5_LDWWarning 1;
BA_ "GenSigStartValue" SG_ 1344 AC_Status 1;
BA_ "GenSigSendType" SG_ 1344 AC_TempSetStatus_Low 3;
BA_ "GenSigInvalidValue" SG_ 1344 AC_TempSetStatus_Low 31;
BA_ "GenSigSendType" SG_ 1344 AC_Blower_Level 3;
BA_ "GenSigInvalidValue" SG_ 1344 AC_Blower_Level 15;
BA_ "GenSigStartValue" SG_ 1344 AC_Blower_Level 15;
BA_ "GenSigSendType" SG_ 1344 AC_Mode_Status 3;
BA_ "GenSigStartValue" SG_ 1344 AC_Mode_Status 1;
BA_ "GenSigSendType" SG_ 1344 AC_Intake_Status 3;
BA_ "GenSigStartValue" SG_ 1344 AC_Intake_Status 1;
BA_ "GenSigSendType" SG_ 1344 AC_LCD_Status 3;
BA_ "GenSigStartValue" SG_ 1344 AC_LCD_Status 1;
BA_ "GenSigInvalidValue" SG_ 866 LRI_Pressure 255;
BA_ "GenSigInvalidValue" SG_ 866 RRI_Pressure 255;
BA_ "GenSigInvalidValue" SG_ 865 Tire_Temperature 255;
BA_ "GenSigInvalidValue" SG_ 865 LR_Pressure 255;
BA_ "GenSigInvalidValue" SG_ 865 RR_Pressure 255;
BA_ "GenSigInvalidValue" SG_ 865 RF_Pressure 255;
BA_ "GenSigInvalidValue" SG_ 865 LF_Pressure 255;
BA_ "GenSigSendType" SG_ 82 PEPS_LearningSK64 3;
BA_ "GenSigSendType" SG_ 80 PEPS_EmsAuth 3;
BA_ "GenSigSendType" SG_ 420 PEPS_TBOXAuth 3;
BA_ "GenSigSendType" SG_ 421 PEPS_MaxTeleEngStartTimerfeedbac 3;
BA_ "SystemSignalLongSymbol" SG_ 421 PEPS_MaxTeleEngStartTimerfeedbac "PEPS_MaxTeleEngStartTimerfeedback";
BA_ "GenSigInvalidValue" SG_ 421 PEPS_StartrequestValid 1;
BA_ "GenSigSendType" SG_ 421 PEPS_StartrequestType 3;
BA_ "GenSigSendType" SG_ 804 PEPS_RKE_Command 3;
BA_ "GenSigSendType" SG_ 804 PEPS_Nea_LeaveToVehicle 3;
BA_ "GenSigSendType" SG_ 804 PEPS_KeyReminderUnlock 3;
BA_ "GenSigSendType" SG_ 806 RF_TurningLightLearningRemind 3;
BA_ "GenSigSendType" SG_ 806 RF_KeyLowBatteryWarning 3;
BA_ "GenSigStartValue" SG_ 806 RF_KeyLowBatteryWarning 1;
BA_ "GenSigSendType" SG_ 806 RF_RKE_Command 3;
BA_ "GenSigSendType" SG_ 898 MP5_BSDSoundSwitchSts 3;
BA_ "GenSigInvalidValue" SG_ 1347 EBS_Q_Discharge 65535;
BA_ "GenSigInvalidValue" SG_ 1347 EBS_Q_Charge 65535;
BA_ "GenSigInvalidValue" SG_ 1346 EBS_SOH_COR_STATE 3;
BA_ "GenSigInvalidValue" SG_ 1346 EBS_SOH_LAM_STATE 3;
BA_ "GenSigInvalidValue" SG_ 1346 EBS_SOFV_Restart_STATE 3;
BA_ "GenSigInvalidValue" SG_ 1346 EBS_SOFV_StopEnable_STATE 3;
BA_ "GenSigInvalidValue" SG_ 1346 EBS_SOH_SUL_STATE 3;
BA_ "GenSigInvalidValue" SG_ 1346 EBS_SOC_state 3;
BA_ "GenSigInvalidValue" SG_ 1346 EBS_SOH_COR 255;
BA_ "GenSigInvalidValue" SG_ 1346 EBS_SOH_LAM 255;
BA_ "GenSigInvalidValue" SG_ 1346 EBS_SOFV_Restart 255;
BA_ "GenSigInvalidValue" SG_ 1346 EBS_SOFV_StopEnable 255;
BA_ "GenSigInvalidValue" SG_ 1346 EBS_SOH_SUL 255;
BA_ "GenSigInvalidValue" SG_ 1346 EBS_SOC 255;
BA_ "GenSigInvalidValue" SG_ 1345 EBS_IBATT_QUIESCENT 255;
BA_ "GenSigStartValue" SG_ 1345 EBS_IBATT_QUIESCENT 255;
BA_ "GenSigInvalidValue" SG_ 1345 EBS_T_BATT 255;
BA_ "GenSigStartValue" SG_ 1345 EBS_T_BATT 255;
BA_ "GenSigInvalidValue" SG_ 1345 EBS_I_BATT 65535;
BA_ "GenSigStartValue" SG_ 1345 EBS_I_BATT 65535;
BA_ "GenSigInvalidValue" SG_ 1345 EBS_I_RANGE 3;
BA_ "GenSigStartValue" SG_ 1345 EBS_I_RANGE 3;
BA_ "GenSigInvalidValue" SG_ 1345 EBS_U_BATT 16383;
BA_ "GenSigStartValue" SG_ 1345 EBS_U_BATT 16383;
BA_ "SystemSignalLongSymbol" SG_ 789 BCM_RemoteBodyControlSettingStat "BCM_RemoteBodyControlSettingStatus";
BA_ "GenSigInvalidValue" SG_ 787 BCM_PowerModeInvalid 1;
BA_ "GenSigStartValue" SG_ 787 BCM_Reverse_gear 1;
BA_ "GenSigStartValue" SG_ 787 BCM_Start_Switch 1;
BA_ "GenSigInvalidValue" SG_ 787 BCM_OutsideTemp 255;
BA_ "GenSigStartValue" SG_ 787 BCM_OutsideTemp 254;
BA_ "GenSigStartValue" SG_ 787 BCM_Mechanical_Hand_Brake 1;
BA_ "GenSigStartValue" SG_ 787 BCM_RearDef_Status 1;
BA_ "GenSigStartValue" SG_ 787 BCM_BrakeFluidSts 1;
BA_ "GenSigStartValue" SG_ 792 BCM_BackHomeSts 1;
BA_ "GenSigStartValue" SG_ 792 BCM_AutolampSts 1;
BA_ "GenSigStartValue" SG_ 792 BCM_readinglampSts 1;
BA_ "GenSigStartValue" SG_ 792 BCM_Highmountedstoplamp 1;
BA_ "GenSigStartValue" SG_ 792 BCM_BrakelightSts 1;
BA_ "GenSigStartValue" SG_ 792 BCM_reversinglightSts 1;
BA_ "GenSigStartValue" SG_ 792 BCM_DayRunningLampSts 1;
BA_ "GenSigStartValue" SG_ 792 BCM_RearFogLmpSts 1;
BA_ "GenSigStartValue" SG_ 792 BCM_FrntFogLmpSts 1;
BA_ "GenSigStartValue" SG_ 792 BCM_PosLmpSts 1;
BA_ "GenSigStartValue" SG_ 792 BCM_LowBeamSts 1;
BA_ "GenSigStartValue" SG_ 792 BCM_HighBeamSts 1;
BA_ "GenSigStartValue" SG_ 784 BCM_FrontWiperSts 1;
BA_ "GenSigStartValue" SG_ 784 BCM_EnginehoodSts 1;
BA_ "GenSigStartValue" SG_ 784 BCM_DoorLockStsTrunk 1;
BA_ "GenSigStartValue" SG_ 784 BCM_DoorStsTrunk 1;
BA_ "GenSigStartValue" SG_ 784 BCM_DoorLockStsFrntLe 2;
BA_ "GenSigStartValue" SG_ 784 BCM_DoorStsRearRi 1;
BA_ "GenSigStartValue" SG_ 784 BCM_DoorStsRearLe 1;
BA_ "GenSigStartValue" SG_ 784 BCM_DoorStsFrntRi 1;
BA_ "GenSigStartValue" SG_ 784 BCM_DoorStsFrntLe 1;
VAL_ 423 TBOX_HornCmd 3 "Reserved" 2 "ON" 1 "OFF" 0 "NoRequest" ;
VAL_ 423 TBOX_TurnIndcrCtrlCmd 3 "Reserved" 2 "Blink" 1 "OFF" 0 "NoRequest" ;
VAL_ 423 TBOX_DoorLockCmd 3 "Invalid" 2 "Unlock" 1 "Lock" 0 "NoRequest" ;
VAL_ 1079 RTMNMAlive 1 "Active" 0 "Not active" ;
VAL_ 1079 RTMNMRing 1 "Active" 0 "Not active" ;
VAL_ 1079 RTMNMLimphome 1 "Active" 0 "Not active" ;
VAL_ 1079 RTMNMSleepInd 1 "Active" 0 "Not active" ;
VAL_ 1079 RTMNMSleepAck 1 "Active" 0 "Not active" ;
VAL_ 1075 MP5NMAlive 1 "Active" 0 "Not active" ;
VAL_ 1075 MP5NMRing 1 "Active" 0 "Not active" ;
VAL_ 1075 MP5NMLimphome 1 "Active" 0 "Not active" ;
VAL_ 1075 MP5NMSleepInd 1 "Active" 0 "Not active" ;
VAL_ 1075 MP5NMSleepAck 1 "Active" 0 "Not active" ;
VAL_ 1074 PEPSNMAlive 1 "Active" 0 "Not active" ;
VAL_ 1074 PEPSNMRing 1 "Active" 0 "Not active" ;
VAL_ 1074 PEPSNMLimphome 1 "Active" 0 "Not active" ;
VAL_ 1074 PEPSNMSleepInd 1 "Active" 0 "Not active" ;
VAL_ 1074 PEPSNMSleepAck 1 "Active" 0 "Not active" ;
VAL_ 1072 ICNMAlive 1 "Active" 0 "Not active" ;
VAL_ 1072 ICNMRing 1 "Active" 0 "Not active" ;
VAL_ 1072 ICNMLimphome 1 "Active" 0 "Not active" ;
VAL_ 1072 ICNMSleepInd 1 "Active" 0 "Not active" ;
VAL_ 1072 ICNMSleepAck 1 "Active" 0 "Not active" ;
VAL_ 1120 GWNMAlive 1 "Active" 0 "Not active" ;
VAL_ 1120 GWNMRing 1 "Active" 0 "Not active" ;
VAL_ 1120 GWNMLimphome 1 "Active" 0 "Not active" ;
VAL_ 1120 GWNMSleepInd 1 "Active" 0 "Not active" ;
VAL_ 1120 GWNMSleepAck 1 "Active" 0 "Not active" ;
VAL_ 1073 BCMNMAlive 1 "Active" 0 "Not active" ;
VAL_ 1073 BCMNMRing 1 "Active" 0 "Not active" ;
VAL_ 1073 BCMNMLimphome 1 "Active" 0 "Not active" ;
VAL_ 1073 BCMNMSleepInd 1 "Active" 0 "Not active" ;
VAL_ 1073 BCMNMSleepAck 1 "Active" 0 "Not active" ;
VAL_ 96 EMS_EngAuthentResult 2 "success" 1 "fail" 0 "no event" ;
VAL_ 581 IPM_LDWWarningType 3 "Reserved" 2 "wheelsteer shake" 1 "audible warning" 0 "audible warning and wheelsteer shake" ;
VAL_ 581 IPM_HMA_HighbeamReq 1 "high beam request." 0 "no request;" ;
VAL_ 581 IPM_HMA_Status 5 "camera blocked;" 4 "fault;" 3 "active;" 2 "standby;" 1 "passive;" 0 "off；" ;
VAL_ 581 IPM_LaneAssit_TorqueReqStatus 3 "reserved" 1 "torque request" 0 "no request" ;
VAL_ 581 IPM_LaneAssit_TorqueValidity 1 "Invalid" 0 "Valid" ;
VAL_ 581 IPM_LaneAssit_TorqueReq 2047 "Invalid" ;
VAL_ 581 IPM_DDD_IndexStatus 3 "DDD Invalid" 2 "DDD limited validity;" 1 "DDD valid;" 0 "Init state;" ;
VAL_ 581 IPM_DDD_WarningLevel 2 "Second warning issued" 1 "First warning issued;" 0 "Init state;" ;
VAL_ 581 IPM_SLASpdlimitUnits 3 "Reserved." 2 "MPH;" 1 "KMH;" 0 "Unknown;" ;
VAL_ 581 IPM_SLASpdlimit 27 "SPL 130;" 26 "SPL 125;" 25 "SPL 120;" 24 "SPL 115;" 23 "SPL 110;" 22 "SPL 105;" 21 "SPL 100;" 20 "SPL 95;" 19 "SPL 90;" 18 "SPL 85;" 17 "SPL 80;" 16 "SPL 75;" 15 "SPL 70;" 14 "SPL 65;" 13 "SPL 60;" 12 "SPL 55;" 11 "SPL 50;" 10 "SPL 45;" 9 "SPL 40;" 8 "SPL 35;" 7 "SPL 30;" 6 "SPL 25;" 5 "SPL 20;" 4 "SPL 15;" 3 "SPL 10;" 2 "SPL 5;" 1 "SPL Cancelled;" 0 "No Display;" ;
VAL_ 581 IPM_SLAState 4 "Defect;" 3 "Navigation only mode;" 2 "Vision mode;" 1 "Fusion mode;" 0 "Off;" ;
VAL_ 581 IPM_LaneAssit_WarningVibration 1 "active." 0 "inactive;" ;
VAL_ 581 IPM_LaneAssit_WarningAudio 1 "active." 0 "inactive;" ;
VAL_ 581 IPM_LaneAssit_Status 7 "Camera uncalibrated" 6 "Camera blocked;" 5 "Fault;" 4 "Active;" 3 "LDW Standby; LKA Active" 2 "LDW Active ；LKA Standby" 1 "Standby;" 0 "Off;" ;
VAL_ 581 IPM_LaneAssit_HandsonReq 1 "active." 0 "inactive;" ;
VAL_ 581 IPM_LaneAssit_Sensitivity 1 "lowSensitivity;" 0 "highSensitivity;" ;
VAL_ 581 IPM_LaneAssitType 6 "Reserved" 5 "TJA/ICA + LDW" 4 "TJA/ICA" 3 "LDW+LKA" 2 "LKA" 1 "LDW" 0 "Unavailable" ;
VAL_ 581 IPM_LaneAssit_RightVisualization 3 "warning." 2 "intervention;" 1 "line tracking;" 0 "no display;" ;
VAL_ 581 IPM_LaneAssit_LeftVisualization 3 "warning." 2 "intervention;" 1 "line tracking;" 0 "no display;" ;
VAL_ 629 DOA_OFFTelltale 1 "OFFTelltale on" 0 "OFFTelltlae off" ;
VAL_ 629 CTA_OFFTelltale 1 "OFFTelltale on" 0 "OFFTelltlae off" ;
VAL_ 629 SODLCA_OFFTelltale 1 "OFFTelltale on" 0 "OFFTelltlae off" ;
VAL_ 629 SOD_LCA_warningReqLeft 3 "reserved" 2 "warning level 2" 1 "warning level 1" 0 "no warning" ;
VAL_ 629 SOD_DOA_warningReqLeftRear 3 "reserved" 2 "warning level 2" 1 "warning level 1" 0 "no warning" ;
VAL_ 629 SOD_DOA_warningReqLeftFront 3 "reserved" 2 "warning level 2" 1 "warning level 1" 0 "no warning" ;
VAL_ 629 SOD_CTA_warningReqLeft 2 "warning level 2" 3 "reserved" 0 "no warning" ;
VAL_ 629 SOD_AutoAlignmentFlag 3 "reserved" 1 "Successful" 0 "no success" ;
VAL_ 629 SOD_BLIS_Active 3 "fail" 2 "active" 1 "stanby" 0 "no active" ;
VAL_ 629 SOD_BLIS_display 4 "Temporary error" 3 "SOD/LCA/CTA/DOA Uncalibration" 2 "SOD/LCA/CTA/DOA blindness" 1 "SOD/LCA/CTA/DOA error" 0 "no display" ;
VAL_ 629 SOD_LCA_warningReqRight 3 "reserved" 2 "warning level 2" 1 "warning level 1" 0 "no warning" ;
VAL_ 629 SOD_DOA_State 1 "Active" 0 "Inactive" ;
VAL_ 629 SOD_CTA_State 1 "Active" 0 "Inactive" ;
VAL_ 629 SOD_SODLCA_State 1 "Active" 0 "Inactive" ;
VAL_ 629 SOD_DOA_warningReqRightRear 3 "reserved" 2 "warning level 2" 1 "warning level 1" 0 "no warning" ;
VAL_ 629 SOD_DOA_warningReqRightFront 3 "reserved" 2 "warning level 2" 1 "warning level 1" 0 "no warning" ;
VAL_ 629 SOD_CTA_warningReqRight 2 "warning level 2" 1 "reserved" 0 "no warning" ;
VAL_ 625 PAM_ChimeCmdSoundCadence 12 "Tone 12 PAM successful tone" 11 "Tone 11  PAM warning tone" 10 "Tone 10 PAM failed tone" 9 "Tone 9" 8 "Tone 8" 7 "Tone 7" 6 "Tone 6" 5 "Tone 5" 4 "Tone 4" 3 "Tone 3" 2 "Tone 2" 1 "Tone 1" 0 "Tone 0 No warning" ;
VAL_ 625 PAM_ChimeCmdSoundStatus 3 "Front&RearSystemWarning" 2 "RearSystemWarning" 1 "FrontSystemWarning" 0 "NoWarning" ;
VAL_ 625 PAM_Sts 7 "Invalid" 6 "Terminated" 5 "Failure" 4 "Completed" 3 "Guidance active" 2 "Searching" 1 "Standby" 0 "Off" ;
VAL_ 625 PAM_RearSysTemWorkSts 3 "Failed" 2 "Active" 1 "Enable" 0 "Disable" ;
VAL_ 625 PAM_FrontSysTemWorkSts 3 "Failed" 2 "Active" 1 "Enable" 0 "Disable" ;
VAL_ 625 PAM_objectStsRRC 3 "object zone 3" 2 "object zone 2" 1 "object in zone 1" 0 "No object" ;
VAL_ 625 PAM_objectStsRRM 7 "object zone 7" 6 "object zone 6" 5 "object  zone 5" 4 "object zone 4" 3 "object zone 3" 2 "object zone 2" 1 "object in zone 1" 0 "No object" ;
VAL_ 625 PAM_objectStsRLM 7 "object zone 7" 6 "object zone 6" 5 "object  zone 5" 4 "object zone 4" 3 "object zone 3" 2 "object zone 2" 1 "object in zone 1" 0 "No object" ;
VAL_ 625 PAM_objectStsRLC 3 "object zone 3" 2 "object zone 2" 1 "object in zone 1" 0 "No object" ;
VAL_ 625 PAM_objectStsFRC 3 "object zone 3" 2 "object zone 2" 1 "object in zone 1" 0 "No object" ;
VAL_ 625 PAM_ObjectStsFRM 5 "object  zone 5" 4 "object zone 4" 3 "object zone 3" 2 "object zone 2" 1 "object in zone 1" 0 "No object" ;
VAL_ 625 PAM_ObjectStsFLM 5 "object  zone 5" 4 "object zone 4" 3 "object zone 3" 2 "object zone 2" 1 "object in zone 1" 0 "No object" ;
VAL_ 625 PAM_ObjectStsFLC 3 "object zone 3" 2 "object zone 2" 1 "object in zone 1" 0 "No object" ;
VAL_ 625 PAM_InfoDisplayReq 20 "系统外部故障" 19 "系统内部故障" 18 "自动泊车失败" 17 "自动泊车完成" 16 "自动泊车关闭" 15 "PAM开始接管方向盘确认周围环境安全" 14 "降低车辆速度到30km/h以下" 13 "开始右边平行出位" 11 "请选择平行出位方向" 10 "自动泊车不可用" 9 "请停车" 8 "请向前行驶" 7 "请向后倒车" 6 "请切换到前进档" 5 "请切换到倒车档" 4 "开始寻找左边的停车位垂直泊车" 3 "开始寻找右边的停车位垂直泊车" 2 "开始寻找左边的停车位平行泊车" 1 "开始寻找右边的停车位平行泊车" 0 "无显示信息" ;
VAL_ 625 PAM_ParkingBarSts 2 "Display on From bottom to top" 1 "Display on From top to bottom" 0 "Display off" ;
VAL_ 625 PAM_ParkingBarpercent 255 "Invalid" 10 "valid" 0 "Vaild" ;
VAL_ 1410 TBOX_RealTime_UB 1 "Update RealTime" 0 "Not Update RealTime" ;
VAL_ 1413 TBOX_OTATime 2 "2min" 1 "1min" 0 "NoRequest" ;
VAL_ 1413 TBOX_OTAType 3 "AppointmentUpgrade" 2 "UpgradeNow" 1 "SilentUpgrade" 0 "No Requet" ;
VAL_ 1413 TBOX_OTAStsFeedback 14 "NotReadyfor BCMOTAModeError" 13 "NotReadyfor PEPSOTAModeError" 12 "NotReadyfor WrongPowerMode" 11 "NotReadyforManyReasons" 10 "NotReadyfor Charging" 9 "NotReadyfor ExternalDiagnosticTool" 8 "NotReadyfor VehicleSpeedis equaltoZero" 7 "NotReadyfor EngineNotInEngineStopOrHVON" 6 "NotReadyfor HandBrakeorAPBNotInApplied" 5 "NotReadyfor GearNotInPorN" 4 "NotReadyfor IGNotON" 3 "NotReadyfor LowSOC" 2 "Ready" 1 "Standby" 0 "NoRequest" ;
VAL_ 1413 TBOX_OTAPowerModeRequest 3 "Reserved" 2 "IG ON" 1 "IG OFF" 0 "No Requet" ;
VAL_ 1413 TBOX_OTARequest 3 "Reserved" 2 "Quit OTA" 1 "OTA Request" 0 "No Requet" ;
VAL_ 418 TBOX_AcWorkCmd 4 "Manual（R）" 3 "Auto" 2 "Cooling" 1 "Heating" 0 "OFF" ;
VAL_ 417 TBOX_MaxTeleEngStartTimer 31 "Invalid" ;
VAL_ 417 TBOX_EngCtrlCmd 3 "IGONRequest" 2 "IGOFFRequest" 1 "Engine start" 0 "NoRequest" ;
VAL_ 291 TCU_StGearMode 15 "Invaild（如果无法锁定模式就发无效值）" 14 "ATS Fault TCU" 13 "Manual(For N330L)" 9 "Ghat(For N330L)" 8 "Sand" 7 "WetMud" 5 "4L" 4 "ECO" 3 "Sport" 2 "Manual" 1 "Snow" 0 "Standard" ;
VAL_ 291 TCU_available 1 "available" 0 "not available" ;
VAL_ 291 TCU_DriverIntervention 1 "Driver intervention" 0 "no intervention" ;
VAL_ 291 TCU_GearShiftInProgress 1 "Gear shift in progress" 0 "No gear shift in progress" ;
VAL_ 291 TCU_ShiftLeverPos_SBWM 7 "Invalid" 6 "Reserved" 5 "Blank" 4 "M" 3 "R" 2 "N" 1 "D" 0 "P" ;
VAL_ 291 TCU_DisplayGear 15 "Invalid" 13 "Current_gear_P" 11 "Current_gear_R" 14 "Reserved" 8 "Current_gear_8" 7 "Current_gear_7" 6 "Current_gear_6" 5 "Current_gear_5" 4 "Current_gear_4" 3 "Current_gear_3" 2 "Current_gear_2" 1 "Current_gear_1" 0 "Current_gear_N" ;
VAL_ 291 TCU_GearSelectorReq 15 "Invalid" 8 "M" 7 "R" 6 "N" 5 "D" 3 "3(Reserved)" 2 "2(Reserved)" 1 "L(Reserved)" 0 "P" ;
VAL_ 291 TCU_TargetGearReq 15 "Invalid" 14 "Reverse gear" 8 "8th gear" 7 "7th gear" 6 "6th gear" 5 "5th gear" 4 "4th gear" 3 "3rd gear" 2 "2nd gear" 1 "1st gear" 0 "Drive train open(Gear N)" ;
VAL_ 291 TCU_CurrentGearPosition 15 "Invalid" 14 "Reverse gear" 8 "8th gear" 7 "7th gear" 6 "6th gear" 5 "5th gear" 4 "4th gear" 3 "3rd gear" 2 "2nd gear" 1 "1st gear" 0 "Drive train open(Gear N)" ;
VAL_ 917 TCU_DrvShiftAllwCondRmd 7 "reserved" 6 "换档请按unlock键和踩刹车" 5 "换档请按unlock键" 4 "错误挂档，请将档杆挂回右侧" 3 "Velocity too high(换档请减速)" 2 "brake and deceleration(换档请减速和踩制动踏板)" 1 "brake apply(换档请踩制动踏板)" 0 "Normal" ;
VAL_ 917 TCU_Driverwarning 1 "error" 0 "no error" ;
VAL_ 917 TCU_Gearbox_Gonglimp 1 "error" 0 "no error" ;
VAL_ 917 Trans_Limphome 1 "error" 0 "no error" ;
VAL_ 917 TrnSrvcRqd_B_Rq 1 "Yes" 0 "No" ;
VAL_ 917 TCU_MILReq 1 "TCU requests MIL ON" 0 "No request" ;
VAL_ 872 EMS_DieslPrtcWarn_D_Rq 8 "Auto_ExhFilterCleanned" 7 "OCR_ExhFilterClean_Stopped" 6 "OCR_ExhFilterCleanned" 5 "Cleaning_Exhaust_Filter" 4 "DPF_OverLimit" 3 "RgnOff_AtLimit" 2 "RgnOff_OverLoaded" 1 "RgnOff_Loaded" 0 "DPF_Normal_Operation" ;
VAL_ 872 EMS_ManRgenTxt_D_RqDsply 4 "Cleaning Aborted/Stopped" 3 "Cleaning Completed" 2 "Cleaning In Progress" 1 "Cleaning Allowed" 0 "Cleaning Not Allowed" ;
VAL_ 872 DCM_GlowPlugLmpReq 3 "Not available" 1 "On" 0 "Off" ;
VAL_ 872 DCM_WIFFullLmpReq 3 "Not available" 1 "On" 0 "Off" ;
VAL_ 872 EMS_UreaWarn 3 "FlashChime slow" 2 "FlashChime quick" 1 "On" 0 "Off" ;
VAL_ 872 EMS_NoxWarning 3 "发现Nox排放故障继续行驶至无法起动" 2 "发现Nox排放故障继续行驶50公里后，未得到修复" 1 "发现尿素系统故障" 0 "No warning" ;
VAL_ 872 EMS_UreaSysWarning 3 "尿素中断添加故障继续行驶至无法起动" 2 "尿素中断添加故障继续行驶50公里后，未得到修复" 1 "发现尿素系统故障" 0 "No warning" ;
VAL_ 872 EMS_AddUreaWarning 3 "监测到尿素添加故障继续行驶至无法起动" 2 "尿素添加故障继续行驶50公里后，未得到修复" 1 "发现尿素系统故障" 0 "No warning" ;
VAL_ 872 EMS_UreaQty 3 "监测到尿素不合格故障继续行驶至无法起动" 2 "监测到尿素不合格故障继续行驶50公里后，未得到修复" 1 "监测到尿素系统故障" 0 "No warning" ;
VAL_ 872 EMS_UreaTxt 6 "System_Error" 5 "Urea_empty(persistence)" 4 "ExFlRange_ Level3（<=50km,persistence, or <=2.5%）" 3 "ExFlRange_ Level2（<=160km,persistence）" 2 "ExFlRange_ Level1（<=500km, or <=10%）" 1 "Exh_Fluid_Under_Half_Full" 0 "Exh_Fluid_Over_Half_Full" ;
VAL_ 870 EMS_OBDTxt 2 "Contaminated_OBD_forbiden_start(persistence, or 20km/h)" 1 "Contaminated_OBD_Level1（<=50km,persistence, or 75%troq）" 0 "NoProblem" ;
VAL_ 870 EMS_OBDWarn 3 "FlashChime slow" 2 "FlashChime quick" 1 "On" 0 "Off" ;
VAL_ 870 AT_EngExaustStatus 2 "Self learning limitation+shiftmap change" 1 "Self learning limitation" 0 "Normal（no request）" ;
VAL_ 870 EMS_EnergyFlow 5 "BrakingEnergyRecovery" 4 "StartStop" 3 "Driving and charging" 2 "Acceleration and assist" 1 "Idle for charging" 0 "Initial" ;
VAL_ 870 EMS_TargetGearPostion_MT 15 "Invalid" 14 "Reserved" 6 "Gear_6 Display" 5 "Gear_5 Display" 4 "Gear_4 Display" 3 "Gear_3 Display" 2 "Gear_2 Display" 1 "Gear_1 Display" 0 "Gear_N (no display)" ;
VAL_ 870 EMS_RemindShiftGear_MT 2 "Down Gear" 1 "UP Gear" 0 "No Remind" ;
VAL_ 870 EMS_EngType 3 "reserve" 1 "2.0T" 0 "1.5T" ;
VAL_ 870 EMS_MIL 1 "On" 0 "Off" ;
VAL_ 870 EMS_SVS 1 "On" 0 "Off" ;
VAL_ 870 EMS_StartStopStatus 3 "Start&Stop system fault" 2 "Start&Stop inactive未达到启停条件，仪表不显示状态灯" 1 "Start&Stop active达到启停条件，仪表显示启停过程中，仪表亮绿色状态灯" 0 "Start&Stop no function表示此车没有启停这个配置或者启停功能关闭" ;
VAL_ 267 EMS_EngSpeedError 1 "Error" 0 "No Error" ;
VAL_ 267 EMS_CluthPedalStatus 3 "Error" 2 "Reaerved" 1 "Pressed" 0 "NotPressed" ;
VAL_ 267 EMS_EngSpeed 32767 "Invalid" ;
VAL_ 267 EMS_EngOperationStatus 5 "Stalling (Reserved)" 4 "Cranking" 3 "DFCO (Reserved)" 2 "Idle" 1 "Running" 0 "Stopped" ;
VAL_ 267 EMS_AirCompressorStatus 1 "On" 0 "Off" ;
VAL_ 267 EMS_BatteryVoltageError 1 "warning" 0 "no warning" ;
VAL_ 267 EMS_BatterVoltage 255 "invalid" ;
VAL_ 267 EMS_EngCoolanTemp 255 "Invalid" ;
VAL_ 267 EMS_BrkPedalStasus 3 "Error" 2 "Reserved" 1 "Pressed" 0 "NotPressed" ;
VAL_ 337 EMS_ATSDrivingModeStatus 3 "Invalid" 2 "ATS Fault EMS（不能响应全地形功能发送）" 1 "Sport" 0 "Standard" ;
VAL_ 337 EMS_EngineStopStartStatus 7 "Reserved" 6 "EngineAuto-stopping 发动机自动停机" 5 "EngineOperation 发动机正常运转" 4 "EngineRestart 自动起动中的起动机脱离但未达到目标转速" 3 "StarterRestart 自动起动中的起动机拖动过程" 2 "EngineStopped 发动机处于停止(之前运行过，仍然KeyOn)" 1 "EngineStandby 发动机处于刚上电但尚未起动的状态，刚上电只会持续一小段" 0 "Non-start/Stop mode 起停功能被驾驶员禁止" ;
VAL_ 337 EMS_EngBarometricPressure 255 "Invalid" ;
VAL_ 337 EMS_VacuumPressure 1023 "Invalid" ;
VAL_ 337 EMS_EngOffTime 65535 "Invalid" ;
VAL_ 337 EMS_TargCruiseSpeed 511 "Invalid" ;
VAL_ 337 EMS_CruiseControlStatus 3 "Error" 2 "Standby" 1 "Active" 0 "CruiseControlOoff" ;
VAL_ 582 FCW_preWarning 0 "no warning" 1 "warning" ;
VAL_ 582 FCW_latentWarning 0 "no warning" 1 "warning" ;
VAL_ 582 MRR_PCW_STATE 5 "Reserved" 4 "Active" 3 "Active(no intervention)" 2 "Standby" 1 "Off" 0 "Unavailable" ;
VAL_ 582 MRR_AEB_STATE 5 "Reserved" 4 "Active" 3 "Active(no intervention)" 2 "Standby" 1 "Off" 0 "Unavailable" ;
VAL_ 582 MRR_ACC_Startstop_infor 3 "ACC_SystemFailure" 2 "ACC_StartRequest" 1 "ACC_StopForbidden" 0 "ACC_StopAllowed" ;
VAL_ 582 MRR_PCW_preWarning 0 "no warning" 1 "warning" ;
VAL_ 582 MRR_PCW_latentWarning 0 "no warning" 1 "warning" ;
VAL_ 582 ACCHMI_Mode 0 "OFF mode" 1 "Passive mode" 2 "Stand-By mode" 3 "Active-Control mode" 4 "Brake-Only mode" 5 "Override" 6 "Standstill" 7 "Failure mode" ;
VAL_ 582 MRR_FCW_Sensitive 3 "level3 High sensitive" 2 "level2 Normal" 1 "level1 Low sensitive" 0 "Unavailable" ;
VAL_ 582 MRR_ACCFailInfo 0 "no error" 1 "error" ;
VAL_ 582 MRR_TakeOverReq 0 "no TakeOver request" 1 "valid TakeOver request" ;
VAL_ 582 Textinfo 15 "reserved" 14 "ESP error" 13 "Override" 12 "Door open" 11 "Speed over 150kph" 10 "ESP off" 9 "Seatbelt unbuckled" 8 "No forward gear" 7 "EPB activate" 6 "ACC and PEBS error" 5 "MRR blindness" 4 "ACC Active" 3 "ACC is cancelled" 2 "ACC is switched off" 1 "ACC is switched on" 0 "No display" ;
VAL_ 582 MRR_ObjValid 0 "no object" 1 "target object detected" ;
VAL_ 582 MRR_TauGapSet 0 "tauGap_0" 1 "tauGap_1" 2 "tauGap_2" 3 "tauGap_3" 4 "tauGap_4" 5 "tauGap_5" 6 "tauGap_6" 7 "tauGap_7" ;
VAL_ 582 MRR_dxTarObj 0 "Distance_0" 1 "Distance_1" 2 "Distance_2" 3 "Distance_3" 4 "Distance_4" 5 "Distance_5" 6 "Distance_6" 7 "Distance_7" ;
VAL_ 582 MRR_vSetDis 511 "Invaild" ;
VAL_ 579 ESP_GearShiftPrevn 3 "Inhibit all shifts" 2 "Inhibit down shift" 1 "Inhibit upshift" 0 "No request" ;
VAL_ 579 ESP_EspEnableSts 1 "ESP enabled" 0 "ESP disabled" ;
VAL_ 579 ESP_ESPInfoLamp 1 "On" 0 "Off" ;
VAL_ 579 ESP_EspCtrlActv 1 "Active" 0 "Not active" ;
VAL_ 579 ESP_TcsCtrlActv 1 "Active" 0 "Not active" ;
VAL_ 579 ESP_TcsFlgFlt 1 "Failure" 0 "No failure" ;
VAL_ 579 ESP_VdcFlgFlt 1 "Failure" 0 "No failure" ;
VAL_ 579 ESP_Driving_mode_req 15 "Invaild" 14 "ATS Fault BCM" 8 "Sand" 7 "WetMud" 6 "Rock" 5 "4L" 4 "ECO" 3 "Sport" 2 "No used" 1 "Snow" 0 "Normal" ;
VAL_ 579 ESP_LdmBLC_BLRequestController 1 "illuminate" 0 "not illuminate" ;
VAL_ 579 ESP_CdpAvailable 1 "not available" 0 "available" ;
VAL_ 579 ESP_CdpActive 1 "active" 0 "not active" ;
VAL_ 579 ESP_HHCAvailable 1 "not available" 0 "available" ;
VAL_ 579 ESP_HHCActive 1 "active" 0 "not active" ;
VAL_ 579 ABS_HAZActive 1 "Active" 0 "Not active" ;
VAL_ 795 SWM_ACCLimpHomeSts 1 "LimpHome" 0 "Normal" ;
VAL_ 795 SWM_LaneAssistSwitch 0 "prevent LaneAssist control" 1 "enable LaneAssist control" ;
VAL_ 795 SWM_ACCtauGapSetMinus 0 "no press" 1 "pressed" ;
VAL_ 795 SWM_ACCtauGapSetPlus 0 "no press" 1 "pressed" ;
VAL_ 795 SWM_ACCvSetMinus 0 "no press" 1 "pressed" ;
VAL_ 795 SWM_ACCvSetPlus 0 "no press" 1 "pressed" ;
VAL_ 795 SWM_ACCSet 0 "no press" 1 "pressed" ;
VAL_ 795 SWM_ACCCancelResume 1 "pressed" 0 "no press" ;
VAL_ 795 SWM_ACCEnableSwitch 0 "prevent ACC control" 1 "enable ACC control" ;
VAL_ 794 SWM_Menu_Confirm 3 "Invalid" 2 "reserved" 1 "Pressed" 0 "Released" ;
VAL_ 794 SWM_Menu_Right 3 "Invalid" 2 "reserved" 1 "Pressed" 0 "Released" ;
VAL_ 794 SWM_Menu_Left 3 "Invalid" 2 "reserved" 1 "Pressed" 0 "Released" ;
VAL_ 794 SWM_Menu_Down 3 "Invalid" 2 "reserved" 1 "Pressed" 0 "Released" ;
VAL_ 794 SWM_Menu_Up 3 "Invalid" 2 "reserved" 1 "Pressed" 0 "Released" ;
VAL_ 794 SWM_VOICE 0 "no press" 1 "pressed" ;
VAL_ 794 SWM_MODE 0 "no press" 1 "pressed" ;
VAL_ 794 SWM_Next_Song 3 "Invalid" 2 "reserved" 1 "Pressed" 0 "Released" ;
VAL_ 794 SWM_Previous_Song 3 "Invalid" 2 "reserved" 1 "Pressed" 0 "Released" ;
VAL_ 794 SWM_VOL_Plus 3 "Invalid" 2 "reserved" 1 "Pressed" 0 "Released" ;
VAL_ 794 SWM_VOL_Minus 3 "Invalid" 2 "reserved" 1 "Pressed" 0 "Released" ;
VAL_ 794 SWM_RearFogLight 3 "Invalid" 2 "reserved" 1 "Pressed" 0 "Released" ;
VAL_ 794 SWM_FrontFogLight 3 "Invalid" 2 "reserved" 1 "ON" 0 "OFF" ;
VAL_ 794 SWM_HeadLamp 4 "Invalid" 3 "LowBeam" 2 "PositionLight" 1 "AutoLight" 0 "OFF" ;
VAL_ 794 SWM_FlashLightSts 3 "Invalid" 2 "reserved" 1 "Pressed" 0 "Released" ;
VAL_ 794 SWM_FrontWipingMode 7 "Invalid" 6 "Reserved" 4 "Front Auto/Interval wiping activation" 3 "Front Mist wiping activation" 2 "Front Wiper speed high activation" 1 "Front Wiper speed low activation" 0 "Front Wiping off" ;
VAL_ 794 SWM_TurnIndicationAct 3 "Invalid" 2 "Turn Right" 1 "Turn Left" 0 "Default" ;
VAL_ 794 SWM_WipingInterval_Sensitvity 7 "Invalid" 6 "reserved" 3 "Sensitivity 3" 2 "Sensitivity 2" 1 "Sensitivity 1" 0 "Sensitivity 0(most insensitive)" ;
VAL_ 794 SWM_HighBeam 3 "Invalid" 2 "reserved" 1 "Pressed" 0 "Released" ;
VAL_ 794 SWM_WasherLimpHomeSts 1 "LimpHome" 0 "Normal" ;
VAL_ 794 SWM_FWasherSts 3 "Invalid" 2 "reserved" 1 "Pressed" 0 "Released" ;
VAL_ 608 EPS_SASIndexSts 1 "SteerWheel at middle position" 0 "SteerWheel not at middle position" ;
VAL_ 608 EPS_F_ECUTempValid 1 "valid" 0 "Invalid" ;
VAL_ 608 EPS_St_EmergencyPowerLimit 1 "power density limit" 0 "normal" ;
VAL_ 608 EPS_St_EmergencyMotor 1 "servo motor fault" 0 "normal" ;
VAL_ 608 EPS_St_EmergencyECU 1 "ECU inner fault" 0 "normal" ;
VAL_ 608 EPS_St_EmergencyCANInterface 1 "CAN interface is fault" 0 "normal" ;
VAL_ 608 EPS_St_EmergencySensor 1 "sensor is fault" 0 "normal" ;
VAL_ 608 EPS_St_EmergencyOverTemp 1 "over temperature" 0 "normal" ;
VAL_ 608 EPS_St_EmergencyOverVoltage 1 "over voltage" 0 "normal" ;
VAL_ 608 EPS_St_EmergencyUnderVoltage 1 "under voltage" 0 "normal" ;
VAL_ 608 EPS_F_LoadInfo 1 "Fault" 0 "No Fault" ;
VAL_ 608 EPS_SASSoftLimitRightFlg 3 "Reserved" 2 "Learned" 1 "Primary learned(Only for CEPS)" 0 "No learned" ;
VAL_ 608 EPS_SASSoftLimitLeftFlg 3 "Reserved" 2 "Learned" 1 "Primary learned(Only for CEPS)" 0 "No learned" ;
VAL_ 608 EPS_St_DTCFlag 1 "DTC exist" 0 "no DTC exist" ;
VAL_ 608 EPS_S_WarningLampYellow 1 "open" 0 "close" ;
VAL_ 608 EPS_S_SafeLampRed 1 "open" 0 "close" ;
VAL_ 848 SRS_AirBagFailSts 3 "reserved" 2 "lamp on" 1 "lamp flash" 0 "lamp off" ;
VAL_ 848 SRS_SBR_Passenger 3 "Fault(Reserved)" 2 "Lamp On" 1 "Lamp Flashing(Reserved)" 0 "Lamp Off" ;
VAL_ 848 SRS_SBR_Driver 3 "Fault(Reserved)" 2 "Lamp On" 1 "Lamp Flashing(Reserved)" 0 "Lamp Off" ;
VAL_ 848 SRS_CrashOutputSts 1 "Crash" 0 "No crash" ;
VAL_ 530 ESP_vxwWheelRRValid 1 "Invalid" 0 "Valid" ;
VAL_ 530 ESP_vxwWheelRLValid 1 "Invalid" 0 "Valid" ;
VAL_ 530 ESP_vxwWheelFRValid 1 "Invalid" 0 "Valid" ;
VAL_ 530 ESP_vxwWheelFLValid 1 "Invalid" 0 "Valid" ;
VAL_ 530 ESP_vxwWheelRawRR 4095 "Invalid" ;
VAL_ 530 ESP_vxwWheelRawRL 4095 "Invalid" ;
VAL_ 530 ESP_vxwWheelRawFR 4095 "Invalid" ;
VAL_ 530 ESP_vxwWheelRawFL 4095 "Invalid" ;
VAL_ 545 ABS_WhlMilgFrntLeStatus 1 "Invalid" 0 "Valid" ;
VAL_ 545 ABS_WhlMilgFrntRiStatus 1 "Invalid" 0 "Valid" ;
VAL_ 545 ABS_VehSpdLgtStatus 2 "Init" 1 "Invalid" 0 "Valid" ;
VAL_ 545 ABS_AbsCtrlActv 1 "Active" 0 "Not active" ;
VAL_ 545 ABS_AbsFlgFlt 1 "Failure" 0 "No failure" ;
VAL_ 545 ABS_EbdFlgFlt 1 "Failure" 0 "No failure" ;
VAL_ 545 ABS_VehSpdDirection 1 "Backward" 0 "Forward" ;
VAL_ 545 ABS_VehSpdLgt 4095 "Invalid" ;
VAL_ 1317 IC_ManRgen_D_Rq 1 "Customer initiated regen" 0 "No customer request" ;
VAL_ 1317 IC_Fuel_Level_VolumnQF 3 "open circuit" 2 "Short" 1 "Normal" 0 "Invalid" ;
VAL_ 1317 IC_Fuel_Level_Volumn 8191 "Invalid" ;
VAL_ 1317 IC_AlarmStatus 3 "Reserved" 2 "Failed" 1 "Active" 0 "Inactive" ;
VAL_ 1317 IC_AlarmOrNot 1 "Alarm" 0 "No Alarm" ;
VAL_ 1317 IC_DTE 4095 "Invalid" ;
VAL_ 1317 IC_AFC 511 "Invalid" ;
VAL_ 1296 IC_DISFail 1 "error" 0 "no error" ;
VAL_ 1296 IC_QDashACCFail 3 "not defined" 2 "irreversible error" 1 "reversible error" 0 "no error" ;
VAL_ 1296 IC_VehSpd_HMI 511 "Invaild" ;
VAL_ 1296 IC_AirbagTelltaleBehavior 7 "Invalid" 4 "AirBagFailSts signal not received" 3 "no failure in the lamp Lamp is blinking" 2 "no failure in the lamp Lamp is on" 1 "failure in lamp" 0 "no failure in lamp and lamp is off" ;
VAL_ 1296 IC_OdometerMasterValue 16777215 "Invalid" ;
VAL_ 1333 MP5_DoorLockOnKeySetting 1 "Pressed" 0 "NoPressed" ;
VAL_ 1333 MP5_AutoWiperSetting 1 "ON" 0 "OFF" ;
VAL_ 1333 MP5_DayRunningLampsetting 1 "Pressed" 0 "NoPressed" ;
VAL_ 1333 MP5_FrontWiperMaintainSetting 1 "Pressed" 0 "NoPressed" ;
VAL_ 1333 MP5_RemoteBodyControlSetting 1 "Active" 0 "Inactive" ;
VAL_ 1333 MP5_RemoteStartSetting 1 "Active" 0 "Inactive" ;
VAL_ 1333 MP5_SmartLockSetting 1 "Active" 0 "Inactive" ;
VAL_ 1333 MP5_SpeedLockSetting 1 "Active" 0 "Inactive" ;
VAL_ 1333 MP5_RearDefrosterSetting 3 "Reserved" 2 "10" 1 "5" 0 "Invalid" ;
VAL_ 1333 MP5_RoomLampSetting 3 "15" 2 "10" 1 "5" 0 "Invalid" ;
VAL_ 1333 MP5_HomesafeLampSetting 4 "120" 3 "60" 2 "30" 1 "0(Close)" 0 "Invalid" ;
VAL_ 1330 MP5_DoorLock_Cmd 2 "Unlock" 1 "Lock" 0 "Invalid" ;
VAL_ 1328 MP5_PrdeProt_ON_OFF 1 "OFF" 0 "ON" ;
VAL_ 1328 MP5_DOA_Active 1 "OFF" 0 "ON" ;
VAL_ 1328 MP5_CTA_Active 1 "OFF" 0 "ON" ;
VAL_ 1328 MP5_BSDLCA_Active 1 "OFF" 0 "ON" ;
VAL_ 1328 MP5_DDDMenuReq 1 "OFF" 0 "ON" ;
VAL_ 1328 MP5_TSRMenuReq 1 "OFF" 0 "ON" ;
VAL_ 1328 MP5_IHCMenuReq 1 "OFF" 0 "ON" ;
VAL_ 1328 MP5_LDWWarning 3 "Reserved" 2 "wheelsteer shake" 1 "audible warning" 0 "audible warning and wheelsteer shake" ;
VAL_ 1328 MP5_LDWSensitvity 2 "Reserved" 1 "High" 0 "Low" ;
VAL_ 1328 MP5_LaneAssitTypeReq 3 "LDW+LKA" 2 "LKA" 1 "LDW" 0 "Unavailable" ;
VAL_ 1328 MP5_LDWLKASwitchSts 1 "OFF" 0 "ON" ;
VAL_ 1328 MP5_AlarmStatus 3 "Reserved" 2 "Failed" 1 "Active" 0 "Inactive" ;
VAL_ 1328 MP5_AlarmOrNot 1 "Alarm" 0 "No Alarm" ;
VAL_ 1328 MP5_AEB_ON_OFF 1 "switch off" 0 "switch on" ;
VAL_ 1328 MP5_FCW_ON_OFF 1 "switch off" 0 "switch on" ;
VAL_ 1328 MP5_BSDSwitchSts 1 "OFF" 0 "ON" ;
VAL_ 1328 MP5_FCW_Sensitive 3 "level3 High sensitive" 2 "level2 Normal" 1 "level1 Low sensitive" 0 "Unavailable" ;
VAL_ 1412 BCM_LoadManageLevel 3 "Reserved" 2 "Level 2  KOLMODE ACTIVE" 1 "Level 1 BatteryLow" 0 "Normal NoRequest" ;
VAL_ 1412 BCM_OTAModeStatus 5 "BCMOTAModeError" 4 "PEPSOTAModeError" 3 "WrongPowerMode" 2 "HandOverOTA" 1 "SwitchToOTA" 0 "Normal" ;
VAL_ 1412 BCM_OTAStsFeedback 14 "NotReadyfor BCMOTAModeError" 13 "NotReadyfor PEPSOTAModeError" 12 "NotReadyfor WrongPowerMode" 11 "NotReadyforManyReasons" 8 "NotReadyfor VehicleSpeedis equaltoZero" 7 "NotReadyfor EngineNotInEngineStopOrHVON" 5 "NotReadyfor GearNotInPorN" 10 "Reserved" 2 "Ready(整车条件满足)" 1 "Standby(收到T-BOX的OTA请求便进入整车条件判断阶段)" 0 "NoRequest" ;
VAL_ 1412 BCM_CarModeIndicator 5 "Factory Paused" 4 "Transport Paused" 3 "OTA" 2 "Factory" 1 "Transport" 0 "Normal" ;
VAL_ 1412 BCM_CarMode 4 "~0x7" 3 "OTA" 2 "Factory" 1 "Transport" 0 "Normal" ;
VAL_ 1344 AC_RemoteControlMode 3 "Other modes" 2 "Cooling" 1 "Heating" 0 "OFF" ;
VAL_ 1344 AC_Status 3 "Reserve" 2 "On" 1 "Off" 0 "Invalid" ;
VAL_ 1344 AC_TempSetStatus_Low 31 "Invalid" 17 "OFF" 16 "level 16" 15 "level 15" 14 "level 14" 13 "level 13" 12 "level 12" 11 "level 11" 10 "level 10" 9 "level 9" 8 "level 8" 7 "level 7" 6 "level 6" 5 "level 5" 4 "level 4" 3 "level 3" 2 "level 2" 1 "level 1" 0 "level 0" ;
VAL_ 1344 AC_Blower_Level 15 "Invalid" 0 "OFF（风量和图标不显示）" ;
VAL_ 1344 AC_Mode_Status 5 "Defrost" 4 "Foot and Defrost" 3 "Foot" 2 "Face and Foot" 1 "Face" 0 "Invalid" ;
VAL_ 1344 AC_Intake_Status 3 "OFF(不显示)" 2 "Recirculation" 1 "Fresh" 0 "Invalid" ;
VAL_ 1344 AC_LCD_Status 3 "Reserve" 2 "On" 1 "Off" 0 "Invalid" ;
VAL_ 773 AC_MaxVoltageRq 1 "Request" 0 "No request" ;
VAL_ 866 LRI_Pressure_Warning 7 "Low pressure warn&Quik leak(Reserved)" 6 "Sensor Faulture(Reserved)" 5 "Sensor battery low" 4 "Lost Sensor" 3 "Quik leakage(Reserved)" 2 "Low pressure warning" 1 "High pressure warning" 0 "No warning" ;
VAL_ 866 RRI_Pressure_Warning 7 "Low pressure warn&Quik leak(Reserved)" 6 "Sensor Faulture(Reserved)" 5 "Sensor battery low" 4 "Lost Sensor" 3 "Quik leakage(Reserved)" 2 "Low pressure warning" 1 "High pressure warning" 0 "No warning" ;
VAL_ 866 LRI_Pressure 255 "Invalid" ;
VAL_ 866 RRI_Pressure 255 "Invalid" ;
VAL_ 865 TPMS_Lamp_Status 3 "reseved" 2 "Lamp Light" 1 "Lamp Flash" 0 "No Lamp Light" ;
VAL_ 865 Tire_Position 7 "Reserved" 6 "LRI tire" 5 "RRI tire" 4 "Left Rear tire" 3 "Right Rear tire" 2 "Right Front tire" 1 "Left Front tire" 0 "No any sensor（error）" ;
VAL_ 865 resrved 1 "Reserved" ;
VAL_ 865 Temperature_Warning 1 "Temperature warning" 0 "No temperature warning" ;
VAL_ 865 LR_Pressure_Warning 7 "Low pressure warn&Quik leak(Reserved)" 6 "Sensor Faulture(Reserved)" 5 "Sensor battery low" 4 "Lost Sensor" 3 "Quik leakage(Reserved)" 2 "Low pressure warning" 1 "High pressure warning" 0 "No warning" ;
VAL_ 865 RR_Pressure_Warning 7 "Low pressure warn&Quik leak(Reserved)" 6 "Sensor Faulture(Reserved)" 5 "Sensor battery low" 4 "Lost Sensor" 3 "Quik leakage(Reserved)" 2 "Low pressure warning" 1 "High pressure warning" 0 "No warning" ;
VAL_ 865 System_Status 3 "Winter mode" 2 "Syetem wait for learning" 1 "System error" 0 "No any error" ;
VAL_ 865 RF_Pressure_Warning 7 "Low pressure warn&Quik leak(Reserved)" 6 "Sensor Faulture(Reserved)" 5 "Sensor battery low" 4 "Lost Sensor" 3 "Quik leakage(Reserved)" 2 "Low pressure warning" 1 "High pressure warning" 0 "No warning" ;
VAL_ 865 LF_Pressure_Warning 7 "Low pressure warn&Quik leak(Reserved)" 6 "Sensor Faulture(Reserved)" 5 "Sensor battery low" 4 "Lost Sensor" 3 "Quik leakage(Reserved)" 2 "Low pressure warning" 1 "High pressure warning" 0 "No warning" ;
VAL_ 865 Tire_Temperature 255 "Invalid" ;
VAL_ 865 LR_Pressure 255 "Invalid" ;
VAL_ 865 RR_Pressure 255 "Invalid" ;
VAL_ 865 RF_Pressure 255 "Invalid" ;
VAL_ 865 LF_Pressure 255 "Invalid" ;
VAL_ 421 PEPS_RemoteStartFaliureCode 207 "Engine Stop by gear shift isn’t P" 206 "Engine Stop by Anti-theft Warning" 205 "Start refuse by gear shift" 204 "Start refuse by engine speed" 203 "Start refuse by vehicle speed" 202 "Start refuse by power stage" 201 "power on refuse by power stage isn‘t OFF" 200 "engine start Fault by non- anti-theft status" 199 "Transition to normal power mode" 198 "Reset caused quiting" 197 "No Valid fob found" 88 "EMS authentication Faulture" 87 "Peps not learnt" 86 "CID found in cabin" 85 "Unexpected internal event (SSB push…..)（SSB press）" 84 "Engine has started but later stalls" 83 "Cranking Faults to start the engine" 82 "ESCL Faults to Unlock after 3 tries" 81 "TCU authentication Faults after 3 tries" 41 "Trunk Open" 40 "Engine forbid function not support" 39 "Brake/Clutch is pressed" 38 "Any door not Locked" 37 "Any door Opened(4door )" 36 "Voltage out of range" 35 "Door movement  triggering RS session normal termination" 34 "RS_Timeout" 33 "RS_Stop" 19 "RS_Running" 17 "RS_Started" 5 "Command validity via CAN is Invalid" 4 "Multiple command received" 3 "Communication error" 2 "other reason" 1 "Wrong command" 0 "Inactive" ;
VAL_ 421 PEPS_RemotePwrSplySts 3 "Start" 2 "ON" 1 "ACC" 0 "OFF" ;
VAL_ 421 PEPS_StartrequestValid 1 "Invalid" 0 "Valid" ;
VAL_ 421 PEPS_StartrequestType 7 "Reserved" 4 "Remote stop request" 3 "Remote start request" 2 "Normal  stop request" 1 "Normar start request" 0 "No action" ;
VAL_ 421 PEPS_Remotestartstatus 3 "Reserved" 2 "Remote start mode" 1 "Normar start mode" 0 "No start" ;
VAL_ 805 PEPS_OTAModeStatus 3 "WrongPowerMode" 2 "HandOverOTA" 1 "SwitchToOTA" 0 "Normal" ;
VAL_ 805 PEPS_OTAStatus 1 "OTAStatus" 0 "Normal" ;
VAL_ 805 PEPS_KeyBatteryWarning 1 "On" 0 "Off" ;
VAL_ 805 PEPS_KeyOutWarning1 1 "On" 0 "Off" ;
VAL_ 805 PEPS_NoKeyFoundWarning 1 "On" 0 "Off" ;
VAL_ 805 PEPS_KeyReminderWarning 1 "On" 0 "Off" ;
VAL_ 805 PEPS_ClutchIndicationWarning 1 "On" 0 "Off" ;
VAL_ 805 PEPS_BrakeIndicationWarning 1 "On" 0 "Off" ;
VAL_ 805 PEPS_ESCL_NotLockWarn 1 "On" 0 "Off" ;
VAL_ 805 PEPS_ESCL_NotUnlockWarning 1 "On" 0 "Off" ;
VAL_ 805 PEPS_Forbidden_FOB 4 "FOB_4 Forbidden" 3 "FOB_3 Forbidden" 2 "FOB_2 Forbidden" 1 "FOB_1 Forbidden" 0 "No Forbidden" ;
VAL_ 805 PEPS_CurrentValid_FOB 4 "FOB_4" 3 "FOB_3" 2 "FOB_2" 1 "FOB_1" 0 "No Valid FOB" ;
VAL_ 805 PEPS_SystemFailStatus 1 "Error" 0 "No Error" ;
VAL_ 805 PEPS_ESCL_FailStatus 1 "Error" 0 "No Error" ;
VAL_ 805 PEPS_SSB_FailStatus 1 "Error" 0 "No Error" ;
VAL_ 805 PEPS_NotNWarning 1 "On" 0 "Off" ;
VAL_ 805 PEPS_StartRequest 3 "Reserved" 2 "OFF Request" 1 "ON Request" 0 "No Request" ;
VAL_ 805 PEPS_IMMO_MatchStatus 3 "Matching 匹配中" 2 "Match failed 匹配失败" 1 "Match success 匹配成功" 0 "No Match 没有匹配" ;
VAL_ 805 PEPS_ClutchPedalStatus_MT 3 "Invalid" 2 "Pressed" 1 "No Pressed" 0 "Not available" ;
VAL_ 805 PEPS_BrakePedalStatus 3 "Invalid" 2 "Pressed" 1 "No Pressed" 0 "Not available" ;
VAL_ 805 PEPS_ESCL_LearningStatus 3 "reserved" 2 "Learnt" 1 "Virgin" 0 "Undefined" ;
VAL_ 805 PEPS_ESCL_LockStatus 3 "reserved" 2 "unlocked" 1 "locked" 0 "Inactive" ;
VAL_ 805 PEPS_IGN2RelayStsStatus 1 "Active" 0 "Inactive" ;
VAL_ 805 PEPS_IGN1RelayStsStatus 1 "Active" 0 "Inactive" ;
VAL_ 805 PEPS_PowerModeInvalid 1 "Invalid" 0 "Valid" ;
VAL_ 805 PEPS_PowerMode 3 "START" 2 "ON" 1 "ACC" 0 "OFF" ;
VAL_ 804 PEPS_EsclLockEnable 3 "LockDisable" 2 "LockEnable" 1 "NotUsed" 0 "Default" ;
VAL_ 804 PEPS_RemoteStartSettingStatus 1 "Active" 0 "Inactive" ;
VAL_ 804 PEPS_SmartLockSettingStatus 1 "Active" 0 "Inactive" ;
VAL_ 804 PEPS_RKE_Command 7 "WindowDown（遥控降窗）" 6 "WindowUp  (遥控升窗)" 5 "TailgateUnlock （行李箱解锁）" 4 "Search Press  (远程寻车)" 3 "Reserved" 2 "Unlock Press  (遥控解锁)" 1 "Lock Press  (遥控闭锁)" 0 "Invalide" ;
VAL_ 804 PEPS_Nea_LeaveToVehicle 5 "Welcome(控制迎宾灯)" 4 "LeaveVehicle" 3 "NearTailgate" 2 "Reserved" 1 "NearDriverDoor" 0 "None" ;
VAL_ 804 PEPS_KeyReminderUnlock 1 "Unlock" 0 "None" ;
VAL_ 806 RF_OperationStatus 3 "error(错误模式)" 2 "auto learning(诊断学习模式)" 1 "manual learning(手动学习模式)" 0 "idle(正常收发模式)" ;
VAL_ 806 RF_TurningLightLearningRemind 3 "learing exit" 2 "learning passed" 1 "start learning" 0 "Off" ;
VAL_ 806 RF_KeyLowBatteryWarning 1 "Warning" 0 "OFF" ;
VAL_ 806 RF_RKE_Command 7 "WindowDown（遥控降窗）" 6 "WindowUp  (遥控升窗)" 5 "TailgateUnlock （行李箱解锁）" 4 "Search Press  (寻车)" 3 "Reserved" 2 "Unlock Press  (遥控解锁)" 1 "Lock Press  (遥控闭锁)" 0 "Invalide" ;
VAL_ 902 IC_BSDSoundSts 1 "on" 0 "off" ;
VAL_ 898 MP5_BSDSoundSwitchSts 1 "on" 0 "off" ;
VAL_ 1347 EBS_Q_Discharge 65535 "Invalid" ;
VAL_ 1347 EBS_Q_Charge 65535 "Invalid" ;
VAL_ 1346 EBS_SOH_COR_STATE 3 "invalid" 2 "accurate (deviation<400mV)" 1 "inaccurate" 0 "not learned at all" ;
VAL_ 1346 EBS_SOH_LAM_STATE 3 "invalid" 1 "learned at least once" 0 "not learned at all" ;
VAL_ 1346 EBS_SOFV_Restart_STATE 3 "invalid" 1 "accurate (deviation<400mV)" 0 "inaccurate" ;
VAL_ 1346 EBS_SOFV_StopEnable_STATE 3 "invalid" 1 "accurate (deviation<400mV)" 0 "inaccurate" ;
VAL_ 1346 EBS_SOH_SUL_STATE 3 "invalid" 1 "learned" 0 "not learned" ;
VAL_ 1346 EBS_SOC_state 3 "invalid" 2 "deviation<10%" 1 "deviation<15%" 0 "deviation>15%" ;
VAL_ 1346 EBS_SOH_COR 255 "Invalid" ;
VAL_ 1346 EBS_SOH_LAM 255 "Invalid" ;
VAL_ 1346 EBS_SOFV_Restart 255 "Invalid" ;
VAL_ 1346 EBS_SOFV_StopEnable 255 "Invalid" ;
VAL_ 1346 EBS_SOH_SUL 255 "Invalid" ;
VAL_ 1346 EBS_SOC 255 "Invalid" ;
VAL_ 1345 EBS_FLAG_INCONSISTENCY 1 "Battery inconsistency" 0 "No battery inconsistency" ;
VAL_ 1345 EBS_Resp_Error 1 "Error" 0 "No error" ;
VAL_ 1345 EBS_Error_Ident 1 "Error" 0 "No error" ;
VAL_ 1345 EBS_Error_Calib 1 "Error" 0 "No error" ;
VAL_ 1345 EBS_Status_Temp 2 "LIN saturation(no HW defect)" 2832 "HW defect(ADC defect)" 1 "not used" 0 "No error" ;
VAL_ 1345 EBS_Status_Voltage 2 "LIN saturation(no HW defect)" 2832 "HW defect(ADC defect)" 1 "Error Open circuit" 0 "No error" ;
VAL_ 1345 EBS_Status_Current 2 "LIN saturation(no HW defect)" 2832 "HW defect(out of range or ADC defect)" 1 "Error Open circuit" 0 "No error" ;
VAL_ 1345 EBS_IBATT_QUIESCENT 255 "Invalid" 254 "Out of bounds" 253 "Overflow" ;
VAL_ 1345 EBS_T_BATT 255 "invalid" ;
VAL_ 1345 EBS_I_BATT 65535 "Invalid" ;
VAL_ 1345 EBS_I_RANGE 3 "Invalid" 2 "Current Range[-1500,1500A]" 1 "Current Range[-200,200A]" 0 "Current Range[-1,1A]" ;
VAL_ 1345 EBS_U_BATT 16383 "Invalid" ;
VAL_ 789 BCM_AutoWiperSettingStatus 1 "ON" 0 "OFF" ;
VAL_ 789 BCM_SpeedLockSettingStatus 1 "ON" 0 "OFF" ;
VAL_ 789 BCM_DayRunningLampsettingSts 1 "ON" 0 "OFF" ;
VAL_ 789 BCM_DoorLockOnKeySettingSts 1 "ON" 0 "OFF" ;
VAL_ 789 BCM_FrontWiperMaintainSettingSts 1 "ON" 0 "OFF" ;
VAL_ 789 BCM_RemoteBodyControlSettingStat 1 "Active" 0 "Inactive" ;
VAL_ 789 BCM_RearDefrosterSettingStatus 3 "Reserved" 2 "10" 1 "5" 0 "Invalid" ;
VAL_ 789 BCM_RoomLampSettingStatus 3 "15" 2 "10" 1 "5" 0 "Invalid" ;
VAL_ 789 BCM_HomesafeLampSettingStatus 4 "120" 3 "60" 2 "30" 1 "0(Close)" 0 "Invalid" ;
VAL_ 787 BCM_PowerModeInvalid 1 "Invalid" 0 "Valid" ;
VAL_ 787 BCM_PowerMode 3 "START" 2 "ON" 1 "ACC" 0 "OFF" ;
VAL_ 787 BCM_Reverse_gear 3 "Reserved" 2 "In Reverse Gear" 1 "Not in Reverse Gear" 0 "Invalid" ;
VAL_ 787 BCM_Start_Switch 3 "Reserved" 2 "StSwitchActive" 1 "StSwitchinactive" 0 "Invalid" ;
VAL_ 787 BCM_OutsideTempDig 2 "Open circuit" 1 "short circuit" 0 "NoFault" ;
VAL_ 787 BCM_OutsideTemp 255 "Invalid" ;
VAL_ 787 BCM_Mechanical_Hand_Brake 3 "Reserved" 2 "Locked" 1 "Released" 0 "Invalid" ;
VAL_ 787 BCM_RearDef_Status 3 "Reserved" 2 "On" 1 "Off" 0 "Invalid" ;
VAL_ 787 BCM_BrakeFluidSts 3 "Reserved" 2 "low" 1 "Normal" 0 "Invalid" ;
VAL_ 792 BCM_ImmoSts 3 "Match Success" 2 "EMS match failure" 1 "TP match failure" 0 "inactive" ;
VAL_ 792 BCM_DayRunningLampDig 1 "Fault" 0 "NoFault" ;
VAL_ 792 BCM_BrakelightDig 1 "Fault" 0 "NoFault" ;
VAL_ 792 BCM_reversinglightDig 1 "Fault" 0 "NoFault" ;
VAL_ 792 BCM_TurnIndicatorDig 1 "Fault" 0 "NoFault" ;
VAL_ 792 BCM_RearFogLmpDig 1 "Fault" 0 "NoFault" ;
VAL_ 792 BCM_PosLmpDig 1 "Fault" 0 "NoFault" ;
VAL_ 792 BCM_BackHomeSts 3 "Reserved" 2 "Active" 1 "Inactive" 0 "Invalid" ;
VAL_ 792 BCM_AutolampSts 3 "Reserved" 2 "Active" 1 "Inactive" 0 "No uesd" ;
VAL_ 792 BCM_readinglampSts 3 "Reserved" 2 "ON" 1 "OFF" 0 "No uesd" ;
VAL_ 792 BCM_Highmountedstoplamp 3 "Reserved" 2 "ON" 1 "OFF" 0 "No uesd" ;
VAL_ 792 BCM_BrakelightSts 3 "Reserved" 2 "ON" 1 "OFF" 0 "No uesd" ;
VAL_ 792 BCM_reversinglightSts 3 "Reserved" 2 "ON" 1 "OFF" 0 "No uesd" ;
VAL_ 792 BCM_DayRunningLampSts 3 "Reserved" 2 "ON" 1 "OFF" 0 "No uesd" ;
VAL_ 792 BCM_TurnIndicatorSts 3 "LeAndRiOn" 2 "RiOn" 1 "LeOn" 0 "Off" ;
VAL_ 792 BCM_RearFogLmpSts 3 "Reserved" 2 "ON" 1 "OFF" 0 "No uesd" ;
VAL_ 792 BCM_FrntFogLmpSts 3 "Reserved" 2 "ON" 1 "OFF" 0 "No uesd" ;
VAL_ 792 BCM_PosLmpSts 3 "Reserved" 2 "ON" 1 "OFF" 0 "No uesd" ;
VAL_ 792 BCM_LowBeamSts 3 "Reserved" 2 "ON" 1 "OFF" 0 "No uesd" ;
VAL_ 792 BCM_HighBeamSts 3 "Reserved" 2 "ON" 1 "OFF" 0 "No uesd" ;
VAL_ 784 BCM_EsclLockGndSts 3 "Not Used" 2 "Lock Gnd set Failed" 1 "Lock Gnd set  Successfull" 0 "Default" ;
VAL_ 784 BCM_FrontWiperSts 3 "High" 2 "Low" 1 "Off" 0 "No used" ;
VAL_ 784 BCM_EnginehoodSts 3 "Fault" 2 "Open" 1 "Closed" 0 "No used" ;
VAL_ 784 BCM_AntiTheftSts 3 "异常设防" 2 "报警" 1 "解除设防" 0 "设防" ;
VAL_ 784 BCM_LoadSensitivity 1 "Active" 0 "Inacitve" ;
VAL_ 784 BCM_LockUnlockFeedback 31 "Any other Unlock" 27 "钥匙遗忘车内解锁" 26 "诊断仪解锁" 25 "Tbox Unlcok" 24 "EngOFFUnlock 熄火解锁" 23 "KeyRemovalUnlock 拔钥匙解锁" 22 "CrashUnlock  碰撞解锁" 21 "Finger Unlock 机械钥匙解锁" 20 "Master Unlock 中控解锁" 19 "Near to vehicle Unlock" 18 "RKE Unlock" 17 "PE Unlock" 15 "Any other Lock" 12 "Tbox 30s autoLock" 11 "诊断仪闭锁" 10 "SpeedLock  车速上锁" 9 "Tbox Lock" 8 "Near to vehicle 30s autoLock" 7 "PE 30s autoLock" 6 "RKE 30s autoLock遥控自动回防" 5 "Finger Lock 机械钥匙上锁" 4 "Master Lock 中控锁" 3 "Leave Vehicle Lock" 2 "RKE Lock" 1 "PE Lock" 0 "No Lock/Unlock action" ;
VAL_ 784 BCM_DoorLockStsTrunk 3 "Fault" 2 "Unlocked" 1 "Locked" 0 "No Used" ;
VAL_ 784 BCM_DoorStsTrunk 3 "Fault" 2 "Open" 1 "Closed" 0 "No Used" ;
VAL_ 784 BCM_DoorLockStsRearRi 3 "Fault" 2 "Unlocked" 1 "Locked" 0 "No Used" ;
VAL_ 784 BCM_DoorLockStsRearLe 3 "Fault" 2 "Unlocked" 1 "Locked" 0 "No Used" ;
VAL_ 784 BCM_DoorLockStsFrntRi 3 "Fault" 2 "Unlocked" 1 "Locked" 0 "No Used" ;
VAL_ 784 BCM_DoorLockStsFrntLe 3 "Fault" 2 "Unlocked" 1 "Locked" 0 "No Used" ;
VAL_ 784 BCM_DoorStsRearRi 3 "Fault" 2 "Open" 1 "Closed" 0 "No Used" ;
VAL_ 784 BCM_DoorStsRearLe 3 "Fault" 2 "Open" 1 "Closed" 0 "No Used" ;
VAL_ 784 BCM_DoorStsFrntRi 3 "Fault" 2 "Open" 1 "Closed" 0 "No Used" ;
VAL_ 784 BCM_DoorStsFrntLe 3 "Fault" 2 "Open" 1 "Closed" 0 "No Used" ;
